VERSION ""

NS_ :

BS_:

BU_:

BO_ 711 CMPD_faultsAndExtras: 8 Vector__XXX
 SG_ CMPD_inputLVVoltage : 56|8@1+ (0.1,0) [0|0] "" Vector__XXX
 SG_ CMPD_inverterTemperature : 48|8@1+ (1,-40) [0|0] "" Vector__XXX
 SG_ CMPD_IGBTTemperature : 40|8@1+ (1,-40) [0|0] "" Vector__XXX
 SG_ CMPD_overloadDetectionOfSpeed : 32|1@1+ (1,0) [0|0] "" Vector__XXX
 SG_ CMPD_overloadRestrictionCurrent : 31|1@1+ (1,0) [0|0] "" Vector__XXX
 SG_ CMPD_overloadLossOfSync : 30|1@1+ (1,0) [0|0] "" Vector__XXX
 SG_ CMPD_overloadStartFaultDetection : 29|1@1+ (1,0) [0|0] "" Vector__XXX
 SG_ CMPD_overloadStatus : 27|2@1+ (1,0) [0|0] "" Vector__XXX
 SG_ CMPD_overCurrent : 26|1@1+ (1,0) [0|0] "" Vector__XXX
 SG_ CMPD_failedStartRepeated : 25|1@1+ (1,0) [0|0] "" Vector__XXX
 SG_ CMPD_failedStart : 24|1@1+ (1,0) [0|0] "" Vector__XXX
 SG_ CMPD_underTemperature : 23|1@1+ (1,0) [0|0] "" Vector__XXX
 SG_ CMPD_overTemperature : 22|1@1+ (1,0) [0|0] "" Vector__XXX
 SG_ CMPD_warnOverTemperature : 21|1@1+ (1,0) [0|0] "" Vector__XXX
 SG_ CMPD_shortCircuit : 20|1@1+ (1,0) [0|0] "" Vector__XXX
 SG_ CMPD_inverterOpenCircuit : 19|1@1+ (1,0) [0|0] "" Vector__XXX
 SG_ CMPD_internalPowerSupplyFault : 18|1@1+ (1,0) [0|0] "" Vector__XXX
 SG_ CMPD_selfTestFailCPU : 17|1@1+ (1,0) [0|0] "" Vector__XXX
 SG_ CMPD_currentSnsError : 16|1@1+ (1,0) [0|0] "" Vector__XXX
 SG_ CMPD_tempSnsFaultCPU : 15|1@1+ (1,0) [0|0] "" Vector__XXX
 SG_ CMPD_tempSnsFaultIPM2 : 14|1@1+ (1,0) [0|0] "" Vector__XXX
 SG_ CMPD_tempSnsFaultIPM1 : 13|1@1+ (1,0) [0|0] "" Vector__XXX
 SG_ CMPD_HVUnderVoltage : 12|1@1+ (1,0) [0|0] "" Vector__XXX
 SG_ CMPD_HVOverVoltage : 11|1@1+ (1,0) [0|0] "" Vector__XXX
 SG_ CMPD_LVOverVoltage : 10|1@1+ (1,0) [0|0] "" Vector__XXX
 SG_ CMPD_LVUnderVoltage : 9|1@1+ (1,0) [0|0] "" Vector__XXX
 SG_ CMPD_VCFRONTCANTimeout : 8|1@1+ (1,0) [0|0] "" Vector__XXX
 SG_ CMPD_limitOverCurrentHVDC : 2|1@1+ (1,0) [0|0] "" Vector__XXX
 SG_ CMPD_limitOverCurrentPhase : 1|1@1+ (1,0) [0|0] "" Vector__XXX
 SG_ CMPD_limitUnderVoltage : 0|1@1+ (1,0) [0|0] "" Vector__XXX

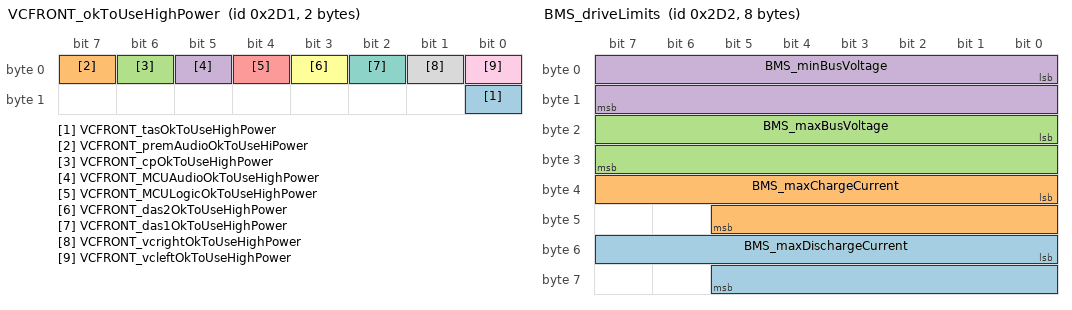
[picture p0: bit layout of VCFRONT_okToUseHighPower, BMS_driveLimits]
BO_ 721 VCFRONT_okToUseHighPower: 2 Vector__XXX
 SG_ VCFRONT_tasOkToUseHighPower : 8|1@1+ (1,0) [0|0] "" Vector__XXX
 SG_ VCFRONT_premAudioOkToUseHiPower : 7|1@1+ (1,0) [0|0] "" Vector__XXX
 SG_ VCFRONT_cpOkToUseHighPower : 6|1@1+ (1,0) [0|0] "" Vector__XXX
 SG_ VCFRONT_MCUAudioOkToUseHighPower : 5|1@1+ (1,0) [0|0] "" Vector__XXX
 SG_ VCFRONT_MCULogicOkToUseHighPower : 4|1@1+ (1,0) [0|0] "" Vector__XXX
 SG_ VCFRONT_das2OkToUseHighPower : 3|1@1+ (1,0) [0|0] "" Vector__XXX
 SG_ VCFRONT_das1OkToUseHighPower : 2|1@1+ (1,0) [0|0] "" Vector__XXX
 SG_ VCFRONT_vcrightOkToUseHighPower : 1|1@1+ (1,0) [0|0] "" Vector__XXX
 SG_ VCFRONT_vcleftOkToUseHighPower : 0|1@1+ (1,0) [0|0] "" Vector__XXX

BO_ 722 BMS_driveLimits: 8 Vector__XXX
 SG_ BMS_maxDischargeCurrent : 48|14@1+ (0.15,0) [0|0] "" Vector__XXX
 SG_ BMS_maxChargeCurrent : 32|14@1+ (0.1,0) [0|0] "" Vector__XXX
 SG_ BMS_maxBusVoltage : 16|16@1+ (0.02,0) [0|0] "" Vector__XXX
 SG_ BMS_minBusVoltage : 0|16@1+ (0.02,0) [0|0] "" Vector__XXX

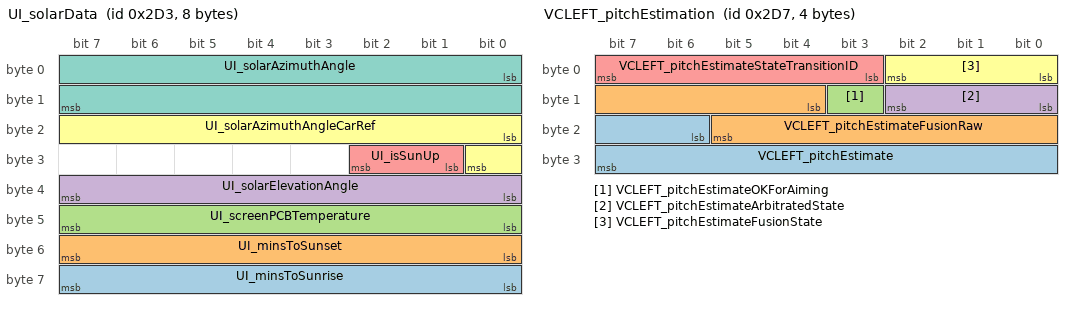
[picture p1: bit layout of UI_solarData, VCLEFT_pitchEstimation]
BO_ 723 UI_solarData: 8 Vector__XXX
 SG_ UI_minsToSunrise : 56|8@1+ (10,0) [0|0] "" Vector__XXX
 SG_ UI_minsToSunset : 48|8@1+ (10,0) [0|0] "" Vector__XXX
 SG_ UI_screenPCBTemperature : 40|8@1- (0.5,40) [0|0] "" Vector__XXX
 SG_ UI_solarElevationAngle : 32|8@1- (1,0) [0|0] "" Vector__XXX
 SG_ UI_isSunUp : 25|2@1+ (1,0) [0|0] "" Vector__XXX
 SG_ UI_solarAzimuthAngleCarRef : 16|9@1- (1,0) [0|0] "" Vector__XXX
 SG_ UI_solarAzimuthAngle : 0|16@1- (1,0) [0|0] "" Vector__XXX

BO_ 727 VCLEFT_pitchEstimation: 4 Vector__XXX
 SG_ VCLEFT_pitchEstimate : 22|10@1- (0.0002,0) [0|0] "" Vector__XXX
 SG_ VCLEFT_pitchEstimateFusionRaw : 12|10@1- (0.0002,0) [0|0] "" Vector__XXX
 SG_ VCLEFT_pitchEstimateOKForAiming : 11|1@1+ (1,0) [0|0] "" Vector__XXX
 SG_ VCLEFT_pitchEstimateArbitratedState : 8|3@1+ (1,0) [0|0] "" Vector__XXX
 SG_ VCLEFT_pitchEstimateStateTransitionID : 3|5@1+ (1,0) [0|0] "" Vector__XXX
 SG_ VCLEFT_pitchEstimateFusionState : 0|3@1+ (1,0) [0|0] "" Vector__XXX

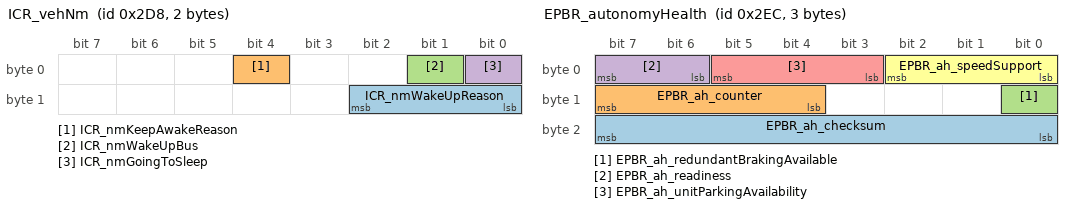
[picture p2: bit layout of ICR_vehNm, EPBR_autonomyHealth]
BO_ 728 ICR_vehNm: 2 Vector__XXX
 SG_ ICR_nmWakeUpReason : 8|3@1+ (1,0) [0|0] "" Vector__XXX
 SG_ ICR_nmKeepAwakeReason : 4|1@1+ (1,0) [0|0] "" Vector__XXX
 SG_ ICR_nmWakeUpBus : 1|1@1+ (1,0) [0|0] "" Vector__XXX
 SG_ ICR_nmGoingToSleep : 0|1@1+ (1,0) [0|0] "" Vector__XXX

BO_ 737 VCFRONT_status: 8 Vector__XXX
 SG_ VCFRONT_isActiveHeatingBattery m0 : 63|1@1+ (1,0) [0|0] "" Vector__XXX
 SG_ VCFRONT_frunkAccessPost m0 : 62|1@1+ (1,0) [0|0] "" Vector__XXX
 SG_ VCFRONT_headlampRightFanStatus m0 : 61|1@1+ (1,0) [0|0] "" Vector__XXX
 SG_ VCFRONT_extendedHvacPerfTestCommand m2 : 60|4@1+ (1,0) [0|0] "" Vector__XXX
 SG_ VCFRONT_headlampLeftFanStatus m0 : 60|1@1+ (1,0) [0|0] "" Vector__XXX
 SG_ VCFRONT_thermalPerfTestRunning m2 : 59|1@1+ (1,0) [0|0] "" Vector__XXX
 SG_ VCFRONT_frunkLatchType m0 : 58|2@1+ (1,0) [0|0] "" Vector__XXX
 SG_ VCFRONT_closeValvesRoutineStatus m2 : 57|2@1+ (1,0) [0|0] "" Vector__XXX
 SG_ VCFRONT_passengerBuckleStatus m0 : 57|1@1+ (1,0) [0|0] "" Vector__XXX
 SG_ VCFRONT_isCOP1Running m2 : 56|1@1+ (1,0) [0|0] "" Vector__XXX
 SG_ VCFRONT_limitedSplitTempDeltaEnforced m1 : 56|1@1+ (1,0) [0|0] "" Vector__XXX
 SG_ VCFRONT_windshieldCameraHeaterPower m4 : 56|6@1+ (2.5,0) [0|0] "" Vector__XXX
 SG_ VCFRONT_hvacReqOffForFasterCharge m1 : 55|1@1+ (1,0) [0|0] "" Vector__XXX
 SG_ VCFRONT_trunkExteriorWakeSwitch m0 : 55|1@1+ (1,0) [0|0] "" Vector__XXX
 SG_ VCFRONT_potentialRadiatorSteamUI m1 : 54|1@1+ (1,0) [0|0] "" Vector__XXX
 SG_ VCFRONT_refrigFillRoutineStatus m2 : 54|2@1+ (1,0) [0|0] "" Vector__XXX
 SG_ VCFRONT_potentialRadiatorSteam m1 : 53|1@1+ (1,0) [0|0] "" Vector__XXX
 SG_ VCFRONT_allowEvapInLowAmbient m1 : 52|1@1+ (1,0) [0|0] "" Vector__XXX
 SG_ VCFRONT_coolantFillRoutineStatus m2 : 52|2@1+ (1,0) [0|0] "" Vector__XXX
 SG_ VCFRONT_logVerbosity m3 : 52|3@1+ (1,0) [0|0] "" Vector__XXX
 SG_ VCFRONT_radarHeaterState m0 : 52|3@1+ (1,0) [0|0] "" Vector__XXX
 SG_ VCFRONT_activeLouverState m4 : 51|5@1+ (1,0) [0|0] "" Vector__XXX
 SG_ VCFRONT_espWakeLine m1 : 51|1@1+ (1,0) [0|0] "" Vector__XXX
 SG_ VCFRONT_hornOn m0 : 51|1@1+ (1,0) [0|0] "" Vector__XXX
 SG_ VCFRONT_anyDoorOpen m0 : 50|1@1+ (1,0) [0|0] "" Vector__XXX
 SG_ VCFRONT_anyClosureOpen m0 : 49|1@1+ (1,0) [0|0] "" Vector__XXX
 SG_ VCFRONT_hvacPerfTestCommand m2 : 49|3@1+ (1,0) [0|0] "" Vector__XXX
 SG_ VCFRONT_closureEasterEggState m1 : 48|3@1+ (1,0) [0|0] "" Vector__XXX
 SG_ VCFRONT_frunkInteriorRelSwitch m0 : 48|1@1+ (1,0) [0|0] "" Vector__XXX
 SG_ VCFRONT_occupantCount m1 : 45|3@1+ (1,0) [0|0] "" Vector__XXX
 SG_ VCFRONT_activeLouverOpenPos m4 : 44|7@1+ (1,0) [0|0] "" Vector__XXX
 SG_ VCFRONT_wiperHeaterState m1 : 42|3@1+ (1,0) [0|0] "" Vector__XXX
 SG_ VCFRONT_frunkLatchCurrent m0 : 40|8@1- (0.15748031496062992,0) [0|0] "" Vector__XXX
 SG_ VCFRONT_pressureRefrigDischarge m2 : 40|9@1+ (0.08,0) [0|0] "" Vector__XXX
 SG_ VCFRONT_vbatProt m3 : 40|12@1+ (0.005443676098,0) [0|0] "" Vector__XXX
 SG_ VCFRONT_wiperECUType m1 : 40|2@1+ (1,0) [0|0] "" Vector__XXX
 SG_ VCFRONT_maxHeatingPowerRightCC m4 : 37|7@1+ (100,0) [0|0] "" Vector__XXX
 SG_ VCFRONT_hibernationState m1 : 36|3@1+ (1,0) [0|0] "" Vector__XXX
 SG_ VCFRONT_wiperLINHealth m0 : 35|3@1+ (1,0) [0|0] "" Vector__XXX
 SG_ VCFRONT_lastUserPresenceUpdateEpochTime m5 : 32|32@1+ (1,0) [0|0] "" Vector__XXX
 SG_ VCFRONT_pressureRefrigSuction m2 : 32|7@1+ (0.125,0) [0|0] "" Vector__XXX
 SG_ VCFRONT_wiperHealth m0 : 32|3@1+ (1,0) [0|0] "" Vector__XXX
 SG_ VCFRONT_isHeatPumpOilPurgeActive m2 : 31|1@1+ (1,0) [0|0] "" Vector__XXX
 SG_ VCFRONT_isColdStartRunning m2 : 30|1@1+ (1,0) [0|0] "" Vector__XXX
 SG_ VCFRONT_maxHeatingPowerLeftCC m4 : 30|7@1+ (100,0) [0|0] "" Vector__XXX
 SG_ VCFRONT_hasLowRefrigerant m2 : 29|1@1+ (1,0) [0|0] "" Vector__XXX
 SG_ VCFRONT_AS8510Voltage m3 : 28|12@1+ (0.005443676098,0) [0|0] "" Vector__XXX
 SG_ VCFRONT_hvacModeNotAttainable m2 : 28|1@1+ (1,0) [0|0] "" Vector__XXX
 SG_ VCFRONT_compPerfRecoveryLimited m2 : 27|1@1+ (1,0) [0|0] "" Vector__XXX
 SG_ VCFRONT_chillerDemandActive m2 : 26|1@1+ (1,0) [0|0] "" Vector__XXX
 SG_ VCFRONT_isEvapOperationAllowed m2 : 25|1@1+ (1,0) [0|0] "" Vector__XXX
 SG_ VCFRONT_crashUnlockOverrideSet m0 : 24|1@1+ (1,0) [0|0] "" Vector__XXX
 SG_ VCFRONT_freezeEvapITerm m2 : 24|1@1+ (1,0) [0|0] "" Vector__XXX
 SG_ VCFRONT_sleepCurrent m1 : 24|12@1+ (0.125,-511.875) [0|0] "" Vector__XXX
 SG_ VCFRONT_crashState m0 : 22|2@1+ (1,0) [0|0] "" Vector__XXX
 SG_ VCFRONT_UP_chargeStateTransitioned m5 : 21|1@1+ (1,0) [0|0] "" Vector__XXX
 SG_ VCFRONT_UP_passengerPresent m5 : 20|1@1+ (1,0) [0|0] "" Vector__XXX
 SG_ VCFRONT_crashDetectedType m0 : 20|2@1+ (1,0) [0|0] "" Vector__XXX
 SG_ VCFRONT_UP_UIUserActivity m5 : 19|1@1+ (1,0) [0|0] "" Vector__XXX
 SG_ VCFRONT_compPowerSupportingPT m4 : 19|11@1+ (10,0) [0|0] "" Vector__XXX
 SG_ VCFRONT_UP_UIChargePortDoorRequest m5 : 18|1@1+ (1,0) [0|0] "" Vector__XXX
 SG_ VCFRONT_UP_chargePortDoorOpen m5 : 17|1@1+ (1,0) [0|0] "" Vector__XXX
 SG_ VCFRONT_UP_brakePressed m5 : 16|1@1+ (1,0) [0|0] "" Vector__XXX
 SG_ VCFRONT_minEvapHeatRejection m2 : 16|8@1+ (15,0) [0|0] "" Vector__XXX
 SG_ VCFRONT_vbatMonitorVoltage m3 : 16|12@1+ (0.005443676098,0) [0|0] "" Vector__XXX
 SG_ VCFRONT_wiperState m0 : 16|4@1+ (1,0) [0|0] "" Vector__XXX
 SG_ VCFRONT_UP_driverPresent m5 : 15|1@1+ (1,0) [0|0] "" Vector__XXX
 SG_ VCFRONT_wiperBlocked m0 : 15|1@1+ (1,0) [0|0] "" Vector__XXX
 SG_ VCFRONT_UP_anyClosureIsOpen m5 : 14|1@1+ (1,0) [0|0] "" Vector__XXX
 SG_ VCFRONT_UP_inTransportMode m5 : 13|1@1+ (1,0) [0|0] "" Vector__XXX
 SG_ VCFRONT_timeSpentSleeping m1 : 13|10@1+ (1,0) [0|0] "" Vector__XXX
 SG_ VCFRONT_HSDInitCompleteU16 m3 : 12|1@1+ (1,0) [0|0] "" Vector__XXX
 SG_ VCFRONT_UP_trunkOpen m5 : 12|1@1+ (1,0) [0|0] "" Vector__XXX
 SG_ VCFRONT_wiperPosition m0 : 12|3@1+ (1,0) [0|0] "" Vector__XXX
 SG_ VCFRONT_HSDInitCompleteU13 m3 : 11|1@1+ (1,0) [0|0] "" Vector__XXX
 SG_ VCFRONT_UP_rearPassengerDoorOpen m5 : 11|1@1+ (1,0) [0|0] "" Vector__XXX
 SG_ VCFRONT_PEResetLineState m3 : 10|1@1+ (1,0) [0|0] "" Vector__XXX
 SG_ VCFRONT_UP_rearDriverDoorOpen m5 : 10|1@1+ (1,0) [0|0] "" Vector__XXX
 SG_ VCFRONT_ChargePumpVoltageStable m3 : 9|1@1+ (1,0) [0|0] "" Vector__XXX
 SG_ VCFRONT_UP_frontPassengerDoorOpen m5 : 9|1@1+ (1,0) [0|0] "" Vector__XXX
 SG_ VCFRONT_UP_frontDriverDoorOpen m5 : 8|1@1+ (1,0) [0|0] "" Vector__XXX
 SG_ VCFRONT_compPowerSupportingHvac m4 : 8|11@1+ (10,0) [0|0] "" Vector__XXX
 SG_ VCFRONT_maxEvapHeatRejection m2 : 8|8@1+ (65,0) [0|0] "" Vector__XXX
 SG_ VCFRONT_railBState m3 : 8|1@1+ (1,0) [0|0] "" Vector__XXX
 SG_ VCFRONT_vehicleStatusDBG m1 : 8|5@1+ (1,0) [0|0] "" Vector__XXX
 SG_ VCFRONT_wiperSpeed m0 : 8|4@1+ (1,0) [0|0] "" Vector__XXX
 SG_ VCFRONT_UP_steeringWheelButtonInteraction m5 : 7|1@1+ (1,0) [0|0] "" Vector__XXX
 SG_ VCFRONT_cabinHeatingCapacityLimited m4 : 7|1@1+ (1,0) [0|0] "" Vector__XXX
 SG_ VCFRONT_railAState m3 : 7|1@1+ (1,0) [0|0] "" Vector__XXX
 SG_ VCFRONT_12VBRailStable m3 : 6|1@1+ (1,0) [0|0] "" Vector__XXX
 SG_ VCFRONT_UP_UIDisplayOnForUser m5 : 6|1@1+ (1,0) [0|0] "" Vector__XXX
 SG_ VCFRONT_cabinCoolingCapacityLimited m4 : 6|1@1+ (1,0) [0|0] "" Vector__XXX
 SG_ VCFRONT_12VARailStable m3 : 5|1@1+ (1,0) [0|0] "" Vector__XXX
 SG_ VCFRONT_UP_inDriveState m5 : 5|1@1+ (1,0) [0|0] "" Vector__XXX
 SG_ VCFRONT_iBoosterStateDBG m1 : 5|3@1+ (1,0) [0|0] "" Vector__XXX
 SG_ VCFRONT_5VBRailStable m3 : 4|1@1+ (1,0) [0|0] "" Vector__XXX
 SG_ VCFRONT_epasWakeLine m1 : 4|1@1+ (1,0) [0|0] "" Vector__XXX
 SG_ VCFRONT_5VARailStable m3 : 3|1@1+ (1,0) [0|0] "" Vector__XXX
 SG_ VCFRONT_frunkLatchStatus m0 : 3|4@1+ (1,0) [0|0] "" Vector__XXX
 SG_ VCFRONT_iBoosterWakeLine m1 : 3|1@1+ (1,0) [0|0] "" Vector__XXX
 SG_ VCFRONT_statusIndex M : 0|3@1+ (1,0) [0|0] "" Vector__XXX

BO_ 738 VCLEFT_seatStatus2: 8 Vector__XXX
 SG_ VC_AH_1RowLeftSeatHeatVentHealth m0 : 62|2@1+ (1,0) [0|0] "" Vector__XXX
 SG_ VC_AH_2RowCenterSeatHeatVentHealth m4 : 62|2@1+ (1,0) [0|0] "" Vector__XXX
 SG_ VC_AH_2RowLeftSeatHeatVentHealth m3 : 62|2@1+ (1,0) [0|0] "" Vector__XXX
 SG_ VC_AH_2RowRightSeatHeatVentHealth m5 : 62|2@1+ (1,0) [0|0] "" Vector__XXX
 SG_ VCLEFT_2RowSeatCenterSwitchVoltage m7 : 54|10@1+ (0.01,0) [0|0] "" Vector__XXX
 SG_ VCLEFT_rearCenterBuckleVoltage m2 : 52|8@1+ (0.02,0) [0|0] "" Vector__XXX
 SG_ VCLEFT_frontSeatHeatPowered m0 : 45|1@1+ (1,0) [0|0] "" Vector__XXX
 SG_ VCLEFT_rearCHeatPowered m4 : 45|1@1+ (1,0) [0|0] "" Vector__XXX
 SG_ VCLEFT_rearLBackHeatPowered m1 : 45|1@1+ (1,0) [0|0] "" Vector__XXX
 SG_ VCLEFT_rearLHeatPowered m3 : 45|1@1+ (1,0) [0|0] "" Vector__XXX
 SG_ VCLEFT_rearRCushionHeatPowered m5 : 45|1@1+ (1,0) [0|0] "" Vector__XXX
 SG_ VCLEFT_2RowSeatEasyEntrySwitchVoltage m7 : 44|10@1+ (0.01,0) [0|0] "" Vector__XXX
 SG_ VCLEFT_frontSeatHeatInhibited m0 : 44|1@1+ (1,0) [0|0] "" Vector__XXX
 SG_ VCLEFT_rearCHeatInhibited m4 : 44|1@1+ (1,0) [0|0] "" Vector__XXX
 SG_ VCLEFT_rearLBackHeatInhibited m1 : 44|1@1+ (1,0) [0|0] "" Vector__XXX
 SG_ VCLEFT_rearLHeatInhibited m3 : 44|1@1+ (1,0) [0|0] "" Vector__XXX
 SG_ VCLEFT_rearRCushionHeatInhibited m5 : 44|1@1+ (1,0) [0|0] "" Vector__XXX
 SG_ VCLEFT_rearRightOccupancyVoltage m2 : 44|8@1+ (0.02,0) [0|0] "" Vector__XXX
 SG_ VCLEFT_2RowSeatCenterActuatorDuty m6 : 40|12@1- (0.1,0) [0|0] "" Vector__XXX
 SG_ VCLEFT_frontSeatHeatTmpTarget m0 : 36|8@1- (0.5,0) [0|0] "" Vector__XXX
 SG_ VCLEFT_rearCHeatTmpTarget m4 : 36|8@1- (0.5,0) [0|0] "" Vector__XXX
 SG_ VCLEFT_rearCenterOccupancyVoltage m2 : 36|8@1+ (0.02,0) [0|0] "" Vector__XXX
 SG_ VCLEFT_rearLBackHeatTmpTarget m1 : 36|8@1- (0.5,0) [0|0] "" Vector__XXX
 SG_ VCLEFT_rearLHeatTmpTarget m3 : 36|8@1- (0.5,0) [0|0] "" Vector__XXX
 SG_ VCLEFT_rearRCushionHeatTmpTarget m5 : 36|8@1- (0.5,0) [0|0] "" Vector__XXX
 SG_ VCLEFT_2RowSeatReclineSwitchVoltage m7 : 34|10@1+ (0.01,0) [0|0] "" Vector__XXX
 SG_ VCLEFT_2RowSeatTrackPositionSwitch m9 : 31|2@1+ (1,0) [0|0] "" Vector__XXX
 SG_ VCLEFT_2RowSeatCenterActuatorCurrent m6 : 28|12@1- (0.01,0) [0|0] "" Vector__XXX
 SG_ VCLEFT_2RowSeatEasyEntryState m9 : 28|3@1+ (1,0) [0|0] "" Vector__XXX
 SG_ VCLEFT_rearLeftOccupancyVoltage m2 : 28|8@1+ (0.02,0) [0|0] "" Vector__XXX
 SG_ VCLEFT_frontSeatHeatTmp m0 : 24|12@1- (0.05,0) [0|0] "" Vector__XXX
 SG_ VCLEFT_frontSeatLiftTiltSwitchVoltage m7 : 24|10@1+ (0.01,0) [0|0] "" Vector__XXX
 SG_ VCLEFT_rearCHeatTmp m4 : 24|12@1- (0.05,0) [0|0] "" Vector__XXX
 SG_ VCLEFT_rearLBackHeatTmp m1 : 24|12@1- (0.05,0) [0|0] "" Vector__XXX
 SG_ VCLEFT_rearLHeatTmp m3 : 24|12@1- (0.05,0) [0|0] "" Vector__XXX
 SG_ VCLEFT_rearRCushionHeatTmp m5 : 24|12@1- (0.05,0) [0|0] "" Vector__XXX
 SG_ VCLEFT_rearLeftBuckleVoltage m2 : 20|8@1+ (0.02,0) [0|0] "" Vector__XXX
 SG_ VCLEFT_2RowSeatReclineActuatorDuty m6 : 16|12@1- (0.1,0) [0|0] "" Vector__XXX
 SG_ VCLEFT_2RowSeatTrackActuatorDuty m9 : 16|12@1- (0.1,0) [0|0] "" Vector__XXX
 SG_ VCLEFT_frontSeatHeatDuty m0 : 16|8@1+ (1,0) [0|0] "" Vector__XXX
 SG_ VCLEFT_rearCHeatDuty m4 : 16|8@1+ (1,0) [0|0] "" Vector__XXX
 SG_ VCLEFT_rearLBackHeatDuty m1 : 16|8@1+ (1,0) [0|0] "" Vector__XXX
 SG_ VCLEFT_rearLHeatDuty m3 : 16|8@1+ (1,0) [0|0] "" Vector__XXX
 SG_ VCLEFT_rearRCushionHeatDuty m5 : 16|8@1+ (1,0) [0|0] "" Vector__XXX
 SG_ VCLEFT_frontSeatLumbarSwitchVoltage m7 : 14|10@1+ (0.01,0) [0|0] "" Vector__XXX
 SG_ VCLEFT_trunkFoldFlatRightSwitchVoltage m8 : 14|10@1+ (0.01,0) [0|0] "" Vector__XXX
 SG_ VCLEFT_frontBuckleVoltage m2 : 12|8@1+ (0.02,0) [0|0] "" Vector__XXX
 SG_ VCLEFT_2RowSeatReclineActuatorCurrent m6 : 4|12@1- (0.01,0) [0|0] "" Vector__XXX
 SG_ VCLEFT_2RowSeatTrackActuatorCurrent m9 : 4|12@1- (0.01,0) [0|0] "" Vector__XXX
 SG_ VCLEFT_frontOccupancyVoltage m2 : 4|8@1+ (0.02,0) [0|0] "" Vector__XXX
 SG_ VCLEFT_frontSeatHeatCurrent m0 : 4|12@1+ (0.01,0) [0|0] "" Vector__XXX
 SG_ VCLEFT_frontSeatTrackBackrestSwitchVoltage m7 : 4|10@1+ (0.01,0) [0|0] "" Vector__XXX
 SG_ VCLEFT_rearCHeatCurrent m4 : 4|12@1+ (0.01,0) [0|0] "" Vector__XXX
 SG_ VCLEFT_rearLBackHeatCurrent m1 : 4|12@1+ (0.01,0) [0|0] "" Vector__XXX
 SG_ VCLEFT_rearLHeatCurrent m3 : 4|12@1+ (0.01,0) [0|0] "" Vector__XXX
 SG_ VCLEFT_rearRCushionHeatCurrent m5 : 4|12@1+ (0.01,0) [0|0] "" Vector__XXX
 SG_ VCLEFT_trunkFoldFlatLeftSwitchVoltage m8 : 4|10@1+ (0.004887585532746823,0) [0|0] "" Vector__XXX
 SG_ VCLEFT_seatStatus2Index M : 0|4@1+ (1,0) [0|0] "" Vector__XXX

BO_ 739 VCRIGHT_seatStatus2: 7 Vector__XXX
 SG_ VC_AH_1RowRightSeatHeatVentHealth m0 : 54|2@1+ (1,0) [0|0] "" Vector__XXX
 SG_ VCRIGHT_occupantClassificationHoldState m4 : 46|2@1+ (1,0) [0|0] "" Vector__XXX
 SG_ VCRIGHT_frontSeatHeatPowered m0 : 45|1@1+ (1,0) [0|0] "" Vector__XXX
 SG_ VCRIGHT_rearCSeatHeatPowered m2 : 45|1@1+ (1,0) [0|0] "" Vector__XXX
 SG_ VCRIGHT_rearLSeatHeatPowered m1 : 45|1@1+ (1,0) [0|0] "" Vector__XXX
 SG_ VCRIGHT_rearRSeatHeatPowered m3 : 45|1@1+ (1,0) [0|0] "" Vector__XXX
 SG_ VCRIGHT_2RowSeatEasyEntrySwitchVoltage m7 : 44|10@1+ (0.01,0) [0|0] "" Vector__XXX
 SG_ VCRIGHT_frontSeatHeatInhibited m0 : 44|1@1+ (1,0) [0|0] "" Vector__XXX
 SG_ VCRIGHT_rearCSeatHeatInhibited m2 : 44|1@1+ (1,0) [0|0] "" Vector__XXX
 SG_ VCRIGHT_rearLSeatHeatInhibited m1 : 44|1@1+ (1,0) [0|0] "" Vector__XXX
 SG_ VCRIGHT_rearRSeatHeatInhibited m3 : 44|1@1+ (1,0) [0|0] "" Vector__XXX
 SG_ VCRIGHT_frontSeatHeatTmpTarget m0 : 36|8@1- (0.5,0) [0|0] "" Vector__XXX
 SG_ VCRIGHT_rearCSeatHeatTmpTarget m2 : 36|8@1- (0.5,0) [0|0] "" Vector__XXX
 SG_ VCRIGHT_rearLSeatHeatTmpTarget m1 : 36|8@1- (0.5,0) [0|0] "" Vector__XXX
 SG_ VCRIGHT_rearRSeatHeatTmpTarget m3 : 36|8@1- (0.5,0) [0|0] "" Vector__XXX
 SG_ VCRIGHT_2RowSeatReclineSwitchVoltage m7 : 34|10@1+ (0.01,0) [0|0] "" Vector__XXX
 SG_ VCRIGHT_rearRightBuckleVoltage m4 : 34|10@1+ (0.01,0) [0|0] "" Vector__XXX
 SG_ VCRIGHT_ocsIEEState m10 : 32|3@1+ (1,0) [0|0] "" Vector__XXX
 SG_ VCRIGHT_2RowSeatTrackPositionSwitch m9 : 31|2@1+ (1,0) [0|0] "" Vector__XXX
 SG_ VCRIGHT_2RowSeatEasyEntryState m9 : 28|3@1+ (1,0) [0|0] "" Vector__XXX
 SG_ VCRIGHT_3RUSBPortsCurrentAvg m6 : 28|8@1+ (0.01,0) [0|0] "" Vector__XXX
 SG_ VCRIGHT_frontSeatHeatTmp m0 : 24|12@1- (0.05,0) [0|0] "" Vector__XXX
 SG_ VCRIGHT_frontSeatLiftTiltSwitchVoltage m7 : 24|10@1+ (0.01,0) [0|0] "" Vector__XXX
 SG_ VCRIGHT_rearCSeatHeatTmp m2 : 24|12@1- (0.05,0) [0|0] "" Vector__XXX
 SG_ VCRIGHT_rearCenterBuckleVoltage m4 : 24|10@1+ (0.01,0) [0|0] "" Vector__XXX
 SG_ VCRIGHT_rearLSeatHeatTmp m1 : 24|12@1- (0.05,0) [0|0] "" Vector__XXX
 SG_ VCRIGHT_rearRSeatHeatTmp m3 : 24|12@1- (0.05,0) [0|0] "" Vector__XXX
 SG_ VCRIGHT_ocsIEEPowerCurrent m10 : 20|12@1+ (0.001,0) [0|0] "" Vector__XXX
 SG_ VCRIGHT_ocsIEESnsrPassSeatCalRespSts m10 : 18|2@1+ (1,0) [0|0] "" Vector__XXX
 SG_ VCRIGHT_ocsIEEReqOfClrOfFlt m10 : 17|1@1+ (1,0) [0|0] "" Vector__XXX
 SG_ VCRIGHT_2RowSeatReclineActuatorDuty m6 : 16|12@1- (0.1,0) [0|0] "" Vector__XXX
 SG_ VCRIGHT_2RowSeatTrackActuatorDuty m9 : 16|12@1- (0.1,0) [0|0] "" Vector__XXX
 SG_ VCRIGHT_frontSeatHeatDuty m0 : 16|8@1+ (1,0) [0|0] "" Vector__XXX
 SG_ VCRIGHT_ocsIEEReqOfPassSeatCal m10 : 16|1@1+ (1,0) [0|0] "" Vector__XXX
 SG_ VCRIGHT_rearCSeatHeatDuty m2 : 16|8@1+ (1,0) [0|0] "" Vector__XXX
 SG_ VCRIGHT_rearLSeatHeatDuty m1 : 16|8@1+ (1,0) [0|0] "" Vector__XXX
 SG_ VCRIGHT_rearRSeatHeatDuty m3 : 16|8@1+ (1,0) [0|0] "" Vector__XXX
 SG_ VCRIGHT_ocsIEEFltResp8 m10 : 15|1@1+ (1,0) [0|0] "" Vector__XXX
 SG_ VCRIGHT_3RowSeatRightReclineSwitchVoltage m8 : 14|10@1+ (0.01,0) [0|0] "" Vector__XXX
 SG_ VCRIGHT_frontBuckleVoltage m4 : 14|10@1+ (0.01,0) [0|0] "" Vector__XXX
 SG_ VCRIGHT_frontSeatLumbarSwitchVoltage m7 : 14|10@1+ (0.01,0) [0|0] "" Vector__XXX
 SG_ VCRIGHT_ocsIEEFltResp7 m10 : 14|1@1+ (1,0) [0|0] "" Vector__XXX
 SG_ VCRIGHT_ocsIEEFltResp6 m10 : 13|1@1+ (1,0) [0|0] "" Vector__XXX
 SG_ VCRIGHT_ocsIEEFltResp5 m10 : 12|1@1+ (1,0) [0|0] "" Vector__XXX
 SG_ VCRIGHT_ocsIEEFltResp4 m10 : 11|1@1+ (1,0) [0|0] "" Vector__XXX
 SG_ VCRIGHT_ocsIEEFltResp3 m10 : 10|1@1+ (1,0) [0|0] "" Vector__XXX
 SG_ VCRIGHT_ocsIEEFltResp2 m10 : 9|1@1+ (1,0) [0|0] "" Vector__XXX
 SG_ VCRIGHT_ocsIEEFltResp1 m10 : 8|1@1+ (1,0) [0|0] "" Vector__XXX
 SG_ VCRIGHT_ocsIEEMIA m10 : 7|1@1+ (1,0) [0|0] "" Vector__XXX
 SG_ VCRIGHT_ocsIEEEcuFailr m10 : 6|1@1+ (1,0) [0|0] "" Vector__XXX
 SG_ VCRIGHT_2RowSeatReclineActuatorCurrent m6 : 4|12@1- (0.01,0) [0|0] "" Vector__XXX
 SG_ VCRIGHT_2RowSeatTrackActuatorCurrent m9 : 4|12@1- (0.01,0) [0|0] "" Vector__XXX
 SG_ VCRIGHT_3RowSeatLeftReclineSwitchVoltage m8 : 4|10@1+ (0.01,0) [0|0] "" Vector__XXX
 SG_ VCRIGHT_frontOccupancyVoltage m4 : 4|10@1+ (0.01,0) [0|0] "" Vector__XXX
 SG_ VCRIGHT_frontSeatHeatCurrent m0 : 4|12@1+ (0.01,0) [0|0] "" Vector__XXX
 SG_ VCRIGHT_frontSeatTrackBackrestSwitchVoltage m7 : 4|10@1+ (0.01,0) [0|0] "" Vector__XXX
 SG_ VCRIGHT_ocsIEEAirbAllwdSts m10 : 4|2@1+ (1,0) [0|0] "" Vector__XXX
 SG_ VCRIGHT_rearCSeatHeatCurrent m2 : 4|12@1+ (0.01,0) [0|0] "" Vector__XXX
 SG_ VCRIGHT_rearLSeatHeatCurrent m1 : 4|12@1+ (0.01,0) [0|0] "" Vector__XXX
 SG_ VCRIGHT_rearRSeatHeatCurrent m3 : 4|12@1+ (0.01,0) [0|0] "" Vector__XXX
 SG_ VCRIGHT_seatStatus2Index M : 0|4@1+ (1,0) [0|0] "" Vector__XXX

BO_ 744 EPBR_status: 8 Vector__XXX
 SG_ EPBR_statusChecksum : 56|8@1+ (1,0) [0|0] "" Vector__XXX
 SG_ EPBR_statusCounter : 52|4@1+ (1,0) [0|0] "" Vector__XXX
 SG_ EPBR_blockDrive : 51|1@1+ (1,0) [0|0] "" Vector__XXX
 SG_ EPBR_bothDisconnected : 50|1@1+ (1,0) [0|0] "" Vector__XXX
 SG_ EPBR_winchModeAvailable : 49|1@1+ (1,0) [0|0] "" Vector__XXX
 SG_ EPBR_hornRequest : 48|1@1+ (1,0) [0|0] "" Vector__XXX
 SG_ EPBR_okToPark : 47|1@1+ (1,0) [0|0] "" Vector__XXX
 SG_ EPBR_espPowerRequest : 46|1@1+ (1,0) [0|0] "" Vector__XXX
 SG_ EPBR_showStalkFaultedOnUi : 45|1@1+ (1,0) [0|0] "" Vector__XXX
 SG_ EPBR_autonomyBehavior : 43|2@1+ (1,0) [0|0] "" Vector__XXX
 SG_ EPBR_contactorCycleNotNeededForWinchEntry : 35|1@1+ (1,0) [0|0] "" Vector__XXX
 SG_ EPBR_uiWinchModeLvStatus : 33|2@1+ (1,0) [0|0] "" Vector__XXX
 SG_ EPBR_showUiGearShifter : 32|1@1+ (1,0) [0|0] "" Vector__XXX
 SG_ EPBR_brakeDiscWipeRequest : 30|2@1+ (1,0) [0|0] "" Vector__XXX
 SG_ EPBR_uiParkAvailable : 28|2@1+ (1,0) [0|0] "" Vector__XXX
 SG_ EPBR_cdpRequest : 27|1@1+ (1,0) [0|0] "" Vector__XXX
 SG_ EPBR_winchModePending : 26|1@1+ (1,0) [0|0] "" Vector__XXX
 SG_ EPBR_winchModePermissive : 25|1@1+ (1,0) [0|0] "" Vector__XXX
 SG_ EPBR_updateMode : 24|1@1+ (1,0) [0|0] "" Vector__XXX
 SG_ EPBR_winchModeActive : 23|1@1+ (1,0) [0|0] "" Vector__XXX
 SG_ EPBR_uiWinchModeMiscBlocking : 22|1@1+ (1,0) [0|0] "" Vector__XXX
 SG_ EPBR_requestUserConfirmation : 21|1@1+ (1,0) [0|0] "" Vector__XXX
 SG_ EPBR_brakeConfirmedPressed : 20|1@1+ (1,0) [0|0] "" Vector__XXX
 SG_ EPBR_epbConfigMismatch : 19|1@1+ (1,0) [0|0] "" Vector__XXX
 SG_ EPBR_brakeLight : 18|1@1+ (1,0) [0|0] "" Vector__XXX
 SG_ EPBR_summonEnabled : 17|1@1+ (1,0) [0|0] "" Vector__XXX
 SG_ EPBR_redundantBrakingEnabled : 16|1@1+ (1,0) [0|0] "" Vector__XXX
 SG_ EPBR_audioCurrentSpikeDetected : 15|1@1+ (1,0) [0|0] "" Vector__XXX
 SG_ EPBR_telltale : 12|3@1+ (1,0) [0|0] "" Vector__XXX
 SG_ EPBR_chimeRequest : 9|3@1+ (1,0) [0|0] "" Vector__XXX
 SG_ EPBR_systemCdpAvailable : 8|1@1+ (1,0) [0|0] "" Vector__XXX
 SG_ EPBR_driverIsLeavingAnySpeed : 7|1@1+ (1,0) [0|0] "" Vector__XXX
 SG_ EPBR_driverIsLeaving : 6|1@1+ (1,0) [0|0] "" Vector__XXX
 SG_ EPBR_freeRollModeStatus : 4|2@1+ (1,0) [0|0] "" Vector__XXX
 SG_ EPBR_systemStatus : 0|4@1+ (1,0) [0|0] "" Vector__XXX

BO_ 748 EPBR_autonomyHealth: 3 Vector__XXX
 SG_ EPBR_ah_checksum : 16|8@1+ (1,0) [0|0] "" Vector__XXX
 SG_ EPBR_ah_counter : 12|4@1+ (1,0) [0|0] "" Vector__XXX
 SG_ EPBR_ah_redundantBrakingAvailable : 8|1@1+ (1,0) [0|0] "" Vector__XXX
 SG_ EPBR_ah_readiness : 6|2@1+ (1,0) [0|0] "" Vector__XXX
 SG_ EPBR_ah_unitParkingAvailability : 3|3@1+ (1,0) [0|0] "" Vector__XXX
 SG_ EPBR_ah_speedSupport : 0|3@1+ (1,0) [0|0] "" Vector__XXX

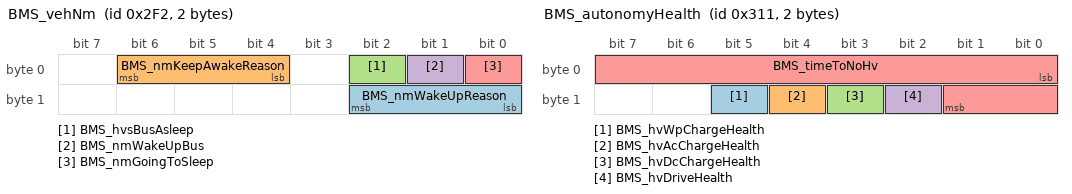
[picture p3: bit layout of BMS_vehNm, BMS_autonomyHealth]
BO_ 754 BMS_vehNm: 2 Vector__XXX
 SG_ BMS_nmWakeUpReason : 8|3@1+ (1,0) [0|0] "" Vector__XXX
 SG_ BMS_nmKeepAwakeReason : 4|3@1+ (1,0) [0|0] "" Vector__XXX
 SG_ BMS_hvsBusAsleep : 2|1@1+ (1,0) [0|0] "" Vector__XXX
 SG_ BMS_nmWakeUpBus : 1|1@1+ (1,0) [0|0] "" Vector__XXX
 SG_ BMS_nmGoingToSleep : 0|1@1+ (1,0) [0|0] "" Vector__XXX

BO_ 755 UI_hvacRequest: 8 Vector__XXX
 SG_ UI_enableHvacLimpMode : 63|1@1+ (1,0) [0|0] "" Vector__XXX
 SG_ UI_enableHvacAPFoggingMonitor : 62|1@1+ (1,0) [0|0] "" Vector__XXX
 SG_ UI_enableHvacControlsFeatures2 : 61|1@1+ (1,0) [0|0] "" Vector__XXX
 SG_ UI_hvacClimateNudgeStatus : 58|3@1+ (1,0) [0|0] "" Vector__XXX
 SG_ UI_hvacReqTempSetpointCOP : 56|2@1+ (1,0) [0|0] "" Vector__XXX
 SG_ UI_enableHvacWeatherDataBasedHumidityControls : 55|1@1+ (1,0) [0|0] "" Vector__XXX
 SG_ UI_evapDryingSelectiveEnable : 54|1@1+ (1,0) [0|0] "" Vector__XXX
 SG_ UI_enableCustomerTHSAlerts : 53|1@1+ (1,0) [0|0] "" Vector__XXX
 SG_ UI_enableHvacVOCPurgeRoutine : 47|1@1+ (1,0) [0|0] "" Vector__XXX
 SG_ UI_hvacPhoneCallAirFlowAdjustEnabled : 46|1@1+ (1,0) [0|0] "" Vector__XXX
 SG_ UI_enableHvacNotifications : 45|1@1+ (1,0) [0|0] "" Vector__XXX
 SG_ UI_enableHvacControlsFeatures1 : 44|1@1+ (1,0) [0|0] "" Vector__XXX
 SG_ UI_hvacLatchPassengerPresent : 39|1@1+ (1,0) [0|0] "" Vector__XXX
 SG_ UI_hvacReqBioWeaponDefMode : 35|1@1+ (1,0) [0|0] "" Vector__XXX
 SG_ UI_hvacReqKeepClimateOn : 33|2@1+ (1,0) [0|0] "" Vector__XXX
 SG_ UI_hvacUseModeledDuctTemp : 32|1@1+ (1,0) [0|0] "" Vector__XXX
 SG_ UI_hvacReqSecondRowState : 29|3@1+ (1,0) [0|0] "" Vector__XXX
 SG_ UI_hvacReqUserPowerState : 26|3@1+ (1,0) [0|0] "" Vector__XXX
 SG_ UI_hvacDefogState : 24|2@1+ (1,0) [0|0] "" Vector__XXX
 SG_ UI_hvacReqACDisable : 22|2@1+ (1,0) [0|0] "" Vector__XXX
 SG_ UI_hvacReqRecirc : 20|2@1+ (1,0) [0|0] "" Vector__XXX
 SG_ UI_hvacReqBlowerSegment : 16|4@1+ (1,0) [0|0] "" Vector__XXX
 SG_ UI_hvacReqAirDistributionMode : 13|3@1+ (1,0) [0|0] "" Vector__XXX
 SG_ UI_hvacReqTempSetpointRight : 8|5@1+ (0.5,15) [0|0] "" Vector__XXX
 SG_ UI_hvacReqAutoBlowerLevel : 5|3@1+ (1,0) [0|0] "" Vector__XXX
 SG_ UI_hvacReqTempSetpointLeft : 0|5@1+ (0.5,15) [0|0] "" Vector__XXX

BO_ 761 VCSEC_additionalAuthInfo: 8 Vector__XXX
 SG_ VCSEC_NFCAuthFromCenterConsoleFormFactor m5 : 35|3@1+ (1,0) [0|0] "" Vector__XXX
 SG_ VCSEC_BLEDeviceWithinSummonRange m4 : 32|32@1+ (1,0) [0|0] "" Vector__XXX
 SG_ VCSEC_NFCAuthFromBPillarFormFactor m5 : 32|3@1+ (1,0) [0|0] "" Vector__XXX
 SG_ VCSEC_activeKeySHA1 m0 : 32|32@1+ (1,0) [0|0] "" Vector__XXX
 SG_ VCSEC_keyWithinSummonRange0 m1 : 32|32@1+ (1,0) [0|0] "" Vector__XXX
 SG_ VCSEC_keyWithinSummonRange1 m2 : 32|32@1+ (1,0) [0|0] "" Vector__XXX
 SG_ VCSEC_keyWithinSummonRange2 m3 : 32|32@1+ (1,0) [0|0] "" Vector__XXX
 SG_ VCSEC_AdditionalAuthInfoIndex M : 27|3@1+ (1,0) [0|0] "" Vector__XXX
 SG_ VCSEC_activeKeyReason m0 : 24|3@1+ (1,0) [0|0] "" Vector__XXX
 SG_ VCSEC_bleConnetionAttemptWLEntry : 19|5@1+ (1,0) [0|0] "" Vector__XXX
 SG_ VCSEC_bleDisconnectionReason : 11|8@1+ (1,0) [0|0] "" Vector__XXX
 SG_ VCSEC_bleChannelDisconnected : 7|4@1+ (1,0) [0|0] "" Vector__XXX
 SG_ VCSEC_activeKeyDebug : 2|5@1+ (1,0) [0|0] "" Vector__XXX
 SG_ VCSEC_algoUsedForSummonRange0 m1 : 0|1@1+ (1,0) [0|0] "" Vector__XXX
 SG_ VCSEC_algoUsedForSummonRange1 m2 : 0|1@1+ (1,0) [0|0] "" Vector__XXX
 SG_ VCSEC_algoUsedForSummonRange2 m3 : 0|1@1+ (1,0) [0|0] "" Vector__XXX

BO_ 768 BMS_info: 8 Vector__XXX
 SG_ BMS_componentId m10 : 48|16@1+ (1,0) [0|0] "" Vector__XXX
 SG_ BMS_subUsageId m11 : 48|16@1+ (1,0) [0|0] "" Vector__XXX
 SG_ BMS_appCrc m13 : 32|32@1+ (1,0) [0|0] "" Vector__XXX
 SG_ BMS_bootCrc m20 : 32|32@1+ (1,0) [0|0] "" Vector__XXX
 SG_ BMS_hardwareId m10 : 32|16@1+ (1,0) [0|0] "" Vector__XXX
 SG_ BMS_usageId m11 : 32|16@1+ (1,0) [0|0] "" Vector__XXX
 SG_ BMS_assemblyId m11 : 24|8@1+ (1,0) [0|0] "" Vector__XXX
 SG_ BMS_buildConfigId m10 : 16|16@1+ (1,0) [0|0] "" Vector__XXX
 SG_ BMS_pcbaId m11 : 16|8@1+ (1,0) [0|0] "" Vector__XXX
 SG_ BMS_appGitHash m17 : 8|56@1+ (1,0) [0|0] "" Vector__XXX
 SG_ BMS_bootGitHash m18 : 8|56@1+ (1,0) [0|0] "" Vector__XXX
 SG_ BMS_bootUdsProtoVersion m20 : 8|8@1+ (1,0) [0|0] "" Vector__XXX
 SG_ BMS_buildType m10 : 8|3@1+ (1,0) [0|0] "" Vector__XXX
 SG_ BMS_platformType m13 : 8|8@1+ (1,0) [0|0] "" Vector__XXX
 SG_ BMS_infoIndex M : 0|8@1+ (1,0) [0|0] "" Vector__XXX

BO_ 769 VCFRONT_info: 8 Vector__XXX
 SG_ VCFRONT_infoComponentId m10 : 48|16@1+ (1,0) [0|0] "" Vector__XXX
 SG_ VCFRONT_infoSubUsageId m11 : 40|16@1+ (1,0) [0|0] "" Vector__XXX
 SG_ VCFRONT_infoBattPumpAppCRC m32 : 32|32@1+ (1,0) [0|0] "" Vector__XXX
 SG_ VCFRONT_infoFanAppCRC m34 : 32|32@1+ (1,0) [0|0] "" Vector__XXX
 SG_ VCFRONT_infoHardwareId m10 : 32|16@1+ (1,0) [0|0] "" Vector__XXX
 SG_ VCFRONT_infoPtPumpAppCRC m33 : 32|32@1+ (1,0) [0|0] "" Vector__XXX
 SG_ VCFRONT_infoSubcomponent10 m37 : 32|32@1+ (1,0) [0|0] "" Vector__XXX
 SG_ VCFRONT_infoSubcomponent11 m38 : 32|32@1+ (1,0) [0|0] "" Vector__XXX
 SG_ VCFRONT_infoSubcomponent12 m39 : 32|32@1+ (1,0) [0|0] "" Vector__XXX
 SG_ VCFRONT_infoSubcomponent13 m40 : 32|32@1+ (1,0) [0|0] "" Vector__XXX
 SG_ VCFRONT_infoSubcomponent14 m41 : 32|32@1+ (1,0) [0|0] "" Vector__XXX
 SG_ VCFRONT_infoSubcomponent3 m24 : 32|32@1+ (1,0) [0|0] "" Vector__XXX
 SG_ VCFRONT_infoSubcomponent8 m35 : 32|32@1+ (1,0) [0|0] "" Vector__XXX
 SG_ VCFRONT_infoSubcomponent9 m36 : 32|32@1+ (1,0) [0|0] "" Vector__XXX
 SG_ VC_infoHCMLAppCRC m16 : 32|32@1+ (1,0) [0|0] "" Vector__XXX
 SG_ VC_infoHCMRAppCRC m23 : 32|32@1+ (1,0) [0|0] "" Vector__XXX
 SG_ VC_infoWiperAppCRC m31 : 32|32@1+ (1,0) [0|0] "" Vector__XXX
 SG_ VCFRONT_infoBootCrc m20 : 24|32@1+ (1,0) [0|0] "" Vector__XXX
 SG_ VCFRONT_infoUsageId m11 : 24|16@1+ (1,0) [0|0] "" Vector__XXX
 SG_ VCFRONT_infoAssemblyId m11 : 16|8@1+ (1,0) [0|0] "" Vector__XXX
 SG_ VCFRONT_infoBuildConfigId m10 : 16|16@1+ (1,0) [0|0] "" Vector__XXX
 SG_ VCFRONT_infoAppCrc m13 : 8|32@1+ (1,0) [0|0] "" Vector__XXX
 SG_ VCFRONT_infoAppGitHash m17 : 8|56@1+ (1,0) [0|0] "" Vector__XXX
 SG_ VCFRONT_infoBootGitHash m18 : 8|56@1+ (1,0) [0|0] "" Vector__XXX
 SG_ VCFRONT_infoBootUdsProtoVersion m20 : 8|16@1+ (1,0) [0|0] "" Vector__XXX
 SG_ VCFRONT_infoBuildType m10 : 8|3@1+ (1,0) [0|0] "" Vector__XXX
 SG_ VCFRONT_infoPcbaId m11 : 8|8@1+ (1,0) [0|0] "" Vector__XXX
 SG_ VCFRONT_infoPlatformType m19 : 8|8@1+ (1,0) [0|0] "" Vector__XXX
 SG_ VCFRONT_infoIndex M : 0|8@1+ (1,0) [0|0] "" Vector__XXX

BO_ 770 VCLEFT_info: 8 Vector__XXX
 SG_ VCLEFT_infoComponentId m10 : 48|16@1+ (1,0) [0|0] "" Vector__XXX
 SG_ VCLEFT_infoSubUsageId m11 : 40|16@1+ (1,0) [0|0] "" Vector__XXX
 SG_ VCLEFT_infoCBCAppCRC m31 : 32|32@1+ (1,0) [0|0] "" Vector__XXX
 SG_ VCLEFT_infoHardwareId m10 : 32|16@1+ (1,0) [0|0] "" Vector__XXX
 SG_ VCLEFT_infoLUMBARLAppCRC m16 : 32|32@1+ (1,0) [0|0] "" Vector__XXX
 SG_ VCLEFT_infoRGBIPFLAppCRC m38 : 32|32@1+ (1,0) [0|0] "" Vector__XXX
 SG_ VCLEFT_infoRGBIPFRAppCRC m39 : 32|32@1+ (1,0) [0|0] "" Vector__XXX
 SG_ VCLEFT_infoSubcomponent3 m24 : 32|32@1+ (1,0) [0|0] "" Vector__XXX
 SG_ VCLEFT_infoTLCAppCRC m33 : 32|32@1+ (1,0) [0|0] "" Vector__XXX
 SG_ VCLEFT_infoVCUSBAppCRC m32 : 32|32@1+ (1,0) [0|0] "" Vector__XXX
 SG_ VCLEFT_swcAppCRC m23 : 32|32@1+ (1,0) [0|0] "" Vector__XXX
 SG_ VCLEFT_infoBootCrc m20 : 24|32@1+ (1,0) [0|0] "" Vector__XXX
 SG_ VCLEFT_infoUsageId m11 : 24|16@1+ (1,0) [0|0] "" Vector__XXX
 SG_ VCLEFT_infoAssemblyId m11 : 16|8@1+ (1,0) [0|0] "" Vector__XXX
 SG_ VCLEFT_infoBuildConfigId m10 : 16|16@1+ (1,0) [0|0] "" Vector__XXX
 SG_ VCLEFT_infoAppCrc m13 : 8|32@1+ (1,0) [0|0] "" Vector__XXX
 SG_ VCLEFT_infoAppGitHash m17 : 8|56@1+ (1,0) [0|0] "" Vector__XXX
 SG_ VCLEFT_infoBootGitHash m18 : 8|56@1+ (1,0) [0|0] "" Vector__XXX
 SG_ VCLEFT_infoBootUdsProtoVersion m20 : 8|16@1+ (1,0) [0|0] "" Vector__XXX
 SG_ VCLEFT_infoBuildType m10 : 8|3@1+ (1,0) [0|0] "" Vector__XXX
 SG_ VCLEFT_infoPcbaId m11 : 8|8@1+ (1,0) [0|0] "" Vector__XXX
 SG_ VCLEFT_infoPlatformType m19 : 8|8@1+ (1,0) [0|0] "" Vector__XXX
 SG_ VCLEFT_infoIndex M : 0|8@1+ (1,0) [0|0] "" Vector__XXX

BO_ 771 VCRIGHT_info: 8 Vector__XXX
 SG_ VCRIGHT_infoComponentId m10 : 48|16@1+ (1,0) [0|0] "" Vector__XXX
 SG_ VCRIGHT_infoSubUsageId m11 : 40|16@1+ (1,0) [0|0] "" Vector__XXX
 SG_ VCRIGHT_infoHardwareId m10 : 32|16@1+ (1,0) [0|0] "" Vector__XXX
 SG_ VCRIGHT_infoLUMBARRAppCRC m16 : 32|32@1+ (1,0) [0|0] "" Vector__XXX
 SG_ VCRIGHT_infoSubcomponent3 m24 : 32|32@1+ (1,0) [0|0] "" Vector__XXX
 SG_ VCRIGHT_infoSubcomponent4 m31 : 32|32@1+ (1,0) [0|0] "" Vector__XXX
 SG_ VCRIGHT_infoSubcomponent5 m32 : 32|32@1+ (1,0) [0|0] "" Vector__XXX
 SG_ VCRIGHT_infoSubcomponent6 m33 : 32|32@1+ (1,0) [0|0] "" Vector__XXX
 SG_ VCRIGHT_thsAppCRC m23 : 32|32@1+ (1,0) [0|0] "" Vector__XXX
 SG_ VCRIGHT_infoBootCrc m20 : 24|32@1+ (1,0) [0|0] "" Vector__XXX
 SG_ VCRIGHT_infoUsageId m11 : 24|16@1+ (1,0) [0|0] "" Vector__XXX
 SG_ VCRIGHT_infoAssemblyId m11 : 16|8@1+ (1,0) [0|0] "" Vector__XXX
 SG_ VCRIGHT_infoBuildConfigId m10 : 16|16@1+ (1,0) [0|0] "" Vector__XXX
 SG_ VCRIGHT_infoAppCrc m13 : 8|32@1+ (1,0) [0|0] "" Vector__XXX
 SG_ VCRIGHT_infoAppGitHash m17 : 8|56@1+ (1,0) [0|0] "" Vector__XXX
 SG_ VCRIGHT_infoBootGitHash m18 : 8|56@1+ (1,0) [0|0] "" Vector__XXX
 SG_ VCRIGHT_infoBootUdsProtoVersion m20 : 8|16@1+ (1,0) [0|0] "" Vector__XXX
 SG_ VCRIGHT_infoBuildType m10 : 8|3@1+ (1,0) [0|0] "" Vector__XXX
 SG_ VCRIGHT_infoPcbaId m11 : 8|8@1+ (1,0) [0|0] "" Vector__XXX
 SG_ VCRIGHT_infoPlatformType m19 : 8|8@1+ (1,0) [0|0] "" Vector__XXX
 SG_ VCRIGHT_infoIndex M : 0|8@1+ (1,0) [0|0] "" Vector__XXX

BO_ 776 OCS1P_status: 8 Vector__XXX
 SG_ OCS1P_statusChecksum : 56|8@1+ (1,0) [0|0] "" Vector__XXX
 SG_ OCS1P_statusCounter : 52|4@1+ (1,0) [0|0] "" Vector__XXX
 SG_ OCS1P_classificationHeldCap : 51|1@1+ (1,0) [0|0] "" Vector__XXX
 SG_ OCS1P_seatbackStableCap : 50|1@1+ (1,0) [0|0] "" Vector__XXX
 SG_ OCS1P_cushionStableCap : 49|1@1+ (1,0) [0|0] "" Vector__XXX
 SG_ OCS1P_sandwichStable : 48|1@1+ (1,0) [0|0] "" Vector__XXX
 SG_ OCS1P_seatbackStable : 47|1@1+ (1,0) [0|0] "" Vector__XXX
 SG_ OCS1P_occupiedStateCap : 45|2@1+ (1,0) [0|0] "" Vector__XXX
 SG_ OCS1P_sbrBoundaryType : 43|1@1+ (1,0) [0|0] "" Vector__XXX
 SG_ OCS1P_sandwichBoundaryType : 42|1@1+ (1,0) [0|0] "" Vector__XXX
 SG_ OCS1P_noSandwichType : 40|2@1+ (1,0) [0|0] "" Vector__XXX
 SG_ OCS1P_sandwichDisabled : 39|1@1+ (1,0) [0|0] "" Vector__XXX
 SG_ OCS1P_classificationVariant : 36|3@1+ (1,0) [0|0] "" Vector__XXX
 SG_ OCS1P_classificationHoldState : 33|3@1+ (1,0) [0|0] "" Vector__XXX
 SG_ OCS1P_classificationExtHold : 32|1@1+ (1,0) [0|0] "" Vector__XXX
 SG_ OCS1P_cushionStable : 31|1@1+ (1,0) [0|0] "" Vector__XXX
 SG_ OCS1P_classificationHeld : 30|1@1+ (1,0) [0|0] "" Vector__XXX
 SG_ OCS1P_occupantClassificationCap : 25|3@1+ (1,0) [0|0] "" Vector__XXX
 SG_ OCS1P_occupantClassificationRawCap : 22|3@1+ (1,0) [0|0] "" Vector__XXX
 SG_ OCS1P_occupantClassificationSelf : 19|3@1+ (1,0) [0|0] "" Vector__XXX
 SG_ OCS1P_occupantClassificationRaw : 16|3@1+ (1,0) [0|0] "" Vector__XXX
 SG_ OCS1P_triggerSnapshot : 11|5@1+ (1,0) [0|0] "" Vector__XXX
 SG_ OCS1P_occupiedState : 9|2@1+ (1,0) [0|0] "" Vector__XXX
 SG_ OCS1P_occupantClassificationQF : 8|1@1+ (1,0) [0|0] "" Vector__XXX
 SG_ OCS1P_occupantClassification : 0|8@1+ (1,0) [0|0] "" Vector__XXX

BO_ 777 DAS_object: 8 CH
 SG_ DAS_leadVeh2Id m0 : 58|6@1+ (1,0) [0|0] ""  X
 SG_ DAS_leftVeh2Id m1 : 58|6@1+ (1,0) [0|0] ""  X
 SG_ DAS_rightVeh2Id m2 : 58|6@1+ (1,0) [0|0] ""  X
 SG_ DAS_cutinVehHeading m5 : 56|8@1+ (0.0245437,-3.14159) [0|0] "rad"  X
 SG_ DAS_leadVeh2Dy m0 : 51|7@1+ (0.35,-22.05) [0|0] "m"  X
 SG_ DAS_leftVeh2Dy m1 : 51|7@1+ (0.35,-22.05) [0|0] "m"  X
 SG_ DAS_rightVeh2Dy m2 : 51|7@1+ (0.35,-22.05) [0|0] "m"  X
 SG_ DAS_rightVeh2Heading m5 : 48|8@1+ (0.0245437,-3.14159) [0|0] "rad"  X
 SG_ DAS_leadVeh2VxRel m0 : 47|4@1+ (4,-30) [0|0] "m/s"  X
 SG_ DAS_leftVeh2VxRel m1 : 47|4@1+ (4,-30) [0|0] "m/s"  X
 SG_ DAS_rightVeh2VxRel m2 : 47|4@1+ (4,-30) [0|0] "m/s"  X
 SG_ DAS_rightVehHeading m5 : 40|8@1+ (0.0245437,-3.14159) [0|0] "rad"  X
 SG_ DAS_leadVeh2Dx m0 : 39|8@1+ (0.5,0) [0|0] "m"  X
 SG_ DAS_leftVeh2Dx m1 : 39|8@1+ (0.5,0) [0|0] "m"  X
 SG_ DAS_rightVeh2Dx m2 : 39|8@1+ (0.5,0) [0|0] "m"  X
 SG_ DAS_leadVeh2RelevantForControl m0 : 38|1@1+ (1,0) [0|0] ""  X
 SG_ DAS_leftVeh2RelevantForControl m1 : 38|1@1+ (1,0) [0|0] ""  X
 SG_ DAS_rightVeh2RelevantForControl m2 : 38|1@1+ (1,0) [0|0] ""  X
 SG_ DAS_leadVeh2Type m0 : 34|3@1+ (1,0) [0|0] ""  X
 SG_ DAS_leftVeh2Type m1 : 34|3@1+ (1,0) [0|0] ""  X
 SG_ DAS_rightVeh2Type m2 : 34|3@1+ (1,0) [0|0] ""  X
 SG_ DAS_leftVeh2Heading m5 : 32|8@1+ (0.0245437,-3.14159) [0|0] "rad"  X
 SG_ DAS_roadSignOrientation m4 : 30|2@1+ (1,0) [0|0] ""  X
 SG_ DAS_leadVehId m0 : 27|7@1+ (1,0) [0|0] ""  X
 SG_ DAS_leftVehId m1 : 27|7@1+ (1,0) [0|0] ""  X
 SG_ DAS_rightVehId m2 : 27|7@1+ (1,0) [0|0] ""  X
 SG_ DAS_cutinVehId m3 : 27|7@1+ (1,0) [0|0] ""  X
 SG_ DAS_roadSignArrow m4 : 27|3@1+ (1,0) [0|0] ""  X
 SG_ DAS_roadSignSource m4 : 25|2@1+ (1,0) [0|0] ""  X
 SG_ DAS_roadSignControlActive m4 : 24|1@1+ (1,0) [0|0] ""  X
 SG_ DAS_leftVehHeading m5 : 24|8@1+ (0.0245437,-3.14159) [0|0] "rad"  X
 SG_ DAS_leadVehDy m0 : 20|7@1+ (0.35,-22.05) [0|0] "m"  X
 SG_ DAS_leftVehDy m1 : 20|7@1+ (0.35,-22.05) [0|0] "m"  X
 SG_ DAS_rightVehDy m2 : 20|7@1+ (0.35,-22.05) [0|0] "m"  X
 SG_ DAS_cutinVehDy m3 : 20|7@1+ (0.35,-22.05) [0|0] "m"  X
 SG_ DAS_leadVehVxRel m0 : 16|4@1+ (4,-30) [0|0] "m/s"  X
 SG_ DAS_leftVehVxRel m1 : 16|4@1+ (4,-30) [0|0] "m/s"  X
 SG_ DAS_rightVehVxRel m2 : 16|4@1+ (4,-30) [0|0] "m/s"  X
 SG_ DAS_cutinVehVxRel m3 : 16|4@1+ (4,-30) [0|0] "m/s"  X
 SG_ DAS_leadVeh2Heading m5 : 16|8@1+ (0.0245437,-3.14159) [0|0] "rad"  X
 SG_ DAS_roadSignStopLineDist m4 : 14|10@1+ (0.2,-20) [0|0] "m"  X
 SG_ DAS_leadVehDx m0 : 8|8@1+ (0.5,0) [0|0] "m"  X
 SG_ DAS_leftVehDx m1 : 8|8@1+ (0.5,0) [0|0] "m"  X
 SG_ DAS_rightVehDx m2 : 8|8@1+ (0.5,0) [0|0] "m"  X
 SG_ DAS_cutinVehDx m3 : 8|8@1+ (0.5,0) [0|0] "m"  X
 SG_ DAS_leadVehHeading m5 : 8|8@1+ (0.0245437,-3.14159) [0|0] "rad"  X
 SG_ DAS_leadVehRelevantForControl m0 : 7|1@1+ (1,0) [0|0] ""  X
 SG_ DAS_leftVehRelevantForControl m1 : 7|1@1+ (1,0) [0|0] ""  X
 SG_ DAS_rightVehRelevantForControl m2 : 7|1@1+ (1,0) [0|0] ""  X
 SG_ DAS_cutinVehRelevantForControl m3 : 7|1@1+ (1,0) [0|0] ""  X
 SG_ DAS_roadSignId m4 : 6|8@1+ (1,0) [0|0] ""  X
 SG_ DAS_leadVehType m0 : 3|3@1+ (1,0) [0|0] ""  X
 SG_ DAS_leftVehType m1 : 3|3@1+ (1,0) [0|0] ""  X
 SG_ DAS_rightVehType m2 : 3|3@1+ (1,0) [0|0] ""  X
 SG_ DAS_cutinVehType m3 : 3|3@1+ (1,0) [0|0] ""  X
 SG_ DAS_roadSignColor m4 : 3|3@1+ (1,0) [0|0] ""  X
 SG_ DAS_objectId M : 0|3@1+ (1,0) [0|0] ""  X

BO_ 784 HVP_info: 8 Vector__XXX
 SG_ HVP_componentId m10 : 48|16@1+ (1,0) [0|0] "" Vector__XXX
 SG_ HVP_subUsageId m11 : 48|16@1+ (1,0) [0|0] "" Vector__XXX
 SG_ HVP_appCrc m13 : 32|32@1+ (1,0) [0|0] "" Vector__XXX
 SG_ HVP_bootCrc m20 : 32|32@1+ (1,0) [0|0] "" Vector__XXX
 SG_ HVP_hardwareId m10 : 32|16@1+ (1,0) [0|0] "" Vector__XXX
 SG_ HVP_usageId m11 : 32|16@1+ (1,0) [0|0] "" Vector__XXX
 SG_ HVP_assemblyId m11 : 24|8@1+ (1,0) [0|0] "" Vector__XXX
 SG_ HVP_buildConfigId m10 : 16|16@1+ (1,0) [0|0] "" Vector__XXX
 SG_ HVP_pcbaId m11 : 16|8@1+ (1,0) [0|0] "" Vector__XXX
 SG_ HVP_appGitHash m17 : 8|56@1+ (1,0) [0|0] "" Vector__XXX
 SG_ HVP_bootGitHash m18 : 8|56@1+ (1,0) [0|0] "" Vector__XXX
 SG_ HVP_bootUdsProtoVersion m20 : 8|8@1+ (1,0) [0|0] "" Vector__XXX
 SG_ HVP_buildType m10 : 8|3@1+ (1,0) [0|0] "" Vector__XXX
 SG_ HVP_platformType m13 : 8|8@1+ (1,0) [0|0] "" Vector__XXX
 SG_ HVP_infoIndex M : 0|8@1+ (1,0) [0|0] "" Vector__XXX

BO_ 785 BMS_autonomyHealth: 2 Vector__XXX
 SG_ BMS_hvWpChargeHealth : 13|1@1+ (1,0) [0|0] "" Vector__XXX
 SG_ BMS_hvAcChargeHealth : 12|1@1+ (1,0) [0|0] "" Vector__XXX
 SG_ BMS_hvDcChargeHealth : 11|1@1+ (1,0) [0|0] "" Vector__XXX
 SG_ BMS_hvDriveHealth : 10|1@1+ (1,0) [0|0] "" Vector__XXX
 SG_ BMS_timeToNoHv : 0|10@1+ (1,0) [0|0] "" Vector__XXX

BO_ 786 BMS_thermalStatus: 8 Vector__XXX
 SG_ BMS_flowRequest m0 : 56|8@1+ (0.25,0) [0|0] "" Vector__XXX
 SG_ BMS_powerDissipation m1 : 50|10@1+ (0.02,0) [0|0] "" Vector__XXX
 SG_ BMS_maxPackTemperature m0 : 43|11@1+ (0.1,-40) [0|0] "" Vector__XXX
 SG_ BMS_noFlowRequest m0 : 42|1@1+ (1,0) [0|0] "" Vector__XXX
 SG_ BMS_activeHeatCellTargetT m1 : 41|9@1+ (0.25,-25) [0|0] "" Vector__XXX
 SG_ BMS_activeCoolCellReferenceT m1 : 32|9@1+ (0.25,-25) [0|0] "" Vector__XXX
 SG_ BMS_minPackTemperature m0 : 32|10@1+ (0.2,-40) [0|0] "" Vector__XXX
 SG_ BMS_pcsNoFlowRequest m0 : 31|1@1+ (1,0) [0|0] "" Vector__XXX
 SG_ BMS_activeHeatingWorthwhile m0 : 30|1@1+ (1,0) [0|0] "" Vector__XXX
 SG_ BMS_i2tDeratingEnabled m1 : 29|1@1+ (1,0) [0|0] "" Vector__XXX
 SG_ BMS_requestDischarge m0 : 29|1@1+ (1,0) [0|0] "" Vector__XXX
 SG_ BMS_hotCellTempLimit m1 : 20|9@1+ (0.25,-25) [0|0] "" Vector__XXX
 SG_ BMS_inletActiveHeatTargetT m0 : 20|9@1+ (0.25,-25) [0|0] "" Vector__XXX
 SG_ BMS_hotStagnationLimit m1 : 11|9@1+ (0.25,-25) [0|0] "" Vector__XXX
 SG_ BMS_inletPassiveTargetT m0 : 11|9@1+ (0.25,-25) [0|0] "" Vector__XXX
 SG_ BMS_coldStagnationLimit m1 : 2|9@1+ (0.25,-25) [0|0] "" Vector__XXX
 SG_ BMS_inletActiveCoolTargetT m0 : 2|9@1+ (0.25,-25) [0|0] "" Vector__XXX
 SG_ BMS_thermalStatusMultiplexer M : 0|2@1+ (1,0) [0|0] "" Vector__XXX

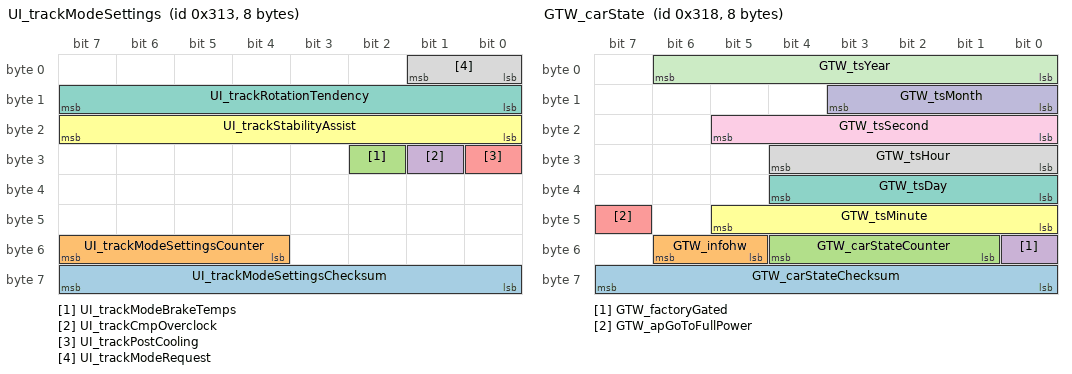
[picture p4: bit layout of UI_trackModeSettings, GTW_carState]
BO_ 787 UI_trackModeSettings: 8 Vector__XXX
 SG_ UI_trackModeSettingsChecksum : 56|8@1+ (1,0) [0|0] "" Vector__XXX
 SG_ UI_trackModeSettingsCounter : 52|4@1+ (1,0) [0|0] "" Vector__XXX
 SG_ UI_trackModeBrakeTemps : 26|1@1+ (1,0) [0|0] "" Vector__XXX
 SG_ UI_trackCmpOverclock : 25|1@1+ (1,0) [0|0] "" Vector__XXX
 SG_ UI_trackPostCooling : 24|1@1+ (1,0) [0|0] "" Vector__XXX
 SG_ UI_trackStabilityAssist : 16|8@1+ (0.5,0) [0|0] "" Vector__XXX
 SG_ UI_trackRotationTendency : 8|8@1+ (0.5,0) [0|0] "" Vector__XXX
 SG_ UI_trackModeRequest : 0|2@1+ (1,0) [0|0] "" Vector__XXX

BO_ 789 DIR_temperature: 8 Vector__XXX
 SG_ DIR_TPak2Temp m1 : 56|8@1+ (1,-40) [0|0] "" Vector__XXX
 SG_ DIR_statorHousingTemp m4 : 56|8@1+ (1,-40) [0|0] "" Vector__XXX
 SG_ DIR_statorTpct m0 : 56|8@1+ (0.4,0) [0|0] "" Vector__XXX
 SG_ DIR_inverterHS1Est m3 : 52|8@1+ (1,-40) [0|0] "" Vector__XXX
 SG_ DIR_TPak1Temp m1 : 48|8@1+ (1,-40) [0|0] "" Vector__XXX
 SG_ DIR_inverterInletEst m4 : 48|8@1+ (1,-40) [0|0] "" Vector__XXX
 SG_ DIR_inverterTpct m0 : 48|8@1+ (0.4,0) [0|0] "" Vector__XXX
 SG_ DIR_inverterSensorEst m3 : 44|8@1+ (1,-40) [0|0] "" Vector__XXX
 SG_ DIR_heatsinkT m0 : 40|8@1+ (1,-40) [0|0] "" Vector__XXX
 SG_ DIR_inverterHS2Est m4 : 40|8@1+ (1,-40) [0|0] "" Vector__XXX
 SG_ DIR_junctionTemp m1 : 40|8@1+ (1,-40) [0|0] "" Vector__XXX
 SG_ DIR_burnInDamageRatio m3 : 35|9@1+ (0.01,0) [0|0] "" Vector__XXX
 SG_ DIR_additionalFetBurnIn m2 : 32|16@1+ (0.00763,0) [0|0] "" Vector__XXX
 SG_ DIR_dcCapT m0 : 32|8@1+ (1,-40) [0|0] "" Vector__XXX
 SG_ DIR_pcbTemp2 m1 : 32|8@1+ (1,-40) [0|0] "" Vector__XXX
 SG_ DIR_heatsink3Temp m1 : 24|8@1+ (1,-40) [0|0] "" Vector__XXX
 SG_ DIR_statorT m0 : 24|8@1+ (1,-40) [0|0] "" Vector__XXX
 SG_ DIR_endOfServiceWeibullMiles m3 : 19|16@1+ (8,0) [0|0] "" Vector__XXX
 SG_ DIR_heatsink2Temp m1 : 16|8@1+ (1,-40) [0|0] "" Vector__XXX
 SG_ DIR_inverterT m0 : 16|8@1+ (1,-40) [0|0] "" Vector__XXX
 SG_ DIR_normalFetBurnIn m2 : 16|16@1+ (0.00763,0) [0|0] "" Vector__XXX
 SG_ DIR_fluidInTemp m2 : 8|8@1+ (1,-40) [0|0] "" Vector__XXX
 SG_ DIR_heatsink1Temp m1 : 8|8@1+ (1,-40) [0|0] "" Vector__XXX
 SG_ DIR_initialBurnInVehicleOdometer m4 : 8|32@1+ (0.001,0) [0|0] "" Vector__XXX
 SG_ DIR_pcbT m0 : 8|8@1+ (1,-40) [0|0] "" Vector__XXX
 SG_ DIR_currentWeibullMiles m3 : 3|16@1+ (8,0) [0|0] "" Vector__XXX
 SG_ DIR_inverterTQF m0 : 3|2@1+ (1,0) [0|0] "" Vector__XXX
 SG_ DIR_tempIndex M : 0|3@1+ (1,0) [0|0] "" Vector__XXX

BO_ 792 GTW_carState: 8 Vector__XXX
 SG_ GTW_carStateChecksum : 56|8@1+ (1,0) [0|0] "" Vector__XXX
 SG_ GTW_infohw : 53|2@1+ (1,0) [0|0] "" Vector__XXX
 SG_ GTW_carStateCounter : 49|4@1+ (1,0) [0|0] "" Vector__XXX
 SG_ GTW_factoryGated : 48|1@1+ (1,0) [0|0] "" Vector__XXX
 SG_ GTW_apGoToFullPower : 47|1@1+ (1,0) [0|0] "" Vector__XXX
 SG_ GTW_tsMinute : 40|6@1+ (1,0) [0|0] "" Vector__XXX
 SG_ GTW_tsDay : 32|5@1+ (1,0) [0|0] "" Vector__XXX
 SG_ GTW_tsHour : 24|5@1+ (1,0) [0|0] "" Vector__XXX
 SG_ GTW_tsSecond : 16|6@1+ (1,0) [0|0] "" Vector__XXX
 SG_ GTW_tsMonth : 8|4@1+ (1,0) [0|0] "" Vector__XXX
 SG_ GTW_tsYear : 0|7@1+ (1,2000) [0|0] "" Vector__XXX

BO_ 793 VCSEC_info: 8 Vector__XXX
 SG_ VCSEC_infoComponentId m10 : 48|16@1+ (1,0) [0|0] "" Vector__XXX
 SG_ VCSEC_infoSubUsageId m11 : 48|16@1+ (1,0) [0|0] "" Vector__XXX
 SG_ VCSEC_infoAppCrc m13 : 32|32@1+ (1,0) [0|0] "" Vector__XXX
 SG_ VCSEC_infoHardwareId m10 : 32|16@1+ (1,0) [0|0] "" Vector__XXX
 SG_ VCSEC_infoSubcomponent1 m16 : 32|32@1+ (1,0) [0|0] "" Vector__XXX
 SG_ VCSEC_infoSubcomponent10 m37 : 32|32@1+ (1,0) [0|0] "" Vector__XXX
 SG_ VCSEC_infoSubcomponent11 m38 : 32|32@1+ (1,0) [0|0] "" Vector__XXX
 SG_ VCSEC_infoSubcomponent12 m39 : 32|32@1+ (1,0) [0|0] "" Vector__XXX
 SG_ VCSEC_infoSubcomponent13 m40 : 32|32@1+ (1,0) [0|0] "" Vector__XXX
 SG_ VCSEC_infoSubcomponent14 m41 : 32|32@1+ (1,0) [0|0] "" Vector__XXX
 SG_ VCSEC_infoSubcomponent2 m23 : 32|32@1+ (1,0) [0|0] "" Vector__XXX
 SG_ VCSEC_infoSubcomponent3 m24 : 32|32@1+ (1,0) [0|0] "" Vector__XXX
 SG_ VCSEC_infoSubcomponent4 m31 : 32|32@1+ (1,0) [0|0] "" Vector__XXX
 SG_ VCSEC_infoSubcomponent5 m32 : 32|32@1+ (1,0) [0|0] "" Vector__XXX
 SG_ VCSEC_infoSubcomponent6 m33 : 32|32@1+ (1,0) [0|0] "" Vector__XXX
 SG_ VCSEC_infoSubcomponent7 m34 : 32|32@1+ (1,0) [0|0] "" Vector__XXX
 SG_ VCSEC_infoSubcomponent8 m35 : 32|32@1+ (1,0) [0|0] "" Vector__XXX
 SG_ VCSEC_infoSubcomponent9 m36 : 32|32@1+ (1,0) [0|0] "" Vector__XXX
 SG_ VCSEC_infoUsageId m11 : 32|16@1+ (1,0) [0|0] "" Vector__XXX
 SG_ VCSEC_infoBootCrc m20 : 24|32@1+ (1,0) [0|0] "" Vector__XXX
 SG_ VCSEC_infoAssemblyId m11 : 16|8@1+ (1,0) [0|0] "" Vector__XXX
 SG_ VCSEC_infoBuildConfigId m10 : 16|16@1+ (1,0) [0|0] "" Vector__XXX
 SG_ VCSEC_infoAppGitHash m17 : 8|56@1+ (1,0) [0|0] "" Vector__XXX
 SG_ VCSEC_infoBootGitHash m18 : 8|56@1+ (1,0) [0|0] "" Vector__XXX
 SG_ VCSEC_infoBootUdsProtoVersion m20 : 8|16@1+ (1,0) [0|0] "" Vector__XXX
 SG_ VCSEC_infoBuildType m10 : 8|3@1+ (1,0) [0|0] "" Vector__XXX
 SG_ VCSEC_infoPcbaId m11 : 8|8@1+ (1,0) [0|0] "" Vector__XXX
 SG_ VCSEC_infoPlatformType m19 : 8|8@1+ (1,0) [0|0] "" Vector__XXX
 SG_ VCSEC_infoIndex M : 0|8@1+ (1,0) [0|0] "" Vector__XXX

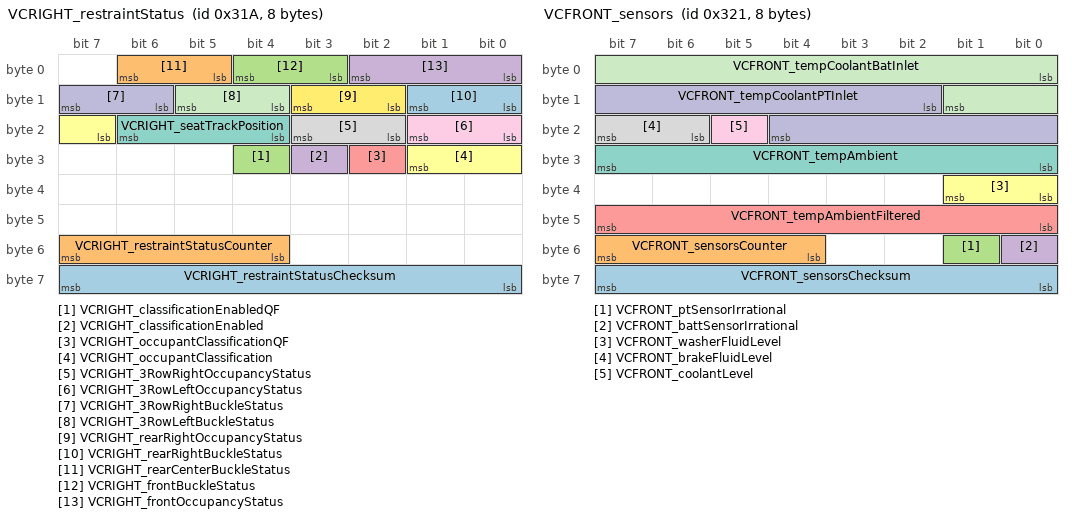
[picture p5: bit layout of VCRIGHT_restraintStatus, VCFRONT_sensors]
BO_ 794 VCRIGHT_restraintStatus: 8 Vector__XXX
 SG_ VCRIGHT_restraintStatusChecksum : 56|8@1+ (1,0) [0|0] "" Vector__XXX
 SG_ VCRIGHT_restraintStatusCounter : 52|4@1+ (1,0) [0|0] "" Vector__XXX
 SG_ VCRIGHT_classificationEnabledQF : 28|1@1+ (1,0) [0|0] "" Vector__XXX
 SG_ VCRIGHT_classificationEnabled : 27|1@1+ (1,0) [0|0] "" Vector__XXX
 SG_ VCRIGHT_occupantClassificationQF : 26|1@1+ (1,0) [0|0] "" Vector__XXX
 SG_ VCRIGHT_occupantClassification : 23|3@1+ (1,0) [0|0] "" Vector__XXX
 SG_ VCRIGHT_seatTrackPosition : 20|3@1+ (1,0) [0|0] "" Vector__XXX
 SG_ VCRIGHT_3RowRightOccupancyStatus : 18|2@1+ (1,0) [0|0] "" Vector__XXX
 SG_ VCRIGHT_3RowLeftOccupancyStatus : 16|2@1+ (1,0) [0|0] "" Vector__XXX
 SG_ VCRIGHT_3RowRightBuckleStatus : 14|2@1+ (1,0) [0|0] "" Vector__XXX
 SG_ VCRIGHT_3RowLeftBuckleStatus : 12|2@1+ (1,0) [0|0] "" Vector__XXX
 SG_ VCRIGHT_rearRightOccupancyStatus : 10|2@1+ (1,0) [0|0] "" Vector__XXX
 SG_ VCRIGHT_rearRightBuckleStatus : 8|2@1+ (1,0) [0|0] "" Vector__XXX
 SG_ VCRIGHT_rearCenterBuckleStatus : 5|2@1+ (1,0) [0|0] "" Vector__XXX
 SG_ VCRIGHT_frontBuckleStatus : 3|2@1+ (1,0) [0|0] "" Vector__XXX
 SG_ VCRIGHT_frontOccupancyStatus : 0|3@1+ (1,0) [0|0] "" Vector__XXX

BO_ 801 VCFRONT_sensors: 8 Vector__XXX
 SG_ VCFRONT_sensorsChecksum : 56|8@1+ (1,0) [0|0] "" Vector__XXX
 SG_ VCFRONT_sensorsCounter : 52|4@1+ (1,0) [0|0] "" Vector__XXX
 SG_ VCFRONT_ptSensorIrrational : 49|1@1+ (1,0) [0|0] "" Vector__XXX
 SG_ VCFRONT_battSensorIrrational : 48|1@1+ (1,0) [0|0] "" Vector__XXX
 SG_ VCFRONT_tempAmbientFiltered : 40|8@1+ (0.5,-40) [0|0] "" Vector__XXX
 SG_ VCFRONT_washerFluidLevel : 32|2@1+ (1,0) [0|0] "" Vector__XXX
 SG_ VCFRONT_tempAmbient : 24|8@1+ (0.5,-40) [0|0] "" Vector__XXX
 SG_ VCFRONT_brakeFluidLevel : 22|2@1+ (1,0) [0|0] "" Vector__XXX
 SG_ VCFRONT_coolantLevel : 21|1@1+ (1,0) [0|0] "" Vector__XXX
 SG_ VCFRONT_tempCoolantPTInlet : 10|11@1+ (0.125,-40) [0|0] "" Vector__XXX
 SG_ VCFRONT_tempCoolantBatInlet : 0|10@1+ (0.125,-40) [0|0] "" Vector__XXX

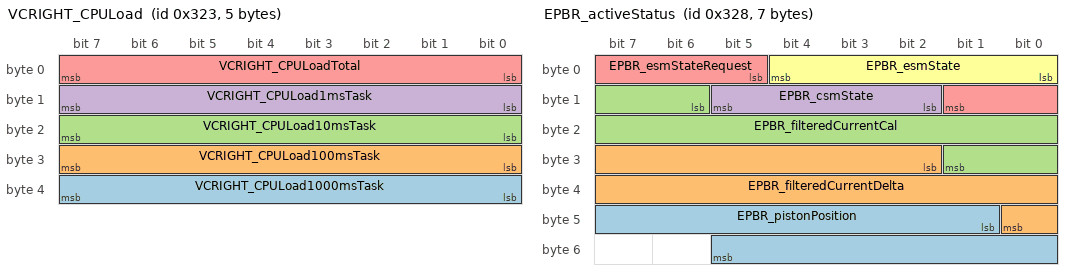
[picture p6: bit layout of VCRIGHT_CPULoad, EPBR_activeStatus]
BO_ 803 VCRIGHT_CPULoad: 5 Vector__XXX
 SG_ VCRIGHT_CPULoad1000msTask : 32|8@1+ (1,0) [0|0] "" Vector__XXX
 SG_ VCRIGHT_CPULoad100msTask : 24|8@1+ (1,0) [0|0] "" Vector__XXX
 SG_ VCRIGHT_CPULoad10msTask : 16|8@1+ (1,0) [0|0] "" Vector__XXX
 SG_ VCRIGHT_CPULoad1msTask : 8|8@1+ (1,0) [0|0] "" Vector__XXX
 SG_ VCRIGHT_CPULoadTotal : 0|8@1+ (1,0) [0|0] "" Vector__XXX

BO_ 804 UI_gpsTime: 8 Vector__XXX
 SG_ UI_gpsTime : 0|64@1+ (1,0) [0|0] "" Vector__XXX

BO_ 808 EPBR_activeStatus: 7 Vector__XXX
 SG_ EPBR_pistonPosition : 41|13@1- (9.768009768009769,0) [0|0] "" Vector__XXX
 SG_ EPBR_filteredCurrentDelta : 26|15@1- (0.01,0) [0|0] "" Vector__XXX
 SG_ EPBR_filteredCurrentCal : 14|12@1+ (0.01,0) [0|0] "" Vector__XXX
 SG_ EPBR_csmState : 10|4@1+ (1,0) [0|0] "" Vector__XXX
 SG_ EPBR_esmStateRequest : 5|5@1+ (1,0) [0|0] "" Vector__XXX
 SG_ EPBR_esmState : 0|5@1+ (1,0) [0|0] "" Vector__XXX

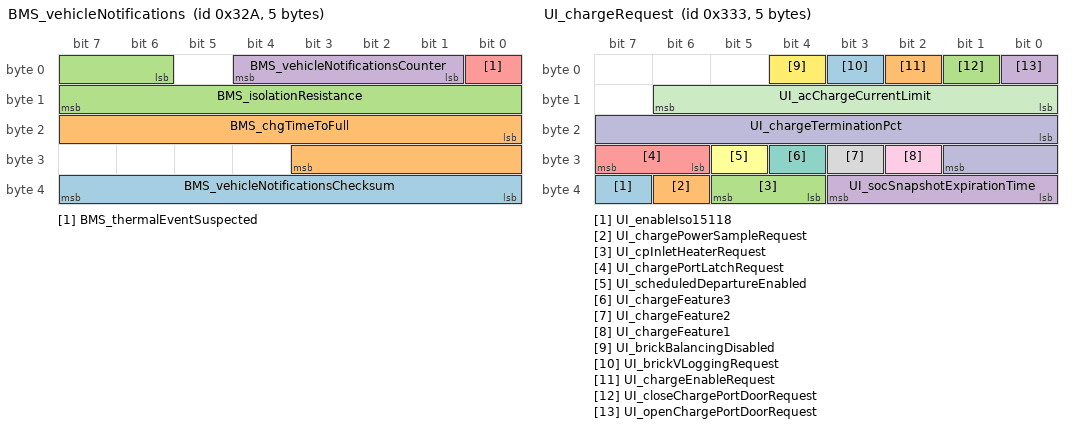
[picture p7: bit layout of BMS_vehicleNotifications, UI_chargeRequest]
BO_ 810 BMS_vehicleNotifications: 5 Vector__XXX
 SG_ BMS_vehicleNotificationsChecksum : 32|8@1+ (1,0) [0|0] "" Vector__XXX
 SG_ BMS_chgTimeToFull : 16|12@1+ (0.01666667,0) [0|0] "" Vector__XXX
 SG_ BMS_isolationResistance : 6|10@1+ (10,0) [0|0] "" Vector__XXX
 SG_ BMS_vehicleNotificationsCounter : 1|4@1+ (1,0) [0|0] "" Vector__XXX
 SG_ BMS_thermalEventSuspected : 0|1@1+ (1,0) [0|0] "" Vector__XXX

BO_ 816 SCCM_info: 8 Vector__XXX
 SG_ SCCM_infoComponentId m10 : 48|16@1+ (1,0) [0|0] "" Vector__XXX
 SG_ SCCM_infoSubUsageId m11 : 48|16@1+ (1,0) [0|0] "" Vector__XXX
 SG_ SCCM_infoBootCrc m20 : 32|32@1+ (1,0) [0|0] "" Vector__XXX
 SG_ SCCM_infoBootSvnUrlHash m14 : 32|32@1+ (1,0) [0|0] "" Vector__XXX
 SG_ SCCM_infoHardwareId m10 : 32|16@1+ (1,0) [0|0] "" Vector__XXX
 SG_ SCCM_infoUsageId m11 : 32|16@1+ (1,0) [0|0] "" Vector__XXX
 SG_ SCCM_infoAppCrc m13 : 39|32@0+ (1,0) [0|0] "" Vector__XXX
 SG_ SCCM_infoAssemblyId m11 : 24|8@1+ (1,0) [0|0] "" Vector__XXX
 SG_ SCCM_infoBuildConfigId m10 : 16|16@1+ (1,0) [0|0] "" Vector__XXX
 SG_ SCCM_infoPcbaId m11 : 16|8@1+ (1,0) [0|0] "" Vector__XXX
 SG_ SCCM_infoSubcomponent1Version m16 : 16|32@1+ (1,0) [0|0] "" Vector__XXX
 SG_ SCCM_infoAppSvnHash m17 : 8|56@1+ (1,0) [0|0] "" Vector__XXX
 SG_ SCCM_infoBootSvnHash m18 : 8|56@1+ (1,0) [0|0] "" Vector__XXX
 SG_ SCCM_infoBootSvnRev m14 : 8|24@1+ (1,0) [0|0] "" Vector__XXX
 SG_ SCCM_infoBuildType m10 : 8|8@1+ (1,0) [0|0] "" Vector__XXX
 SG_ SCCM_infoPlatformType m13 : 8|8@1+ (1,0) [0|0] "" Vector__XXX
 SG_ SCCM_infoUdsProtoVersion m20 : 8|8@1+ (1,0) [0|0] "" Vector__XXX
 SG_ SCCM_infoIndex M : 0|8@1+ (1,0) [0|0] "" Vector__XXX

BO_ 818 BMS_bmbMinMax: 6 Vector__XXX
 SG_ BMS_brickNumVoltageMin m1 : 40|7@1+ (1,1) [0|0] "" Vector__XXX
 SG_ BMS_brickNumVoltageMax m1 : 32|7@1+ (1,1) [0|0] "" Vector__XXX
 SG_ BMS_thermistorTAvg m0 : 32|8@1+ (0.5,-40) [0|0] "" Vector__XXX
 SG_ BMS_thermistorTMin m0 : 24|8@1+ (0.5,-40) [0|0] "" Vector__XXX
 SG_ BMS_brickVoltageMin m1 : 16|12@1+ (0.002,0) [0|0] "" Vector__XXX
 SG_ BMS_thermistorTMax m0 : 16|8@1+ (0.5,-40) [0|0] "" Vector__XXX
 SG_ BMS_thermistorNumTMax m0 : 8|4@1+ (1,0) [0|0] "" Vector__XXX
 SG_ BMS_brickVoltageMax m1 : 2|12@1+ (0.002,0) [0|0] "" Vector__XXX
 SG_ BMS_thermistorNumTMin m0 : 2|4@1+ (1,0) [0|0] "" Vector__XXX
 SG_ BMS_bmbMinMaxMultiplexer M : 0|2@1+ (1,0) [0|0] "" Vector__XXX

BO_ 819 UI_chargeRequest: 5 Vector__XXX
 SG_ UI_enableIso15118 : 39|1@1+ (1,0) [0|0] "" Vector__XXX
 SG_ UI_chargePowerSampleRequest : 38|1@1+ (1,0) [0|0] "" Vector__XXX
 SG_ UI_cpInletHeaterRequest : 36|2@1+ (1,0) [0|0] "" Vector__XXX
 SG_ UI_socSnapshotExpirationTime : 32|4@1+ (2,2) [0|0] "" Vector__XXX
 SG_ UI_chargePortLatchRequest : 30|2@1+ (1,0) [0|0] "" Vector__XXX
 SG_ UI_scheduledDepartureEnabled : 29|1@1+ (1,0) [0|0] "" Vector__XXX
 SG_ UI_chargeFeature3 : 28|1@1+ (1,0) [0|0] "" Vector__XXX
 SG_ UI_chargeFeature2 : 27|1@1+ (1,0) [0|0] "" Vector__XXX
 SG_ UI_chargeFeature1 : 26|1@1+ (1,0) [0|0] "" Vector__XXX
 SG_ UI_chargeTerminationPct : 16|10@1+ (0.1,0) [0|0] "" Vector__XXX
 SG_ UI_acChargeCurrentLimit : 8|7@1+ (1,0) [0|0] "" Vector__XXX
 SG_ UI_brickBalancingDisabled : 4|1@1+ (1,0) [0|0] "" Vector__XXX
 SG_ UI_brickVLoggingRequest : 3|1@1+ (1,0) [0|0] "" Vector__XXX
 SG_ UI_chargeEnableRequest : 2|1@1+ (1,0) [0|0] "" Vector__XXX
 SG_ UI_closeChargePortDoorRequest : 1|1@1+ (1,0) [0|0] "" Vector__XXX
 SG_ UI_openChargePortDoorRequest : 0|1@1+ (1,0) [0|0] "" Vector__XXX

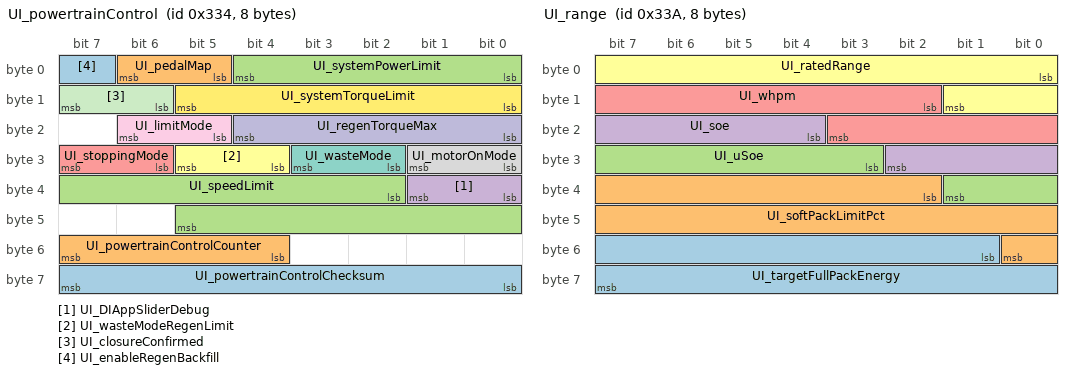
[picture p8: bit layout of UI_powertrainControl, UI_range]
BO_ 820 UI_powertrainControl: 8 Vector__XXX
 SG_ UI_powertrainControlChecksum : 56|8@1+ (1,0) [0|0] "" Vector__XXX
 SG_ UI_powertrainControlCounter : 52|4@1+ (1,0) [0|0] "" Vector__XXX
 SG_ UI_speedLimit : 34|12@1+ (0.1,0) [0|0] "" Vector__XXX
 SG_ UI_DIAppSliderDebug : 32|2@1+ (1,0) [0|0] "" Vector__XXX
 SG_ UI_stoppingMode : 30|2@1+ (1,0) [0|0] "" Vector__XXX
 SG_ UI_wasteModeRegenLimit : 28|2@1+ (1,0) [0|0] "" Vector__XXX
 SG_ UI_wasteMode : 26|2@1+ (1,0) [0|0] "" Vector__XXX
 SG_ UI_motorOnMode : 24|2@1+ (1,0) [0|0] "" Vector__XXX
 SG_ UI_limitMode : 21|2@1+ (1,0) [0|0] "" Vector__XXX
 SG_ UI_regenTorqueMax : 16|5@1+ (5,0) [0|0] "" Vector__XXX
 SG_ UI_closureConfirmed : 14|2@1+ (1,0) [0|0] "" Vector__XXX
 SG_ UI_systemTorqueLimit : 8|6@1+ (150,1000) [0|0] "" Vector__XXX
 SG_ UI_enableRegenBackfill : 7|1@1+ (1,0) [0|0] "" Vector__XXX
 SG_ UI_pedalMap : 5|2@1+ (1,0) [0|0] "" Vector__XXX
 SG_ UI_systemPowerLimit : 0|5@1+ (20,20) [0|0] "" Vector__XXX

BO_ 821 DIR_info: 8 Vector__XXX
 SG_ DIR_FPGA_version m16 : 48|8@1+ (1,0) [0|0] "" Vector__XXX
 SG_ DIR_componentId m10 : 48|16@1+ (1,0) [0|0] "" Vector__XXX
 SG_ DIR_subUsageId m11 : 48|16@1+ (1,0) [0|0] "" Vector__XXX
 SG_ DIR_applicationCrc m13 : 32|32@1+ (1,0) [0|0] "" Vector__XXX
 SG_ DIR_bootloaderCrc m20 : 32|32@1+ (1,0) [0|0] "" Vector__XXX
 SG_ DIR_hardwareId m10 : 32|8@1+ (1,0) [0|0] "" Vector__XXX
 SG_ DIR_usageId m11 : 32|16@1+ (1,0) [0|0] "" Vector__XXX
 SG_ DIR_assemblyId m11 : 24|8@1+ (1,0) [0|0] "" Vector__XXX
 SG_ DIR_mechSafeStateType m12 : 24|2@1+ (1,0) [0|0] "" Vector__XXX
 SG_ DIR_oilPumpUsageId m33 : 24|16@1+ (1,0) [0|0] "" Vector__XXX
 SG_ DIR_refRotorOffset m35 : 24|12@1- (0.1,0) [0|0] "" Vector__XXX
 SG_ DIR_torqueWearTotal m36 : 24|8@1+ (0.02,0) [0|0] "" Vector__XXX
 SG_ DIR_buildConfigurationId m10 : 16|16@1+ (1,0) [0|0] "" Vector__XXX
 SG_ DIR_oilPumpAppCrc m16 : 16|32@1+ (1,0) [0|0] "" Vector__XXX
 SG_ DIR_oilPumpAssemblyId m33 : 16|8@1+ (1,0) [0|0] "" Vector__XXX
 SG_ DIR_pcbaId m11 : 16|8@1+ (1,0) [0|0] "" Vector__XXX
 SG_ DIR_siliconType m12 : 16|1@1+ (1,0) [0|0] "" Vector__XXX
 SG_ DIR_appGitHash m17 : 8|56@1+ (1,0) [0|0] "" Vector__XXX
 SG_ DIR_bootGitHash m18 : 8|56@1+ (1,0) [0|0] "" Vector__XXX
 SG_ DIR_buildType m10 : 8|3@1+ (1,0) [0|0] "" Vector__XXX
 SG_ DIR_infoBootLdUdsProtocolVersion m20 : 8|8@1+ (1,0) [0|0] "" Vector__XXX
 SG_ DIR_motorType m12 : 8|6@1+ (1,0) [0|0] "" Vector__XXX
 SG_ DIR_oilPumpBuildType m16 : 8|3@1+ (1,0) [0|0] "" Vector__XXX
 SG_ DIR_oilPumpPcbaId m33 : 8|8@1+ (1,0) [0|0] "" Vector__XXX
 SG_ DIR_platformTyp m19 : 8|8@1+ (1,0) [0|0] "" Vector__XXX
 SG_ DIR_refRotorFlux m35 : 8|16@1+ (0.0001,0) [0|0] "" Vector__XXX
 SG_ DIR_speedWearTotal m36 : 8|8@1+ (0.4,0) [0|0] "" Vector__XXX
 SG_ DIR_subcomponentGitHash m31 : 8|56@1+ (1,0) [0|0] "" Vector__XXX
 SG_ DIR_infoIndex M : 0|8@1+ (1,0) [0|0] "" Vector__XXX

BO_ 825 VCSEC_authentication: 8 Vector__XXX
 SG_ VCSEC_keyPairDesired : 63|1@1+ (1,0) [0|0] "" Vector__XXX
 SG_ VCSEC_remoteStartActive : 61|2@1+ (1,0) [0|0] "" Vector__XXX
 SG_ VCSEC_authRequested : 60|1@1+ (1,0) [0|0] "" Vector__XXX
 SG_ VCSEC_keyChannelIndexed : 56|4@1+ (1,0) [0|0] "" Vector__XXX
 SG_ VCSEC_simpleLockStatus : 54|2@1+ (1,0) [0|0] "" Vector__XXX
 SG_ VCSEC_lockIndicationRequest : 51|3@1+ (1,0) [0|0] "" Vector__XXX
 SG_ VCSEC_immobilizerState : 48|3@1+ (1,0) [0|0] "" Vector__XXX
 SG_ VCSEC_serviceDiagnosticRequest : 47|1@1+ (1,0) [0|0] "" Vector__XXX
 SG_ VCSEC_alarmStatus : 43|4@1+ (1,0) [0|0] "" Vector__XXX
 SG_ VCSEC_isBLEDeviceWithinSummonRange : 42|1@1+ (1,0) [0|0] "" Vector__XXX
 SG_ VCSEC_isKeyWithinSummonRange : 41|1@1+ (1,0) [0|0] "" Vector__XXX
 SG_ VCSEC_usingModifiedMACAddress : 40|1@1+ (1,0) [0|0] "" Vector__XXX
 SG_ VCSEC_frunkLockStatus : 39|1@1+ (1,0) [0|0] "" Vector__XXX
 SG_ VCSEC_MCUCommandType : 36|3@1+ (1,0) [0|0] "" Vector__XXX
 SG_ VCSEC_3rdPartyFrunkPLGRequest : 34|2@1+ (1,0) [0|0] "" Vector__XXX
 SG_ VCSEC_3rdPartyPLGRequest : 32|2@1+ (1,0) [0|0] "" Vector__XXX
 SG_ VCSEC_summonRequest : 29|3@1+ (1,0) [0|0] "" Vector__XXX
 SG_ VCSEC_lockRequestType : 24|5@1+ (1,0) [0|0] "" Vector__XXX
 SG_ VCSEC_trunkLockStatus : 23|1@1+ (1,0) [0|0] "" Vector__XXX
 SG_ VCSEC_rightRearLockStatus : 22|1@1+ (1,0) [0|0] "" Vector__XXX
 SG_ VCSEC_rightFrontLockStatus : 21|1@1+ (1,0) [0|0] "" Vector__XXX
 SG_ VCSEC_leftRearLockStatus : 20|1@1+ (1,0) [0|0] "" Vector__XXX
 SG_ VCSEC_leftFrontLockStatus : 19|1@1+ (1,0) [0|0] "" Vector__XXX
 SG_ VCSEC_chargePortLockStatus : 18|1@1+ (1,0) [0|0] "" Vector__XXX
 SG_ VCSEC_authenticationStatus : 16|2@1+ (1,0) [0|0] "" Vector__XXX
 SG_ VCSEC_vehicleLockStatus : 12|4@1+ (1,0) [0|0] "" Vector__XXX
 SG_ VCSEC_operationMode : 8|2@1+ (1,0) [0|0] "" Vector__XXX
 SG_ VCSEC_IDRequested : 7|1@1+ (1,0) [0|0] "" Vector__XXX
 SG_ VCSEC_authRejectionReason : 4|3@1+ (1,0) [0|0] "" Vector__XXX
 SG_ VCSEC_BLEConnectionCounter : 0|4@1+ (1,0) [0|0] "" Vector__XXX

BO_ 826 UI_range: 8 Vector__XXX
 SG_ UI_targetFullPackEnergy : 49|15@1+ (0.0061037018951994385,0) [0|0] "" Vector__XXX
 SG_ UI_softPackLimitPct : 34|15@1+ (0.0030518509475997192,0) [0|0] "" Vector__XXX
 SG_ UI_uSoe : 27|7@1+ (1,0) [0|0] "" Vector__XXX
 SG_ UI_soe : 20|7@1+ (1,0) [0|0] "" Vector__XXX
 SG_ UI_whpm : 10|10@1+ (1,0) [0|0] "" Vector__XXX
 SG_ UI_ratedRange : 0|10@1+ (1,0) [0|0] "" Vector__XXX

BO_ 829 CP_plcInfo: 8 Vector__XXX
 SG_ CP_plcPibCrc : 32|32@1+ (1,0) [0|0] "" Vector__XXX
 SG_ CP_plcFwCrc : 0|32@1+ (1,0) [0|0] "" Vector__XXX

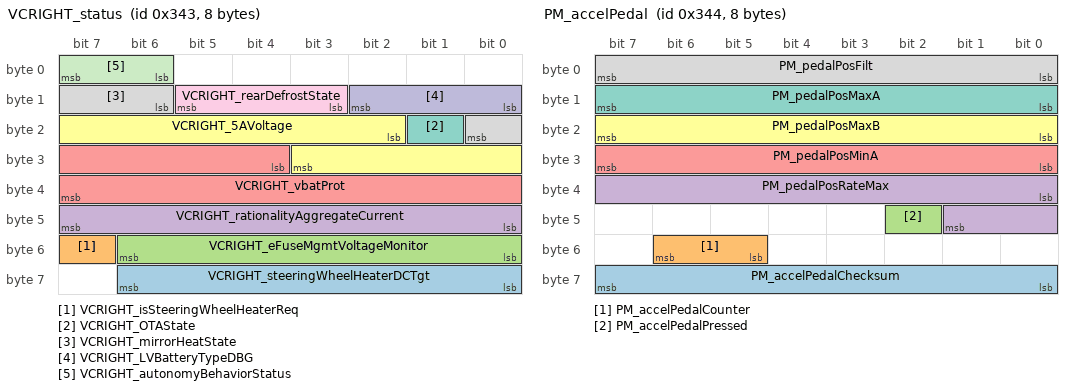
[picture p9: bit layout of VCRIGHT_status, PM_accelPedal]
BO_ 835 VCRIGHT_status: 8 Vector__XXX
 SG_ VCRIGHT_steeringWheelHeaterDCTgt : 56|7@1+ (0.01,0) [0|0] "" Vector__XXX
 SG_ VCRIGHT_isSteeringWheelHeaterReq : 55|1@1+ (1,0) [0|0] "" Vector__XXX
 SG_ VCRIGHT_eFuseMgmtVoltageMonitor : 48|7@1+ (0.125,0) [0|0] "" Vector__XXX
 SG_ VCRIGHT_rationalityAggregateCurrent : 40|8@1+ (0.5,0) [0|0] "" Vector__XXX
 SG_ VCRIGHT_vbatProt : 28|12@1+ (0.005443676098,0) [0|0] "" Vector__XXX
 SG_ VCRIGHT_5AVoltage : 18|10@1+ (0.005443676098,0) [0|0] "" Vector__XXX
 SG_ VCRIGHT_OTAState : 17|1@1+ (1,0) [0|0] "" Vector__XXX
 SG_ VCRIGHT_mirrorHeatState : 14|3@1+ (1,0) [0|0] "" Vector__XXX
 SG_ VCRIGHT_rearDefrostState : 11|3@1+ (1,0) [0|0] "" Vector__XXX
 SG_ VCRIGHT_LVBatteryTypeDBG : 8|3@1+ (1,0) [0|0] "" Vector__XXX
 SG_ VCRIGHT_autonomyBehaviorStatus : 6|2@1+ (1,0) [0|0] "" Vector__XXX

BO_ 836 PM_accelPedal: 8 Vector__XXX
 SG_ PM_accelPedalChecksum : 56|8@1+ (1,0) [0|0] "" Vector__XXX
 SG_ PM_accelPedalCounter : 53|2@1+ (1,0) [0|0] "" Vector__XXX
 SG_ PM_accelPedalPressed : 42|1@1+ (1,0) [0|0] "" Vector__XXX
 SG_ PM_pedalPosRateMax : 32|10@1+ (3,0) [0|0] "" Vector__XXX
 SG_ PM_pedalPosMinA : 24|8@1+ (0.4,0) [0|0] "" Vector__XXX
 SG_ PM_pedalPosMaxB : 16|8@1+ (0.4,0) [0|0] "" Vector__XXX
 SG_ PM_pedalPosMaxA : 8|8@1+ (0.4,0) [0|0] "" Vector__XXX
 SG_ PM_pedalPosFilt : 0|8@1+ (0.4,0) [0|0] "" Vector__XXX

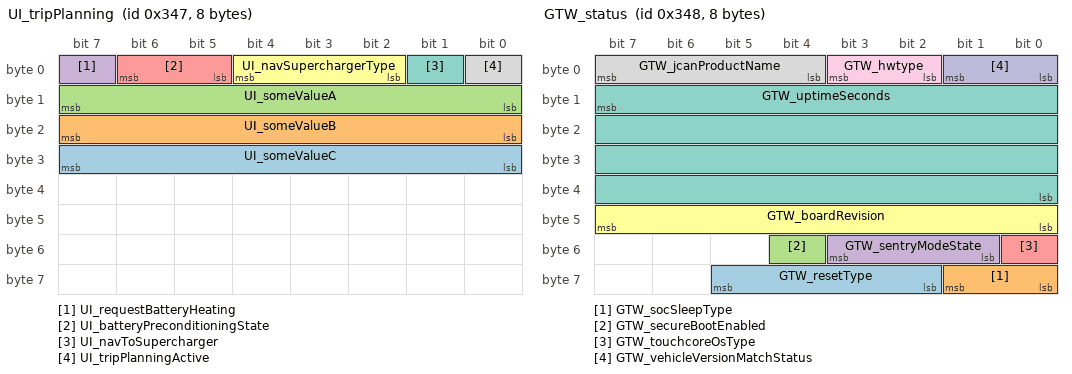
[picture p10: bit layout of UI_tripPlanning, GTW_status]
BO_ 839 UI_tripPlanning: 8 VEH
 SG_ UI_someValueC : 24|8@1+ (1,0) [0|255] ""  X
 SG_ UI_someValueB : 16|8@1+ (1,0) [0|255] ""  X
 SG_ UI_someValueA : 8|8@1+ (1,0) [0|255] ""  X
 SG_ UI_requestBatteryHeating : 7|1@1+ (1,0) [0|1] ""  X
 SG_ UI_batteryPreconditioningState : 5|2@1+ (1,0) [0|3] ""  X
 SG_ UI_navSuperchargerType : 2|3@1+ (1,0) [0|7] ""  X
 SG_ UI_navToSupercharger : 1|1@1+ (1,0) [0|1] ""  X
 SG_ UI_tripPlanningActive : 0|1@1+ (1,0) [0|1] ""  X

BO_ 840 GTW_status: 8 Vector__XXX
 SG_ GTW_resetType : 58|4@1+ (1,0) [0|0] "" Vector__XXX
 SG_ GTW_socSleepType : 56|2@1+ (1,0) [0|0] "" Vector__XXX
 SG_ GTW_secureBootEnabled : 52|1@1+ (1,0) [0|0] "" Vector__XXX
 SG_ GTW_sentryModeState : 49|3@1+ (1,0) [0|0] "" Vector__XXX
 SG_ GTW_touchcoreOsType : 48|1@1+ (1,0) [0|0] "" Vector__XXX
 SG_ GTW_boardRevision : 40|8@1+ (1,0) [0|0] "" Vector__XXX
 SG_ GTW_uptimeSeconds : 15|32@0+ (1,0) [0|0] "" Vector__XXX
 SG_ GTW_jcanProductName : 4|4@1+ (1,0) [0|0] "" Vector__XXX
 SG_ GTW_hwtype : 2|2@1+ (1,0) [0|0] "" Vector__XXX
 SG_ GTW_vehicleVersionMatchStatus : 0|2@1+ (1,0) [0|0] "" Vector__XXX

BO_ 842 VCSEC_NFCDebug: 8 Vector__XXX
 SG_ VCSEC_BPillarNFCStateReasonL m0 : 60|3@1+ (1,0) [0|0] "" Vector__XXX
 SG_ VCSEC_BPillarNFCStateReasonR m1 : 60|3@1+ (1,0) [0|0] "" Vector__XXX
 SG_ VCSEC_CenterNFCStateReason m2 : 60|4@1+ (1,0) [0|0] "" Vector__XXX
 SG_ VCSEC_BPillarNFCAntennaCalResultL m0 : 52|8@1+ (1,0) [0|0] "" Vector__XXX
 SG_ VCSEC_BPillarNFCAntennaCalResultR m1 : 52|8@1+ (1,0) [0|0] "" Vector__XXX
 SG_ VCSEC_CenterNFCAntennaCalResult m2 : 52|8@1+ (1,0) [0|0] "" Vector__XXX
 SG_ VCSEC_BPillarNFCDevLayerStateL m0 : 44|8@1+ (1,0) [0|0] "" Vector__XXX
 SG_ VCSEC_BPillarNFCDevLayerStateR m1 : 44|8@1+ (1,0) [0|0] "" Vector__XXX
 SG_ VCSEC_CenterNFCDevLayerState m2 : 44|8@1+ (1,0) [0|0] "" Vector__XXX
 SG_ VCSEC_BPillarNFCAmplitudeL m0 : 36|8@1+ (1,0) [0|0] "" Vector__XXX
 SG_ VCSEC_BPillarNFCAmplitudeR m1 : 36|8@1+ (1,0) [0|0] "" Vector__XXX
 SG_ VCSEC_CenterNFCAmplitude m2 : 36|8@1+ (1,0) [0|0] "" Vector__XXX
 SG_ VCSEC_BPillarNFCReaderStateL m0 : 28|2@1+ (1,0) [0|0] "" Vector__XXX
 SG_ VCSEC_BPillarNFCReaderStateR m1 : 28|2@1+ (1,0) [0|0] "" Vector__XXX
 SG_ VCSEC_CenterNFCReaderState m2 : 28|2@1+ (1,0) [0|0] "" Vector__XXX
 SG_ VCSEC_CenterNFCPhase m3 : 19|8@1+ (1,0) [0|0] "" Vector__XXX
 SG_ VCSEC_BPillarNFCWakeUpCounterL m0 : 12|16@1+ (1,0) [0|0] "" Vector__XXX
 SG_ VCSEC_BPillarNFCWakeUpCounterR m1 : 12|16@1+ (1,0) [0|0] "" Vector__XXX
 SG_ VCSEC_CenterNFCCardATQa m2 : 12|16@1+ (1,0) [0|0] "" Vector__XXX
 SG_ VCSEC_BPillarNFCPhaseR m3 : 11|8@1+ (1,0) [0|0] "" Vector__XXX
 SG_ VCSEC_BPillarNFCTrimSettingL m0 : 8|4@1+ (1,0) [0|0] "" Vector__XXX
 SG_ VCSEC_BPillarNFCTrimSettingR m1 : 8|4@1+ (1,0) [0|0] "" Vector__XXX
 SG_ VCSEC_CenterNFCTrimSetting m2 : 8|4@1+ (1,0) [0|0] "" Vector__XXX
 SG_ VCSEC_BPillarNFCCardUIDSizeL m0 : 4|4@1+ (1,0) [0|0] "" Vector__XXX
 SG_ VCSEC_BPillarNFCCardUIDSizeR m1 : 4|4@1+ (1,0) [0|0] "" Vector__XXX
 SG_ VCSEC_CenterNFCCardUIDSize m2 : 4|4@1+ (1,0) [0|0] "" Vector__XXX
 SG_ VCSEC_BPillarNFCCardCollisionL m0 : 3|1@1+ (1,0) [0|0] "" Vector__XXX
 SG_ VCSEC_BPillarNFCCardCollisionR m1 : 3|1@1+ (1,0) [0|0] "" Vector__XXX
 SG_ VCSEC_BPillarNFCPhaseL m3 : 3|8@1+ (1,0) [0|0] "" Vector__XXX
 SG_ VCSEC_CenterNFCCardCollision m2 : 3|1@1+ (1,0) [0|0] "" Vector__XXX
 SG_ VCSEC_NFCReaderIndexDebug M : 0|2@1+ (1,0) [0|0] "" Vector__XXX

BO_ 850 BMS_energyStatus: 8 VEH
 SG_ BMS_idealEnergyRemaining m0 : 48|16@1+ (0.02,0) [0|0] "kWh"  X
 SG_ BMS_energyToChargeComplete m1 : 48|16@1+ (0.02,0) [0|0] "kWh"  X
 SG_ BMS_nominalEnergyRemaining m0 : 32|16@1+ (0.02,0) [0|0] "kWh"  X
 SG_ BMS_expectedEnergyRemaining m1 : 32|16@1+ (0.02,0) [0|0] "kWh"  X
 SG_ BMS_nominalFullPackEnergy m0 : 16|16@1+ (0.02,0) [0|0] "kWh"  X
 SG_ BMS_energyBuffer m1 : 16|16@1+ (0.01,0) [0|0] "kWh"  X
 SG_ BMS_fullyCharged m1 : 15|1@1+ (1,0) [0|1] ""  X
 SG_ BMS_energyStatusIndex M : 0|2@1+ (1,0) [0|0] ""  X

BO_ 851 UI_status: 8 Vector__XXX
 SG_ UI_cpuTemperature : 56|8@1- (1,40) [0|0] "" Vector__XXX
 SG_ UI_pcbTemperature : 48|8@1- (1,40) [0|0] "" Vector__XXX
 SG_ UI_trailerModeTelltale : 45|2@1+ (1,0) [0|0] "" Vector__XXX
 SG_ UI_cellSignalBars : 42|3@1+ (1,0) [0|0] "" Vector__XXX
 SG_ UI_cameraActive : 41|1@1+ (1,0) [0|0] "" Vector__XXX
 SG_ UI_developmentCar : 40|1@1+ (1,0) [0|0] "" Vector__XXX
 SG_ UI_falseTouchCounter : 32|8@1+ (1,0) [0|0] "" Vector__XXX
 SG_ UI_cellReceiverPower : 24|8@1+ (1,-128) [0|0] "" Vector__XXX
 SG_ UI_cellNetworkTechnology : 19|4@1+ (1,0) [0|0] "" Vector__XXX
 SG_ UI_radioActive : 18|1@1+ (1,0) [0|0] "" Vector__XXX
 SG_ UI_screenshotActive : 17|1@1+ (1,0) [0|0] "" Vector__XXX
 SG_ UI_gpsActive : 16|1@1+ (1,0) [0|0] "" Vector__XXX
 SG_ UI_factoryReset : 14|2@1+ (1,0) [0|0] "" Vector__XXX
 SG_ UI_autopilotTrial : 12|2@1+ (1,0) [0|0] "" Vector__XXX
 SG_ UI_vpnActive : 11|1@1+ (1,0) [0|0] "" Vector__XXX
 SG_ UI_cellConnected : 10|1@1+ (1,0) [0|0] "" Vector__XXX
 SG_ UI_readyForDrive : 9|1@1+ (1,0) [0|0] "" Vector__XXX
 SG_ UI_systemActive : 8|1@1+ (1,0) [0|0] "" Vector__XXX
 SG_ UI_wifiConnected : 7|1@1+ (1,0) [0|0] "" Vector__XXX
 SG_ UI_wifiActive : 6|1@1+ (1,0) [0|0] "" Vector__XXX
 SG_ UI_displayOn : 5|1@1+ (1,0) [0|0] "" Vector__XXX
 SG_ UI_displayReady : 4|1@1+ (1,0) [0|0] "" Vector__XXX
 SG_ UI_cellActive : 3|1@1+ (1,0) [0|0] "" Vector__XXX
 SG_ UI_bluetoothActive : 2|1@1+ (1,0) [0|0] "" Vector__XXX
 SG_ UI_audioActive : 1|1@1+ (1,0) [0|0] "" Vector__XXX
 SG_ UI_touchActive : 0|1@1+ (1,0) [0|0] "" Vector__XXX

BO_ 853 UI_vehicleControlThermal: 7 Vector__XXX
 SG_ UI_enableAutopilotAirPurge : 49|1@1+ (1,0) [0|0] "" Vector__XXX
 SG_ UI_enableHVACAPFanHeaterControl : 48|1@1+ (1,0) [0|0] "" Vector__XXX
 SG_ UI_enableThermalPowerBudget : 46|1@1+ (1,0) [0|0] "" Vector__XXX
 SG_ UI_isAtTeslaFacility : 45|1@1+ (1,0) [0|0] "" Vector__XXX
 SG_ UI_disablePhoneChargingPads : 43|1@1+ (1,0) [0|0] "" Vector__XXX
 SG_ UI_enableHVACCompressorWasteHeat : 42|1@1+ (1,0) [0|0] "" Vector__XXX
 SG_ UI_enableDefaultApTempTarget : 41|1@1+ (1,0) [0|0] "" Vector__XXX
 SG_ UI_enableConservativeBatteryHeating : 40|1@1+ (1,0) [0|0] "" Vector__XXX
 SG_ UI_allowConvenienceFeatures : 39|1@1+ (1,0) [0|0] "" Vector__XXX
 SG_ UI_convenienceFeatureLimit : 32|7@1+ (1,0) [0|0] "" Vector__XXX
 SG_ UI_geofencedLiftgateHeight : 24|8@1+ (1,0) [0|0] "" Vector__XXX
 SG_ UI_enableCoolantDasTarget : 23|1@1+ (1,0) [0|0] "" Vector__XXX
 SG_ UI_enableThermalDriverlessSelfTest : 22|1@1+ (1,0) [0|0] "" Vector__XXX
 SG_ UI_enableEXVFastCalibration : 21|1@1+ (1,0) [0|0] "" Vector__XXX
 SG_ UI_disableHvacCameraOnlyDefog : 20|1@1+ (1,0) [0|0] "" Vector__XXX
 SG_ UI_enableUserFacingLowFlowDeliveryAlert : 19|1@1+ (1,0) [0|0] "" Vector__XXX
 SG_ UI_enableLouverAutoDetection : 18|1@1+ (1,0) [0|0] "" Vector__XXX
 SG_ UI_enableCOP1CabinHeatingBatteryHeating : 17|1@1+ (1,0) [0|0] "" Vector__XXX
 SG_ UI_enableCOP1BatteryHeating : 16|1@1+ (1,0) [0|0] "" Vector__XXX
 SG_ UI_enableIncreasedEvapRampRate : 15|1@1+ (1,0) [0|0] "" Vector__XXX
 SG_ UI_enableCOP1HighSHOperation : 14|1@1+ (1,0) [0|0] "" Vector__XXX
 SG_ UI_enableCompLiquidPumpOut : 13|1@1+ (1,0) [0|0] "" Vector__XXX
 SG_ UI_disableHVPTThermalLoads : 12|1@1+ (1,0) [0|0] "" Vector__XXX
 SG_ UI_inletActiveCoolTarget : 5|7@1+ (1,0) [0|0] "" Vector__XXX
 SG_ UI_coolantFlowRequest : 0|5@1+ (1,0) [0|0] "" Vector__XXX

BO_ 863 BMS_gridFormControl: 1 Vector__XXX
 SG_ BMS_gridFormOutletRequest : 2|2@1+ (1,0) [0|0] "" Vector__XXX
 SG_ BMS_weldCheckCpRequest : 1|1@1+ (1,0) [0|0] "" Vector__XXX
 SG_ BMS_gridFormCpRequest : 0|1@1+ (1,0) [0|0] "" Vector__XXX

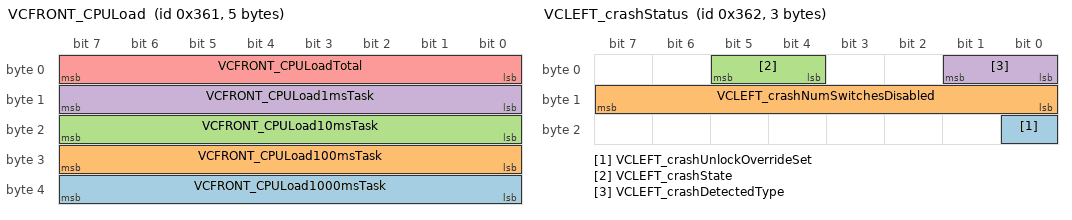
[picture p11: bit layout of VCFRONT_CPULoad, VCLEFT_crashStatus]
BO_ 865 VCFRONT_CPULoad: 5 Vector__XXX
 SG_ VCFRONT_CPULoad1000msTask : 32|8@1+ (1,0) [0|0] "" Vector__XXX
 SG_ VCFRONT_CPULoad100msTask : 24|8@1+ (1,0) [0|0] "" Vector__XXX
 SG_ VCFRONT_CPULoad10msTask : 16|8@1+ (1,0) [0|0] "" Vector__XXX
 SG_ VCFRONT_CPULoad1msTask : 8|8@1+ (1,0) [0|0] "" Vector__XXX
 SG_ VCFRONT_CPULoadTotal : 0|8@1+ (1,0) [0|0] "" Vector__XXX

BO_ 866 VCLEFT_crashStatus: 3 Vector__XXX
 SG_ VCLEFT_crashUnlockOverrideSet : 16|1@1+ (1,0) [0|0] "" Vector__XXX
 SG_ VCLEFT_crashNumSwitchesDisabled : 8|8@1+ (1,0) [0|0] "" Vector__XXX
 SG_ VCLEFT_crashState : 4|2@1+ (1,0) [0|0] "" Vector__XXX
 SG_ VCLEFT_crashDetectedType : 0|2@1+ (1,0) [0|0] "" Vector__XXX

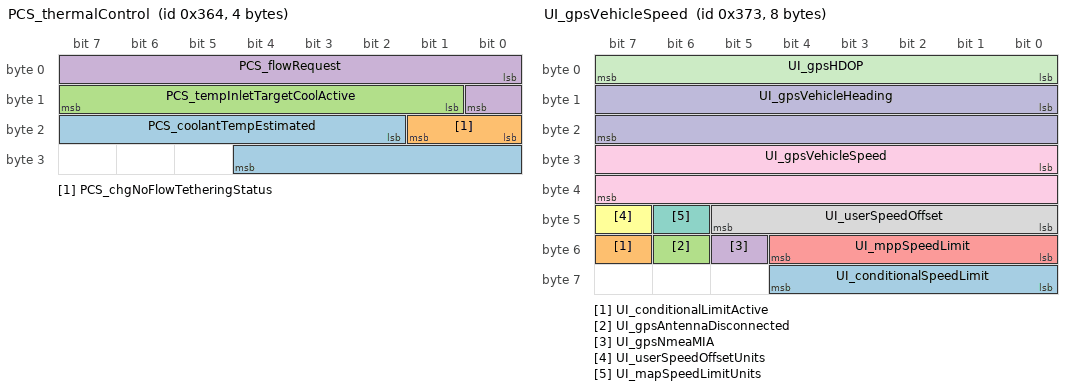
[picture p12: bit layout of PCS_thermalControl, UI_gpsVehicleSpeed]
BO_ 868 PCS_thermalControl: 4 Vector__XXX
 SG_ PCS_coolantTempEstimated : 18|11@1- (0.1,40) [0|0] "" Vector__XXX
 SG_ PCS_chgNoFlowTetheringStatus : 16|2@1+ (1,0) [0|0] "" Vector__XXX
 SG_ PCS_tempInletTargetCoolActive : 9|7@1+ (1,0) [0|0] "" Vector__XXX
 SG_ PCS_flowRequest : 0|9@1+ (0.1,0) [0|0] "" Vector__XXX

BO_ 869 SCS_alertMatrix1: 8 Vector__XXX
 SG_ SCS_a064_vehicleCommandTimeout : 63|1@1+ (1,0) [0|0] "" Vector__XXX
 SG_ SCS_a063_canRationality : 62|1@1+ (1,0) [0|0] "" Vector__XXX
 SG_ SCS_a062_unused : 61|1@1+ (1,0) [0|0] "" Vector__XXX
 SG_ SCS_a061_postOutOfService : 60|1@1+ (1,0) [0|0] "" Vector__XXX
 SG_ SCS_a060_swHVIL : 59|1@1+ (1,0) [0|0] "" Vector__XXX
 SG_ SCS_a059_memoryError : 58|1@1+ (1,0) [0|0] "" Vector__XXX
 SG_ SCS_a058_adcRef : 57|1@1+ (1,0) [0|0] "" Vector__XXX
 SG_ SCS_a057_watchdogReset : 56|1@1+ (1,0) [0|0] "" Vector__XXX
 SG_ SCS_a056_stateTransitionDenied : 55|1@1+ (1,0) [0|0] "" Vector__XXX
 SG_ SCS_a055_coolantLevelLow : 54|1@1+ (1,0) [0|0] "" Vector__XXX
 SG_ SCS_a054_pumpRegulation : 53|1@1+ (1,0) [0|0] "" Vector__XXX
 SG_ SCS_a053_unexpectedThermalBehavi : 52|1@1+ (1,0) [0|0] "" Vector__XXX
 SG_ SCS_a052_ambientTempRationality : 51|1@1+ (1,0) [0|0] "" Vector__XXX
 SG_ SCS_a051_cordTempRationality : 50|1@1+ (1,0) [0|0] "" Vector__XXX
 SG_ SCS_a050_coolantTempRationality : 49|1@1+ (1,0) [0|0] "" Vector__XXX
 SG_ SCS_a049_pcbaTempRationality : 48|1@1+ (1,0) [0|0] "" Vector__XXX
 SG_ SCS_a048_ambientOT : 47|1@1+ (1,0) [0|0] "" Vector__XXX
 SG_ SCS_a047_cordOT : 46|1@1+ (1,0) [0|0] "" Vector__XXX
 SG_ SCS_a046_coolantOT : 45|1@1+ (1,0) [0|0] "" Vector__XXX
 SG_ SCS_a045_pcbaOT : 44|1@1+ (1,0) [0|0] "" Vector__XXX
 SG_ SCS_a044_proximityRationality : 43|1@1+ (1,0) [0|0] "" Vector__XXX
 SG_ SCS_a043_pilotRationality : 42|1@1+ (1,0) [0|0] "" Vector__XXX
 SG_ SCS_a042_pilotOutOfRange : 41|1@1+ (1,0) [0|0] "" Vector__XXX
 SG_ SCS_a041_minus12VOutOfRange : 40|1@1+ (1,0) [0|0] "" Vector__XXX
 SG_ SCS_a040_plus12VOutOfRange : 39|1@1+ (1,0) [0|0] "" Vector__XXX
 SG_ SCS_a039_ibatRegulation : 38|1@1+ (1,0) [0|0] "" Vector__XXX
 SG_ SCS_a038_contactorFailedOpen : 37|1@1+ (1,0) [0|0] "" Vector__XXX
 SG_ SCS_a037_outputContactorWelded : 36|1@1+ (1,0) [0|0] "" Vector__XXX
 SG_ SCS_a036_internalContactorWelded : 35|1@1+ (1,0) [0|0] "" Vector__XXX
 SG_ SCS_a035_unexpectedVbusBehavior : 34|1@1+ (1,0) [0|0] "" Vector__XXX
 SG_ SCS_a034_IBatRationality : 33|1@1+ (1,0) [0|0] "" Vector__XXX
 SG_ SCS_a033_VBusRationality : 32|1@1+ (1,0) [0|0] "" Vector__XXX
 SG_ SCS_a032_VBatRationality : 31|1@1+ (1,0) [0|0] "" Vector__XXX
 SG_ SCS_a031_IbatOC : 30|1@1+ (1,0) [0|0] "" Vector__XXX
 SG_ SCS_a030_VbusOV : 29|1@1+ (1,0) [0|0] "" Vector__XXX
 SG_ SCS_a029_VbatOV : 28|1@1+ (1,0) [0|0] "" Vector__XXX
 SG_ SCS_a028_isolationRationality : 27|1@1+ (1,0) [0|0] "" Vector__XXX
 SG_ SCS_a027_externalIsolationLow : 26|1@1+ (1,0) [0|0] "" Vector__XXX
 SG_ SCS_a026_internalIsolationLow : 25|1@1+ (1,0) [0|0] "" Vector__XXX
 SG_ SCS_a025_internalIsolationFault : 24|1@1+ (1,0) [0|0] "" Vector__XXX
 SG_ SCS_a024_emergencyShutdown : 23|1@1+ (1,0) [0|0] "" Vector__XXX
 SG_ SCS_a021_unusedHW21 : 20|1@1+ (1,0) [0|0] "" Vector__XXX
 SG_ SCS_a020_unusedHW20 : 19|1@1+ (1,0) [0|0] "" Vector__XXX
 SG_ SCS_a019_unusedHW19 : 18|1@1+ (1,0) [0|0] "" Vector__XXX
 SG_ SCS_a018_unusedHW18 : 17|1@1+ (1,0) [0|0] "" Vector__XXX
 SG_ SCS_a017_unusedHW17 : 16|1@1+ (1,0) [0|0] "" Vector__XXX
 SG_ SCS_a016_unusedHW16 : 15|1@1+ (1,0) [0|0] "" Vector__XXX
 SG_ SCS_a015_cpldRationality : 14|1@1+ (1,0) [0|0] "" Vector__XXX
 SG_ SCS_a014_coolantTempHiFoldBk : 13|1@1+ (1,0) [0|0] "" Vector__XXX
 SG_ SCS_a013_cordTempHiFoldBk : 12|1@1+ (1,0) [0|0] "" Vector__XXX
 SG_ SCS_a012_hwIllegalCntrCmdV2 : 11|1@1+ (1,0) [0|0] "" Vector__XXX
 SG_ SCS_a011_hwIllegalCntrCmdV1 : 10|1@1+ (1,0) [0|0] "" Vector__XXX
 SG_ SCS_a010_hwOpen_V2 : 9|1@1+ (1,0) [0|0] "" Vector__XXX
 SG_ SCS_a009_hwOpen_V1 : 8|1@1+ (1,0) [0|0] "" Vector__XXX
 SG_ SCS_a008_hwIllegalCntrShoot : 7|1@1+ (1,0) [0|0] "" Vector__XXX
 SG_ SCS_a007_hwWeld_V2 : 6|1@1+ (1,0) [0|0] "" Vector__XXX
 SG_ SCS_a006_hwWeld_V1 : 5|1@1+ (1,0) [0|0] "" Vector__XXX
 SG_ SCS_a005_hwHVIL : 4|1@1+ (1,0) [0|0] "" Vector__XXX
 SG_ SCS_a004_hwVbusOV : 3|1@1+ (1,0) [0|0] "" Vector__XXX
 SG_ SCS_a003_hwCordOT : 2|1@1+ (1,0) [0|0] "" Vector__XXX
 SG_ SCS_a002_hwIbatOC : 1|1@1+ (1,0) [0|0] "" Vector__XXX
 SG_ SCS_a001_hwDSPfault : 0|1@1+ (1,0) [0|0] "" Vector__XXX

BO_ 870 CMPD_info: 8 Vector__XXX
 SG_ CMPD_infoComponentId m10 : 48|16@1+ (1,0) [0|0] "" Vector__XXX
 SG_ CMPD_infoSubUsageId m11 : 48|16@1+ (1,0) [0|0] "" Vector__XXX
 SG_ CMPD_infoBootCrc m20 : 32|32@1+ (1,0) [0|0] "" Vector__XXX
 SG_ CMPD_infoHardwareId m10 : 32|16@1+ (1,0) [0|0] "" Vector__XXX
 SG_ CMPD_infoUsageId m11 : 32|16@1+ (1,0) [0|0] "" Vector__XXX
 SG_ CMPD_infoAppCrc m13 : 39|32@0+ (1,0) [0|0] "" Vector__XXX
 SG_ CMPD_infoAssemblyId m11 : 24|8@1+ (1,0) [0|0] "" Vector__XXX
 SG_ CMPD_infoBuildConfigId m10 : 16|16@1+ (1,0) [0|0] "" Vector__XXX
 SG_ CMPD_infoPcbaId m11 : 16|8@1+ (1,0) [0|0] "" Vector__XXX
 SG_ CMPD_infoBootUdsProtoVersion m20 : 8|8@1+ (1,0) [0|0] "" Vector__XXX
 SG_ CMPD_infoBuildType m10 : 8|8@1+ (1,0) [0|0] "" Vector__XXX
 SG_ CMPD_infoPlatformType m13 : 8|8@1+ (1,0) [0|0] "" Vector__XXX
 SG_ CMPD_infoIndex M : 0|8@1+ (1,0) [0|0] "" Vector__XXX

BO_ 871 DI_alertMatrix1: 8 Vector__XXX
 SG_ DI_a064_pmsrmUnitMiaWithHvDown : 63|1@1+ (1,0) [0|0] "" Vector__XXX
 SG_ DI_a063_systemGracefulPowerOff : 62|1@1+ (1,0) [0|0] "" Vector__XXX
 SG_ DI_a062_systemLimpMode : 61|1@1+ (1,0) [0|0] "" Vector__XXX
 SG_ DI_a061_canHardwareBusE : 60|1@1+ (1,0) [0|0] "" Vector__XXX
 SG_ DI_a060_canOverrunBusE : 59|1@1+ (1,0) [0|0] "" Vector__XXX
 SG_ DI_a059_canDataBusE : 58|1@1+ (1,0) [0|0] "" Vector__XXX
 SG_ DI_a058_canHardwareBusD : 57|1@1+ (1,0) [0|0] "" Vector__XXX
 SG_ DI_a057_canOverrunBusD : 56|1@1+ (1,0) [0|0] "" Vector__XXX
 SG_ DI_a056_canDataBusD : 55|1@1+ (1,0) [0|0] "" Vector__XXX
 SG_ DI_a055_canHardwareBusC : 54|1@1+ (1,0) [0|0] "" Vector__XXX
 SG_ DI_a054_canOverrunBusC : 53|1@1+ (1,0) [0|0] "" Vector__XXX
 SG_ DI_a053_canDataBusC : 52|1@1+ (1,0) [0|0] "" Vector__XXX
 SG_ DI_a052_dirMIA : 51|1@1+ (1,0) [0|0] "" Vector__XXX
 SG_ DI_a051_batteryOvercurrent : 50|1@1+ (1,0) [0|0] "" Vector__XXX
 SG_ DI_a048_ecuLogAvailable : 47|1@1+ (1,0) [0|0] "" Vector__XXX
 SG_ DI_a043_pmrMIA : 42|1@1+ (1,0) [0|0] "" Vector__XXX
 SG_ DI_a042_pmfMIA : 41|1@1+ (1,0) [0|0] "" Vector__XXX
 SG_ DI_a041_driverBrakeApplyStuck : 40|1@1+ (1,0) [0|0] "" Vector__XXX
 SG_ DI_a040_difMIA : 39|1@1+ (1,0) [0|0] "" Vector__XXX
 SG_ DI_a036_sysStandbyUnitLimitedWait : 35|1@1+ (1,0) [0|0] "" Vector__XXX
 SG_ DI_a031_closureAccelerationLimit : 30|1@1+ (1,0) [0|0] "" Vector__XXX
 SG_ DI_a027_steeringAngleOffsetService : 26|1@1+ (1,0) [0|0] "" Vector__XXX
 SG_ DI_a026_parkPressedWithHighAPedal : 25|1@1+ (1,0) [0|0] "" Vector__XXX
 SG_ DI_a025_regenBackfillUnavailable : 24|1@1+ (1,0) [0|0] "" Vector__XXX
 SG_ DI_a024_holdNForNeutral : 23|1@1+ (1,0) [0|0] "" Vector__XXX
 SG_ DI_a023_carNotParked : 22|1@1+ (1,0) [0|0] "" Vector__XXX
 SG_ DI_a022_hw5vSupplyUV : 21|1@1+ (1,0) [0|0] "" Vector__XXX
 SG_ DI_a021_packOvervoltage : 20|1@1+ (1,0) [0|0] "" Vector__XXX
 SG_ DI_a019_hwAccelPedalPower : 18|1@1+ (1,0) [0|0] "" Vector__XXX
 SG_ DI_a018_hwLVSupplyUV : 17|1@1+ (1,0) [0|0] "" Vector__XXX
 SG_ DI_a017_hwPedalMonitor : 16|1@1+ (1,0) [0|0] "" Vector__XXX
 SG_ DI_a016_parkRequestByPM : 15|1@1+ (1,0) [0|0] "" Vector__XXX
 SG_ DI_a015_immobilizer : 14|1@1+ (1,0) [0|0] "" Vector__XXX
 SG_ DI_a013_eccError : 12|1@1+ (1,0) [0|0] "" Vector__XXX
 SG_ DI_a012_accel5VSupply : 11|1@1+ (1,0) [0|0] "" Vector__XXX
 SG_ DI_a010_unintendedReset : 9|1@1+ (1,0) [0|0] "" Vector__XXX
 SG_ DI_a005_stalkPanicked : 4|1@1+ (1,0) [0|0] "" Vector__XXX
 SG_ DI_a002_parkButtonDuringStalkReq : 1|1@1+ (1,0) [0|0] "" Vector__XXX
 SG_ DI_a001_frunkSpeedLimitActive : 0|1@1+ (1,0) [0|0] "" Vector__XXX

BO_ 880 SCS_alertMatrix2: 8 Vector__XXX
 SG_ SCS_a128_unused128 : 63|1@1+ (1,0) [0|0] "" Vector__XXX
 SG_ SCS_a127_unused127 : 62|1@1+ (1,0) [0|0] "" Vector__XXX
 SG_ SCS_a126_unused126 : 61|1@1+ (1,0) [0|0] "" Vector__XXX
 SG_ SCS_a125_unused125 : 60|1@1+ (1,0) [0|0] "" Vector__XXX
 SG_ SCS_a124_unused124 : 59|1@1+ (1,0) [0|0] "" Vector__XXX
 SG_ SCS_a123_unused123 : 58|1@1+ (1,0) [0|0] "" Vector__XXX
 SG_ SCS_a122_unused122 : 57|1@1+ (1,0) [0|0] "" Vector__XXX
 SG_ SCS_a121_unused121 : 56|1@1+ (1,0) [0|0] "" Vector__XXX
 SG_ SCS_a120_unused120 : 55|1@1+ (1,0) [0|0] "" Vector__XXX
 SG_ SCS_a119_unused119 : 54|1@1+ (1,0) [0|0] "" Vector__XXX
 SG_ SCS_a118_unused118 : 53|1@1+ (1,0) [0|0] "" Vector__XXX
 SG_ SCS_a117_unused117 : 52|1@1+ (1,0) [0|0] "" Vector__XXX
 SG_ SCS_a116_unused116 : 51|1@1+ (1,0) [0|0] "" Vector__XXX
 SG_ SCS_a115_unused115 : 50|1@1+ (1,0) [0|0] "" Vector__XXX
 SG_ SCS_a114_unused114 : 49|1@1+ (1,0) [0|0] "" Vector__XXX
 SG_ SCS_a113_unused113 : 48|1@1+ (1,0) [0|0] "" Vector__XXX
 SG_ SCS_a112_unused112 : 47|1@1+ (1,0) [0|0] "" Vector__XXX
 SG_ SCS_a111_unused111 : 46|1@1+ (1,0) [0|0] "" Vector__XXX
 SG_ SCS_a110_unused110 : 45|1@1+ (1,0) [0|0] "" Vector__XXX
 SG_ SCS_a109_unused109 : 44|1@1+ (1,0) [0|0] "" Vector__XXX
 SG_ SCS_a108_unused108 : 43|1@1+ (1,0) [0|0] "" Vector__XXX
 SG_ SCS_a107_unused107 : 42|1@1+ (1,0) [0|0] "" Vector__XXX
 SG_ SCS_a106_unused106 : 41|1@1+ (1,0) [0|0] "" Vector__XXX
 SG_ SCS_a105_unused105 : 40|1@1+ (1,0) [0|0] "" Vector__XXX
 SG_ SCS_a104_unused104 : 39|1@1+ (1,0) [0|0] "" Vector__XXX
 SG_ SCS_a103_unused103 : 38|1@1+ (1,0) [0|0] "" Vector__XXX
 SG_ SCS_a102_unused102 : 37|1@1+ (1,0) [0|0] "" Vector__XXX
 SG_ SCS_a101_unused101 : 36|1@1+ (1,0) [0|0] "" Vector__XXX
 SG_ SCS_a100_unused100 : 35|1@1+ (1,0) [0|0] "" Vector__XXX
 SG_ SCS_a099_unused99 : 34|1@1+ (1,0) [0|0] "" Vector__XXX
 SG_ SCS_a098_unused98 : 33|1@1+ (1,0) [0|0] "" Vector__XXX
 SG_ SCS_a097_unused97 : 32|1@1+ (1,0) [0|0] "" Vector__XXX
 SG_ SCS_a096_unused96 : 31|1@1+ (1,0) [0|0] "" Vector__XXX
 SG_ SCS_a095_unused95 : 30|1@1+ (1,0) [0|0] "" Vector__XXX
 SG_ SCS_a094_unused94 : 29|1@1+ (1,0) [0|0] "" Vector__XXX
 SG_ SCS_a093_unused93 : 28|1@1+ (1,0) [0|0] "" Vector__XXX
 SG_ SCS_a092_cabEnableDeasserted : 27|1@1+ (1,0) [0|0] "" Vector__XXX
 SG_ SCS_a091_voltageRiseDetection : 26|1@1+ (1,0) [0|0] "" Vector__XXX
 SG_ SCS_a090_negCordOT : 25|1@1+ (1,0) [0|0] "" Vector__XXX
 SG_ SCS_a089_posCordOT : 24|1@1+ (1,0) [0|0] "" Vector__XXX
 SG_ SCS_a088_negCordTempRationality : 23|1@1+ (1,0) [0|0] "" Vector__XXX
 SG_ SCS_a087_posCordTempRationality : 22|1@1+ (1,0) [0|0] "" Vector__XXX
 SG_ SCS_a086_lccResetDetected : 21|1@1+ (1,0) [0|0] "" Vector__XXX
 SG_ SCS_a085_unused85 : 20|1@1+ (1,0) [0|0] "" Vector__XXX
 SG_ SCS_a084_unused84 : 19|1@1+ (1,0) [0|0] "" Vector__XXX
 SG_ SCS_a083_chargeCurrentLimited : 18|1@1+ (1,0) [0|0] "" Vector__XXX
 SG_ SCS_a082_VbatUV : 17|1@1+ (1,0) [0|0] "" Vector__XXX
 SG_ SCS_a081_rmsInputVoltageHigh : 16|1@1+ (1,0) [0|0] "" Vector__XXX
 SG_ SCS_a080_lccFaulted : 15|1@1+ (1,0) [0|0] "" Vector__XXX
 SG_ SCS_a079_unexpectedVbat : 14|1@1+ (1,0) [0|0] "" Vector__XXX
 SG_ SCS_a078_voltageMatchTimeout : 13|1@1+ (1,0) [0|0] "" Vector__XXX
 SG_ SCS_a077_unexpectedVbatBehavior : 12|1@1+ (1,0) [0|0] "" Vector__XXX
 SG_ SCS_a076_bmsMIA : 11|1@1+ (1,0) [0|0] "" Vector__XXX
 SG_ SCS_a075_unused75 : 10|1@1+ (1,0) [0|0] "" Vector__XXX
 SG_ SCS_a074_isoVDiffHi : 9|1@1+ (1,0) [0|0] "" Vector__XXX
 SG_ SCS_a073_lccMIA : 8|1@1+ (1,0) [0|0] "" Vector__XXX
 SG_ SCS_a072_gtwMIA : 7|1@1+ (1,0) [0|0] "" Vector__XXX
 SG_ SCS_a071_chargerMIA : 6|1@1+ (1,0) [0|0] "" Vector__XXX
 SG_ SCS_a070_vStageRationalityV2 : 5|1@1+ (1,0) [0|0] "" Vector__XXX
 SG_ SCS_a069_vStageRationalityV1 : 4|1@1+ (1,0) [0|0] "" Vector__XXX
 SG_ SCS_a068_vBatRationalityStage4 : 3|1@1+ (1,0) [0|0] "" Vector__XXX
 SG_ SCS_a067_vBatRationalityStage3 : 2|1@1+ (1,0) [0|0] "" Vector__XXX
 SG_ SCS_a066_vBatRationalityStage2 : 1|1@1+ (1,0) [0|0] "" Vector__XXX
 SG_ SCS_a065_vBatRationalityStage1 : 0|1@1+ (1,0) [0|0] "" Vector__XXX

BO_ 883 UI_gpsVehicleSpeed: 8 Vector__XXX
 SG_ UI_conditionalSpeedLimit : 56|5@1+ (5,0) [0|0] "" Vector__XXX
 SG_ UI_conditionalLimitActive : 55|1@1+ (1,0) [0|0] "" Vector__XXX
 SG_ UI_gpsAntennaDisconnected : 54|1@1+ (1,0) [0|0] "" Vector__XXX
 SG_ UI_gpsNmeaMIA : 53|1@1+ (1,0) [0|0] "" Vector__XXX
 SG_ UI_mppSpeedLimit : 48|5@1+ (5,0) [0|0] "" Vector__XXX
 SG_ UI_userSpeedOffsetUnits : 47|1@1+ (1,0) [0|0] "" Vector__XXX
 SG_ UI_mapSpeedLimitUnits : 46|1@1+ (1,0) [0|0] "" Vector__XXX
 SG_ UI_userSpeedOffset : 40|6@1+ (1,-30) [0|0] "" Vector__XXX
 SG_ UI_gpsVehicleSpeed : 24|16@1+ (0.00390625,0) [0|0] "" Vector__XXX
 SG_ UI_gpsVehicleHeading : 8|16@1+ (0.0078125,0) [0|0] "" Vector__XXX
 SG_ UI_gpsHDOP : 0|8@1+ (0.1,0) [0|0] "" Vector__XXX

BO_ 890 VCSEC_ConnectionMonitor: 8 Vector__XXX
 SG_ VCSEC_CMTimeSyncFailL0 m2 : 56|8@1+ (1,0) [0|0] "" Vector__XXX
 SG_ VCSEC_CMTimeSyncFailR0 m1 : 56|8@1+ (1,0) [0|0] "" Vector__XXX
 SG_ VCSEC_CMTimeSyncFailRi0 m0 : 56|8@1+ (1,0) [0|0] "" Vector__XXX
 SG_ VCSEC_CMEventOutsideWinL0 m2 : 48|8@1+ (1,0) [0|0] "" Vector__XXX
 SG_ VCSEC_CMEventOutsideWinR0 m1 : 48|8@1+ (1,0) [0|0] "" Vector__XXX
 SG_ VCSEC_CMEventOutsideWinRi0 m0 : 48|8@1+ (1,0) [0|0] "" Vector__XXX
 SG_ VCSEC_CMEventIncorrectChannelL0 m2 : 40|8@1+ (1,0) [0|0] "" Vector__XXX
 SG_ VCSEC_CMEventIncorrectChannelR0 m1 : 40|8@1+ (1,0) [0|0] "" Vector__XXX
 SG_ VCSEC_CMEventIncorrectChannelRi0 m0 : 40|8@1+ (1,0) [0|0] "" Vector__XXX
 SG_ VCSEC_CMEventNonMatchingPktCountL0 m2 : 32|8@1+ (1,0) [0|0] "" Vector__XXX
 SG_ VCSEC_CMEventNonMatchingPktCountR0 m1 : 32|8@1+ (1,0) [0|0] "" Vector__XXX
 SG_ VCSEC_CMEventNonMatchingPktCountRi0 m0 : 32|8@1+ (1,0) [0|0] "" Vector__XXX
 SG_ VCSEC_CMEventSNNESNDeassertL0 m2 : 24|8@1+ (1,0) [0|0] "" Vector__XXX
 SG_ VCSEC_CMEventSNNESNDeassertR0 m1 : 24|8@1+ (1,0) [0|0] "" Vector__XXX
 SG_ VCSEC_CMEventSNNESNDeassertRi0 m0 : 24|8@1+ (1,0) [0|0] "" Vector__XXX
 SG_ VCSEC_BLE2ConnInterval m3 : 22|10@1+ (1,0) [0|0] "" Vector__XXX
 SG_ VCSEC_CMEventNonEmptyPacketsL0 m2 : 16|8@1+ (1,0) [0|0] "" Vector__XXX
 SG_ VCSEC_CMEventNonEmptyPacketsR0 m1 : 16|8@1+ (1,0) [0|0] "" Vector__XXX
 SG_ VCSEC_CMEventNonEmptyPacketsRi0 m0 : 16|8@1+ (1,0) [0|0] "" Vector__XXX
 SG_ VCSEC_BLE1ConnInterval m3 : 12|10@1+ (1,0) [0|0] "" Vector__XXX
 SG_ VCSEC_BLERSSITrackingPercentL2 m2 : 12|4@1+ (8,0) [0|0] "" Vector__XXX
 SG_ VCSEC_BLERSSITrackingPercentR2 m0 : 12|4@1+ (8,0) [0|0] "" Vector__XXX
 SG_ VCSEC_BLERSSITrackingPercentRe2 m1 : 12|4@1+ (8,0) [0|0] "" Vector__XXX
 SG_ VCSEC_BLERSSITrackingPercentL1 m2 : 8|4@1+ (8,0) [0|0] "" Vector__XXX
 SG_ VCSEC_BLERSSITrackingPercentR1 m0 : 8|4@1+ (8,0) [0|0] "" Vector__XXX
 SG_ VCSEC_BLERSSITrackingPercentRe1 m1 : 8|4@1+ (8,0) [0|0] "" Vector__XXX
 SG_ VCSEC_BLERSSITrackingPercentL0 m2 : 4|4@1+ (8,0) [0|0] "" Vector__XXX
 SG_ VCSEC_BLERSSITrackingPercentR0 m0 : 4|4@1+ (8,0) [0|0] "" Vector__XXX
 SG_ VCSEC_BLERSSITrackingPercentRe0 m1 : 4|4@1+ (8,0) [0|0] "" Vector__XXX
 SG_ VCSEC_BLE0ConnInterval m3 : 2|10@1+ (1,0) [0|0] "" Vector__XXX
 SG_ VCSEC_BLEConnectionMonitorIndex M : 0|2@1+ (1,0) [0|0] "" Vector__XXX

BO_ 893 CP_thermalStatus: 8 Vector__XXX
 SG_ CP_pinTemp3Velocity m0 : 53|10@1- (0.15748,0) [0|0] "" Vector__XXX
 SG_ CP_pinTemp2Velocity m0 : 43|10@1- (0.15748,0) [0|0] "" Vector__XXX
 SG_ CP_pinTemp4Velocity m1 : 40|10@1- (0.15748,0) [0|0] "" Vector__XXX
 SG_ CP_pinTemp1Velocity m0 : 33|10@1- (0.15748,0) [0|0] "" Vector__XXX
 SG_ CP_pinTemperature4 m1 : 32|8@1+ (0.8039215686,-55) [0|0] "" Vector__XXX
 SG_ CP_acPinTemperature2 m0 : 25|8@1+ (0.8039215686,-55) [0|0] "" Vector__XXX
 SG_ CP_pinTemperature3 m1 : 24|8@1+ (0.8039215686,-55) [0|0] "" Vector__XXX
 SG_ CP_acPinTemperature m0 : 17|8@1+ (0.8039215686,-55) [0|0] "" Vector__XXX
 SG_ CP_pinTemperature2 m1 : 16|8@1+ (0.8039215686,-55) [0|0] "" Vector__XXX
 SG_ CP_dcPinTemperature2 m0 : 9|8@1+ (0.8039215686,-55) [0|0] "" Vector__XXX
 SG_ CP_pinTemperature1 m1 : 8|8@1+ (0.8039215686,-55) [0|0] "" Vector__XXX
 SG_ CP_dcPinTemperature m0 : 1|8@1+ (0.8039215686,-55) [0|0] "" Vector__XXX
 SG_ CP_thermalStatusSelect M : 0|1@1+ (1,0) [0|0] "" Vector__XXX

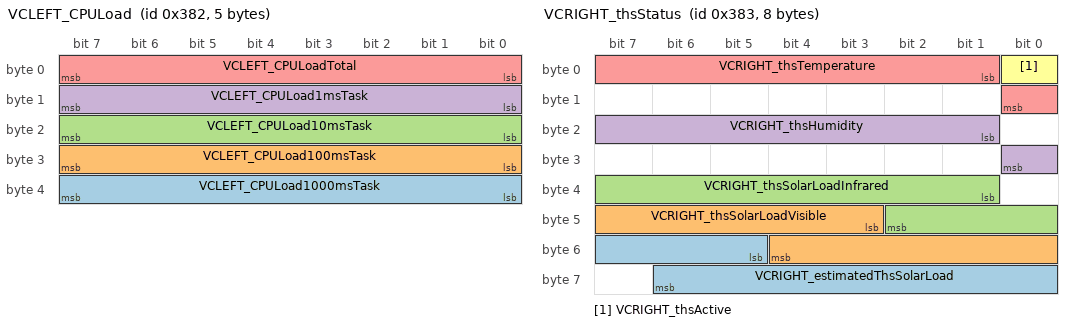
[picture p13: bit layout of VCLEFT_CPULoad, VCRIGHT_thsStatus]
BO_ 898 VCLEFT_CPULoad: 5 Vector__XXX
 SG_ VCLEFT_CPULoad1000msTask : 32|8@1+ (1,0) [0|0] "" Vector__XXX
 SG_ VCLEFT_CPULoad100msTask : 24|8@1+ (1,0) [0|0] "" Vector__XXX
 SG_ VCLEFT_CPULoad10msTask : 16|8@1+ (1,0) [0|0] "" Vector__XXX
 SG_ VCLEFT_CPULoad1msTask : 8|8@1+ (1,0) [0|0] "" Vector__XXX
 SG_ VCLEFT_CPULoadTotal : 0|8@1+ (1,0) [0|0] "" Vector__XXX

BO_ 899 VCRIGHT_thsStatus: 8 VEH
 SG_ VCRIGHT_estimatedThsSolarLoad : 53|10@1+ (1,0) [0|0] "W/m2"  X
 SG_ VCRIGHT_thsSolarLoadVisible : 43|10@1+ (1,0) [0|0] "W/m2"  X
 SG_ VCRIGHT_thsSolarLoadInfrared : 33|10@1+ (1,0) [0|0] "W/m2"  X
 SG_ VCRIGHT_thsHumidity : 17|8@1+ (1,0) [0|0] "%"  X
 SG_ VCRIGHT_thsTemperature : 1|8@1- (1,-40) [0|0] "degC"  X
 SG_ VCRIGHT_thsActive : 0|1@1+ (1,0) [0|0] ""  X

BO_ 900 PM_alertMatrix1: 8 Vector__XXX
 SG_ PM_a064_torqueIntervention : 63|1@1+ (1,0) [0|0] "" Vector__XXX
 SG_ PM_a063_torqueCommandInhibit : 62|1@1+ (1,0) [0|0] "" Vector__XXX
 SG_ PM_a062_eccError : 61|1@1+ (1,0) [0|0] "" Vector__XXX
 SG_ PM_a061_DIPMVersionMismatch : 60|1@1+ (1,0) [0|0] "" Vector__XXX
 SG_ PM_a060_onePedalDrivingInhibit : 59|1@1+ (1,0) [0|0] "" Vector__XXX
 SG_ PM_a059_ptcMIA : 58|1@1+ (1,0) [0|0] "" Vector__XXX
 SG_ PM_a058_cmpMIA : 57|1@1+ (1,0) [0|0] "" Vector__XXX
 SG_ PM_a057_canDataBusB : 56|1@1+ (1,0) [0|0] "" Vector__XXX
 SG_ PM_a056_canHardwareBusB : 55|1@1+ (1,0) [0|0] "" Vector__XXX
 SG_ PM_a055_accelPedalSyncWarn : 54|1@1+ (1,0) [0|0] "" Vector__XXX
 SG_ PM_a054_uiMIA : 53|1@1+ (1,0) [0|0] "" Vector__XXX
 SG_ PM_a053_vcfrontMIA : 52|1@1+ (1,0) [0|0] "" Vector__XXX
 SG_ PM_a052_stbCtrlDrvrDecelCflct : 51|1@1+ (1,0) [0|0] "" Vector__XXX
 SG_ PM_a051_unintDecelStbCtrl : 50|1@1+ (1,0) [0|0] "" Vector__XXX
 SG_ PM_a050_excessiveStbCtrlTrq : 49|1@1+ (1,0) [0|0] "" Vector__XXX
 SG_ PM_a049_stbCtrlInWrongDir : 48|1@1+ (1,0) [0|0] "" Vector__XXX
 SG_ PM_a048_stabilityControlInhibit : 47|1@1+ (1,0) [0|0] "" Vector__XXX
 SG_ PM_a047_inconsAutoparkState : 46|1@1+ (1,0) [0|0] "" Vector__XXX
 SG_ PM_a046_inconsVehicleHoldState : 45|1@1+ (1,0) [0|0] "" Vector__XXX
 SG_ PM_a045_regenBackfillIntervention : 44|1@1+ (1,0) [0|0] "" Vector__XXX
 SG_ PM_a044_ebrIntervention : 43|1@1+ (1,0) [0|0] "" Vector__XXX
 SG_ PM_a043_inconsistentConfig : 42|1@1+ (1,0) [0|0] "" Vector__XXX
 SG_ PM_a042_gtwMIA : 41|1@1+ (1,0) [0|0] "" Vector__XXX
 SG_ PM_a041_dasMIA : 40|1@1+ (1,0) [0|0] "" Vector__XXX
 SG_ PM_a040_alignmentDriftDetected : 39|1@1+ (1,0) [0|0] "" Vector__XXX
 SG_ PM_a039_disMIA : 38|1@1+ (1,0) [0|0] "" Vector__XXX
 SG_ PM_a038_inconsistentTorqueSign : 37|1@1+ (1,0) [0|0] "" Vector__XXX
 SG_ PM_a036_preWatchdog : 35|1@1+ (1,0) [0|0] "" Vector__XXX
 SG_ PM_a035_udsTransactionInitiated : 34|1@1+ (1,0) [0|0] "" Vector__XXX
 SG_ PM_a034_trqCrossCheck : 33|1@1+ (1,0) [0|0] "" Vector__XXX
 SG_ PM_a033_appMIA : 32|1@1+ (1,0) [0|0] "" Vector__XXX
 SG_ PM_a032_registerConfigError : 31|1@1+ (1,0) [0|0] "" Vector__XXX
 SG_ PM_a031_highStackUsage : 30|1@1+ (1,0) [0|0] "" Vector__XXX
 SG_ PM_a030_inconsistentAebState : 29|1@1+ (1,0) [0|0] "" Vector__XXX
 SG_ PM_a029_cruiseRollback : 28|1@1+ (1,0) [0|0] "" Vector__XXX
 SG_ PM_a028_torqueCmdError : 27|1@1+ (1,0) [0|0] "" Vector__XXX
 SG_ PM_a026_diHeartBeatMIA : 25|1@1+ (1,0) [0|0] "" Vector__XXX
 SG_ PM_a025_unintendedReset : 24|1@1+ (1,0) [0|0] "" Vector__XXX
 SG_ PM_a024_brakeIrrational : 23|1@1+ (1,0) [0|0] "" Vector__XXX
 SG_ PM_a023_cruiseInhibit : 22|1@1+ (1,0) [0|0] "" Vector__XXX
 SG_ PM_a022_dirMIA : 21|1@1+ (1,0) [0|0] "" Vector__XXX
 SG_ PM_a021_difMIA : 20|1@1+ (1,0) [0|0] "" Vector__XXX
 SG_ PM_a019_vehicleSpeedQFDiagnostic : 18|1@1+ (1,0) [0|0] "" Vector__XXX
 SG_ PM_a017_brakeMIA : 16|1@1+ (1,0) [0|0] "" Vector__XXX
 SG_ PM_a015_shifterMIA : 14|1@1+ (1,0) [0|0] "" Vector__XXX
 SG_ PM_a014_accelPedalError : 13|1@1+ (1,0) [0|0] "" Vector__XXX
 SG_ PM_a013_canHardwareBusA : 12|1@1+ (1,0) [0|0] "" Vector__XXX
 SG_ PM_a012_canDataBusA : 11|1@1+ (1,0) [0|0] "" Vector__XXX
 SG_ PM_a010_diMIA : 9|1@1+ (1,0) [0|0] "" Vector__XXX
 SG_ PM_a009_espMIA : 8|1@1+ (1,0) [0|0] "" Vector__XXX
 SG_ PM_a008_memoryError : 7|1@1+ (1,0) [0|0] "" Vector__XXX
 SG_ PM_a007_ibstMIA : 6|1@1+ (1,0) [0|0] "" Vector__XXX
 SG_ PM_a006_inconsistentDIGear : 5|1@1+ (1,0) [0|0] "" Vector__XXX
 SG_ PM_a005_torqueInNeutralOrPark : 4|1@1+ (1,0) [0|0] "" Vector__XXX
 SG_ PM_a004_excessiveDecelTorque : 3|1@1+ (1,0) [0|0] "" Vector__XXX
 SG_ PM_a003_excessiveReversalTorque : 2|1@1+ (1,0) [0|0] "" Vector__XXX
 SG_ PM_a002_excessiveAccelTorque : 1|1@1+ (1,0) [0|0] "" Vector__XXX
 SG_ PM_a001_absoluteTorque : 0|1@1+ (1,0) [0|0] "" Vector__XXX

BO_ 902 PMR_alertMatrix1: 8 Vector__XXX
 SG_ PMR_a064_torqueIntervention : 63|1@1+ (1,0) [0|0] "" Vector__XXX
 SG_ PMR_a062_eccError : 61|1@1+ (1,0) [0|0] "" Vector__XXX
 SG_ PMR_a061_DIPMVersionMismatch : 60|1@1+ (1,0) [0|0] "" Vector__XXX
 SG_ PMR_a057_canDataBusB : 56|1@1+ (1,0) [0|0] "" Vector__XXX
 SG_ PMR_a056_canHardwareBusB : 55|1@1+ (1,0) [0|0] "" Vector__XXX
 SG_ PMR_a055_resolver : 54|1@1+ (1,0) [0|0] "" Vector__XXX
 SG_ PMR_a054_uiMIA : 53|1@1+ (1,0) [0|0] "" Vector__XXX
 SG_ PMR_a053_vcfrontMIA : 52|1@1+ (1,0) [0|0] "" Vector__XXX
 SG_ PMR_a045_motorMovementDetected : 44|1@1+ (1,0) [0|0] "" Vector__XXX
 SG_ PMR_a042_gtwMIA : 41|1@1+ (1,0) [0|0] "" Vector__XXX
 SG_ PMR_a040_pmMIA : 39|1@1+ (1,0) [0|0] "" Vector__XXX
 SG_ PMR_a039_disMIA : 38|1@1+ (1,0) [0|0] "" Vector__XXX
 SG_ PMR_a037_hvpMIA : 36|1@1+ (1,0) [0|0] "" Vector__XXX
 SG_ PMR_a036_preWatchdog : 35|1@1+ (1,0) [0|0] "" Vector__XXX
 SG_ PMR_a035_udsTransactionInitiated : 34|1@1+ (1,0) [0|0] "" Vector__XXX
 SG_ PMR_a034_trqCrossCheck : 33|1@1+ (1,0) [0|0] "" Vector__XXX
 SG_ PMR_a033_selfTest : 32|1@1+ (1,0) [0|0] "" Vector__XXX
 SG_ PMR_a032_registerConfigError : 31|1@1+ (1,0) [0|0] "" Vector__XXX
 SG_ PMR_a031_highStackUsage : 30|1@1+ (1,0) [0|0] "" Vector__XXX
 SG_ PMR_a028_torqueCmdError : 27|1@1+ (1,0) [0|0] "" Vector__XXX
 SG_ PMR_a027_torqueEstimationOutOfBounds : 26|1@1+ (1,0) [0|0] "" Vector__XXX
 SG_ PMR_a026_diHeartBeatMIA : 25|1@1+ (1,0) [0|0] "" Vector__XXX
 SG_ PMR_a025_unintendedReset : 24|1@1+ (1,0) [0|0] "" Vector__XXX
 SG_ PMR_a019_statorTempIrrational : 18|1@1+ (1,0) [0|0] "" Vector__XXX
 SG_ PMR_a018_encoderIrrational : 17|1@1+ (1,0) [0|0] "" Vector__XXX
 SG_ PMR_a017_brakeMIA : 16|1@1+ (1,0) [0|0] "" Vector__XXX
 SG_ PMR_a013_canHardwareBusA : 12|1@1+ (1,0) [0|0] "" Vector__XXX
 SG_ PMR_a012_canDataBusA : 11|1@1+ (1,0) [0|0] "" Vector__XXX
 SG_ PMR_a011_phaseCurrentIrrational : 10|1@1+ (1,0) [0|0] "" Vector__XXX
 SG_ PMR_a010_diMIA : 9|1@1+ (1,0) [0|0] "" Vector__XXX
 SG_ PMR_a008_memoryError : 7|1@1+ (1,0) [0|0] "" Vector__XXX
 SG_ PMR_a005_torqueInNeutralOrPark : 4|1@1+ (1,0) [0|0] "" Vector__XXX
 SG_ PMR_a004_excessiveDecelTorque : 3|1@1+ (1,0) [0|0] "" Vector__XXX
 SG_ PMR_a003_excessiveReversalTorque : 2|1@1+ (1,0) [0|0] "" Vector__XXX
 SG_ PMR_a002_excessiveAccelTorque : 1|1@1+ (1,0) [0|0] "" Vector__XXX
 SG_ PMR_a001_absoluteTorque : 0|1@1+ (1,0) [0|0] "" Vector__XXX

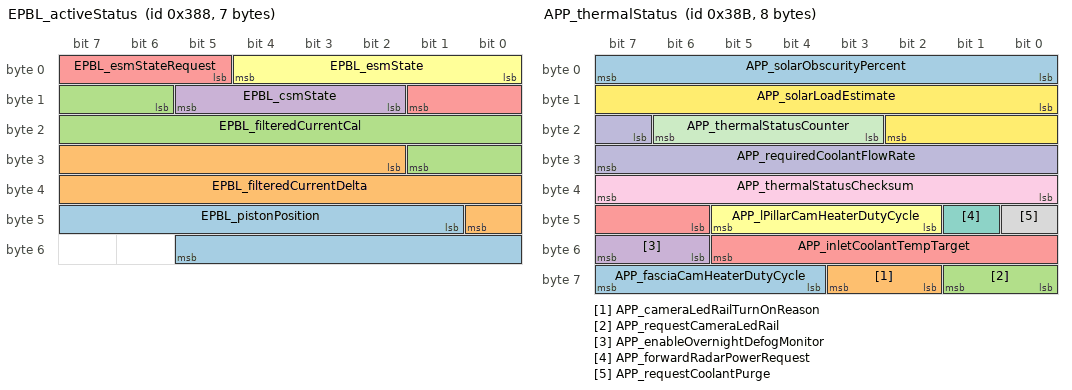
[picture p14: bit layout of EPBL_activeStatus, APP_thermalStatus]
BO_ 904 EPBL_activeStatus: 7 Vector__XXX
 SG_ EPBL_pistonPosition : 41|13@1- (9.768009768009769,0) [0|0] "" Vector__XXX
 SG_ EPBL_filteredCurrentDelta : 26|15@1- (0.01,0) [0|0] "" Vector__XXX
 SG_ EPBL_filteredCurrentCal : 14|12@1+ (0.01,0) [0|0] "" Vector__XXX
 SG_ EPBL_csmState : 10|4@1+ (1,0) [0|0] "" Vector__XXX
 SG_ EPBL_esmStateRequest : 5|5@1+ (1,0) [0|0] "" Vector__XXX
 SG_ EPBL_esmState : 0|5@1+ (1,0) [0|0] "" Vector__XXX

BO_ 906 VCSEC_NFCCurrentCardUID: 8 Vector__XXX
 SG_ VCSEC_BPillarNFCCardUIDL m0 : 8|56@1+ (1,0) [0|0] "" Vector__XXX
 SG_ VCSEC_BPillarNFCCardUIDR m1 : 8|56@1+ (1,0) [0|0] "" Vector__XXX
 SG_ VCSEC_CenterNFCCardUID m3 : 8|56@1+ (1,0) [0|0] "" Vector__XXX
 SG_ VCSEC_NFCReaderIndexUID M : 0|2@1+ (1,0) [0|0] "" Vector__XXX

BO_ 907 APP_thermalStatus: 8 Vector__XXX
 SG_ APP_fasciaCamHeaterDutyCycle : 60|4@1+ (0.06666666666666667,0) [0|0] "" Vector__XXX
 SG_ APP_cameraLedRailTurnOnReason : 58|2@1+ (1,0) [0|0] "" Vector__XXX
 SG_ APP_requestCameraLedRail : 56|2@1+ (1,0) [0|0] "" Vector__XXX
 SG_ APP_enableOvernightDefogMonitor : 54|2@1+ (1,0) [0|0] "" Vector__XXX
 SG_ APP_inletCoolantTempTarget : 46|8@1+ (0.5,0) [0|0] "" Vector__XXX
 SG_ APP_lPillarCamHeaterDutyCycle : 42|4@1+ (0.06666666666666667,0) [0|0] "" Vector__XXX
 SG_ APP_forwardRadarPowerRequest : 41|1@1+ (1,0) [0|0] "" Vector__XXX
 SG_ APP_requestCoolantPurge : 40|1@1+ (1,0) [0|0] "" Vector__XXX
 SG_ APP_thermalStatusChecksum : 32|8@1+ (1,0) [0|0] "" Vector__XXX
 SG_ APP_requiredCoolantFlowRate : 23|9@1+ (0.1,0) [0|0] "" Vector__XXX
 SG_ APP_thermalStatusCounter : 19|4@1+ (1,0) [0|0] "" Vector__XXX
 SG_ APP_solarLoadEstimate : 8|11@1+ (1,0) [0|0] "" Vector__XXX
 SG_ APP_solarObscurityPercent : 0|8@1+ (0.5,-25) [0|0] "" Vector__XXX

BO_ 909 APP_VC_infoMessage: 8 Vector__XXX
 SG_ APP_frontCamOcclusionType : 58|3@1+ (1,0) [0|0] "" Vector__XXX
 SG_ APP_narrowOverallVisibility : 55|3@1+ (1,0) [0|0] "" Vector__XXX
 SG_ APP_narrowInPathVisibility : 52|3@1+ (1,0) [0|0] "" Vector__XXX
 SG_ APP_mainOverallVisibility : 49|3@1+ (1,0) [0|0] "" Vector__XXX
 SG_ APP_mainInPathVisibility : 46|3@1+ (1,0) [0|0] "" Vector__XXX
 SG_ APP_fisheyeOverallVisibility : 43|3@1+ (1,0) [0|0] "" Vector__XXX
 SG_ APP_fisheyeInPathVisibility : 40|3@1+ (1,0) [0|0] "" Vector__XXX
 SG_ APP_sceneTagWetRoad : 38|2@1+ (1,0) [0|0] "" Vector__XXX
 SG_ APP_sceneTagTunnel : 36|2@1+ (1,0) [0|0] "" Vector__XXX
 SG_ APP_sceneTagSunGlare : 34|2@1+ (1,0) [0|0] "" Vector__XXX
 SG_ APP_sceneTagSnowyRoad : 32|2@1+ (1,0) [0|0] "" Vector__XXX
 SG_ APP_sceneTagSnowing : 30|2@1+ (1,0) [0|0] "" Vector__XXX
 SG_ APP_sceneTagSevereWeather : 28|2@1+ (1,0) [0|0] "" Vector__XXX
 SG_ APP_sceneTagRaining : 26|2@1+ (1,0) [0|0] "" Vector__XXX
 SG_ APP_sceneTagLensFlare : 24|2@1+ (1,0) [0|0] "" Vector__XXX
 SG_ APP_sceneTagIndoors : 22|2@1+ (1,0) [0|0] "" Vector__XXX
 SG_ APP_sceneTagFullyBlocked : 20|2@1+ (1,0) [0|0] "" Vector__XXX
 SG_ APP_sceneTagFog : 18|2@1+ (1,0) [0|0] "" Vector__XXX
 SG_ APP_sceneTagClearlyRaining : 16|2@1+ (1,0) [0|0] "" Vector__XXX
 SG_ APP_selfieCameraLUX : 8|8@1+ (1,0) [0|0] "" Vector__XXX
 SG_ APP_selfieCameraBlocked : 6|2@1+ (1,0) [0|0] "" Vector__XXX
 SG_ APP_windshieldHeaterOnReason : 2|4@1+ (1,0) [0|0] "" Vector__XXX
 SG_ APP_inTunnel : 0|2@1+ (1,0) [0|0] "" Vector__XXX

BO_ 912 UI_gridFormControl: 2 Vector__XXX
 SG_ UI_powershareRequest : 10|2@1+ (1,0) [0|0] "" Vector__XXX
 SG_ UI_v2lFeatureRequest : 9|1@1+ (1,0) [0|0] "" Vector__XXX
 SG_ UI_dischargeTerminationPct : 0|8@1+ (1,0) [0|0] "" Vector__XXX

BO_ 914 BMS_packConfig: 8 Vector__XXX
 SG_ BMS_beginningOfLifePackEnergy m1 : 40|10@1+ (0.1,0) [0|0] "" Vector__XXX
 SG_ BMS_standbySupplyContinuousPowerLimit m1 : 36|2@1+ (1,0) [0|0] "" Vector__XXX
 SG_ BMS_platformMaxBusVoltage m1 : 24|10@1+ (1,300) [0|0] "" Vector__XXX
 SG_ BMS_packMass m1 : 16|8@1+ (1,300) [0|0] "" Vector__XXX
 SG_ BMS_thermalPackType m1 : 11|4@1+ (1,0) [0|0] "" Vector__XXX
 SG_ BMS_moduleType m1 : 8|3@1+ (1,0) [0|0] "" Vector__XXX
 SG_ BMS_reservedConfig_0 m0 : 8|6@1+ (1,0) [0|0] "" Vector__XXX
 SG_ BMS_packConfigMultiplexer M : 0|8@1+ (1,0) [0|0] "" Vector__XXX

BO_ 915 VCRIGHT_epbmDebug: 8 Vector__XXX
 SG_ VCRIGHT_epbmAutonomyBehavior m0 : 62|2@1+ (1,0) [0|0] "" Vector__XXX
 SG_ VCRIGHT_epbmSystemStatus m0 : 58|4@1+ (1,0) [0|0] "" Vector__XXX
 SG_ VCRIGHT_epbFaultStatus m0 : 56|2@1+ (1,0) [0|0] "" Vector__XXX
 SG_ VCRIGHT_epbmFaultStatus m0 : 54|2@1+ (1,0) [0|0] "" Vector__XXX
 SG_ VCRIGHT_epbUnitStatus m0 : 49|5@1+ (1,0) [0|0] "" Vector__XXX
 SG_ VCRIGHT_epbmSummonState m0 : 46|3@1+ (1,0) [0|0] "" Vector__XXX
 SG_ VCRIGHT_epbSummonState m0 : 43|3@1+ (1,0) [0|0] "" Vector__XXX
 SG_ VCRIGHT_summonFaultReason m0 : 38|5@1+ (1,0) [0|0] "" Vector__XXX
 SG_ VCRIGHT_epbmReleaseVoltage m0 : 27|11@1+ (0.01,0) [0|0] "" Vector__XXX
 SG_ VCRIGHT_activeDecelAllowedLatch m1 : 23|1@1+ (1,0) [0|0] "" Vector__XXX
 SG_ VCRIGHT_summonUnavailableAllowed m1 : 22|1@1+ (1,0) [0|0] "" Vector__XXX
 SG_ VCRIGHT_summonFaultAllowed m1 : 21|1@1+ (1,0) [0|0] "" Vector__XXX
 SG_ VCRIGHT_summonCompleteAllowed m1 : 20|1@1+ (1,0) [0|0] "" Vector__XXX
 SG_ VCRIGHT_summonActiveAllowed m1 : 19|1@1+ (1,0) [0|0] "" Vector__XXX
 SG_ VCRIGHT_summonArmedAllowed m1 : 18|1@1+ (1,0) [0|0] "" Vector__XXX
 SG_ VCRIGHT_summonIdleAllowed m1 : 17|1@1+ (1,0) [0|0] "" Vector__XXX
 SG_ VCRIGHT_epbmApplyVoltage m0 : 16|11@1+ (0.01,0) [0|0] "" Vector__XXX
 SG_ VCRIGHT_epbmUnknownAllowed m1 : 16|1@1+ (1,0) [0|0] "" Vector__XXX
 SG_ VCRIGHT_summonInitAllowed m1 : 15|1@1+ (1,0) [0|0] "" Vector__XXX
 SG_ VCRIGHT_epbmSummonReleaseAllowed m1 : 14|1@1+ (1,0) [0|0] "" Vector__XXX
 SG_ VCRIGHT_epbmSummonParkAllowed m1 : 13|1@1+ (1,0) [0|0] "" Vector__XXX
 SG_ VCRIGHT_epbmSummonAllowed m1 : 12|1@1+ (1,0) [0|0] "" Vector__XXX
 SG_ VCRIGHT_epbmFaultAllowed m1 : 11|1@1+ (1,0) [0|0] "" Vector__XXX
 SG_ VCRIGHT_epbmReleasingAllowed m1 : 10|1@1+ (1,0) [0|0] "" Vector__XXX
 SG_ VCRIGHT_epbmDynApplyingAllowed m1 : 9|1@1+ (1,0) [0|0] "" Vector__XXX
 SG_ VCRIGHT_epbmParkingAllowed m1 : 8|1@1+ (1,0) [0|0] "" Vector__XXX
 SG_ VCRIGHT_epbmWinchReleaseAllowed m1 : 7|1@1+ (1,0) [0|0] "" Vector__XXX
 SG_ VCRIGHT_epbmWinchAllowed m1 : 6|1@1+ (1,0) [0|0] "" Vector__XXX
 SG_ VCRIGHT_epbMotorCurrent m0 : 5|11@1+ (0.01,0) [0|0] "" Vector__XXX
 SG_ VCRIGHT_epbmServiceAllowed m1 : 5|1@1+ (1,0) [0|0] "" Vector__XXX
 SG_ VCRIGHT_epbmMotorEnabled m0 : 4|1@1+ (1,0) [0|0] "" Vector__XXX
 SG_ VCRIGHT_epbmStartAllowed m1 : 4|1@1+ (1,0) [0|0] "" Vector__XXX
 SG_ VCRIGHT_epbmParkAllowed m1 : 3|1@1+ (1,0) [0|0] "" Vector__XXX
 SG_ VCRIGHT_epbmDynamicAllowed m1 : 2|1@1+ (1,0) [0|0] "" Vector__XXX
 SG_ VCRIGHT_epbmCaliperState m0 : 1|3@1+ (1,0) [0|0] "" Vector__XXX
 SG_ VCRIGHT_epbmOpenAllowed m1 : 1|1@1+ (1,0) [0|0] "" Vector__XXX
 SG_ VCRIGHT_epbmDebugIndex M : 0|1@1+ (1,0) [0|0] "" Vector__XXX

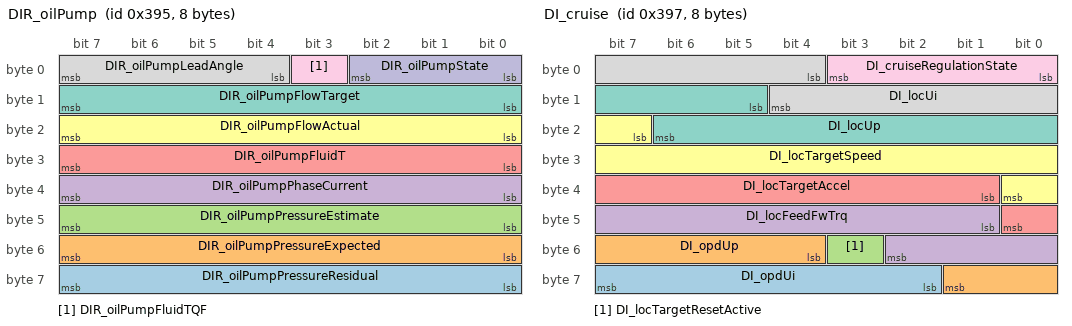
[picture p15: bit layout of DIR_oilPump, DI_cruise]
BO_ 917 DIR_oilPump: 8 Vector__XXX
 SG_ DIR_oilPumpPressureResidual : 56|8@1+ (4,-500) [0|0] "" Vector__XXX
 SG_ DIR_oilPumpPressureExpected : 48|8@1+ (2,0) [0|0] "" Vector__XXX
 SG_ DIR_oilPumpPressureEstimate : 40|8@1+ (2,0) [0|0] "" Vector__XXX
 SG_ DIR_oilPumpPhaseCurrent : 32|8@1+ (0.1,0) [0|0] "" Vector__XXX
 SG_ DIR_oilPumpFluidT : 24|8@1+ (1,-40) [0|0] "" Vector__XXX
 SG_ DIR_oilPumpFlowActual : 16|8@1+ (0.1,0) [0|0] "" Vector__XXX
 SG_ DIR_oilPumpFlowTarget : 8|8@1+ (0.1,0) [0|0] "" Vector__XXX
 SG_ DIR_oilPumpLeadAngle : 4|4@1+ (1.875,0) [0|0] "" Vector__XXX
 SG_ DIR_oilPumpFluidTQF : 3|1@1+ (1,0) [0|0] "" Vector__XXX
 SG_ DIR_oilPumpState : 0|3@1+ (1,0) [0|0] "" Vector__XXX

BO_ 919 DI_cruise: 8 Vector__XXX
 SG_ DI_opdUi : 58|6@1- (40,0) [0|0] "" Vector__XXX
 SG_ DI_opdUp : 52|6@1- (40,0) [0|0] "" Vector__XXX
 SG_ DI_locTargetResetActive : 51|1@1+ (1,0) [0|0] "" Vector__XXX
 SG_ DI_locFeedFwTrq : 41|10@1- (19.569471624266146,0) [0|0] "" Vector__XXX
 SG_ DI_locTargetAccel : 33|8@1- (0.1094488188976378,-1.5322834645669292) [0|0] "" Vector__XXX
 SG_ DI_locTargetSpeed : 23|10@1- (0.25,20) [0|0] "" Vector__XXX
 SG_ DI_locUp : 13|10@1- (19.569471624266146,0) [0|0] "" Vector__XXX
 SG_ DI_locUi : 4|9@1- (19.607843137254903,0) [0|0] "" Vector__XXX
 SG_ DI_cruiseRegulationState : 0|4@1+ (1,0) [0|0] "" Vector__XXX

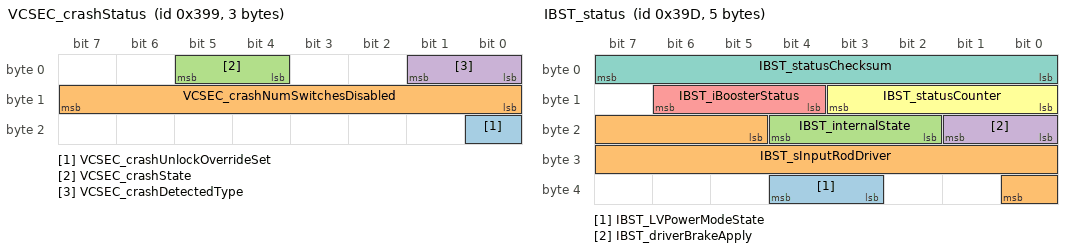
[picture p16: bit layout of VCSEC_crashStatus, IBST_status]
BO_ 921 VCSEC_crashStatus: 3 Vector__XXX
 SG_ VCSEC_crashUnlockOverrideSet : 16|1@1+ (1,0) [0|0] "" Vector__XXX
 SG_ VCSEC_crashNumSwitchesDisabled : 8|8@1+ (1,0) [0|0] "" Vector__XXX
 SG_ VCSEC_crashState : 4|2@1+ (1,0) [0|0] "" Vector__XXX
 SG_ VCSEC_crashDetectedType : 0|2@1+ (1,0) [0|0] "" Vector__XXX

BO_ 922 VCSEC_RSSI: 8 Vector__XXX
 SG_ VCSEC_RSSI2ConnectionType m1 : 61|2@1+ (1,0) [0|0] "" Vector__XXX
 SG_ VCSEC_BLEDevicePresence0 m0 : 59|5@1+ (1,0) [0|0] "" Vector__XXX
 SG_ VCSEC_RSSI1ConnectionType m1 : 59|2@1+ (1,0) [0|0] "" Vector__XXX
 SG_ VCSEC_UnknownBLEDevicePresent m0 : 58|1@1+ (1,0) [0|0] "" Vector__XXX
 SG_ VCSEC_RSSI0ConnectionType m1 : 57|2@1+ (1,0) [0|0] "" Vector__XXX
 SG_ VCSEC_BLEDevicePresence3 m1 : 52|5@1+ (1,0) [0|0] "" Vector__XXX
 SG_ VCSEC_rearBLEAntennaRSSI1 m0 : 50|8@1- (1,0) [0|0] "" Vector__XXX
 SG_ VCSEC_BLEDevicePresence2 m1 : 47|5@1+ (1,0) [0|0] "" Vector__XXX
 SG_ VCSEC_BLEDevicePresence1 m1 : 42|5@1+ (1,0) [0|0] "" Vector__XXX
 SG_ VCSEC_rightBLEAntennaRSSI1 m0 : 42|8@1- (1,0) [0|0] "" Vector__XXX
 SG_ VCSEC_centerBLEAntennaRSSI2 m1 : 34|8@1- (1,0) [0|0] "" Vector__XXX
 SG_ VCSEC_leftBLEAntennaRSSI1 m0 : 34|8@1- (1,0) [0|0] "" Vector__XXX
 SG_ VCSEC_centerBLEAntennaRSSI0 m0 : 26|8@1- (1,0) [0|0] "" Vector__XXX
 SG_ VCSEC_rearBLEAntennaRSSI2 m1 : 26|8@1- (1,0) [0|0] "" Vector__XXX
 SG_ VCSEC_rearBLEAntennaRSSI0 m0 : 18|8@1- (1,0) [0|0] "" Vector__XXX
 SG_ VCSEC_rightBLEAntennaRSSI2 m1 : 18|8@1- (1,0) [0|0] "" Vector__XXX
 SG_ VCSEC_leftBLEAntennaRSSI2 m1 : 10|8@1- (1,0) [0|0] "" Vector__XXX
 SG_ VCSEC_rightBLEAntennaRSSI0 m0 : 10|8@1- (1,0) [0|0] "" Vector__XXX
 SG_ VCSEC_centerBLEAntennaRSSI1 m1 : 2|8@1- (1,0) [0|0] "" Vector__XXX
 SG_ VCSEC_leftBLEAntennaRSSI0 m0 : 2|8@1- (1,0) [0|0] "" Vector__XXX
 SG_ VCSEC_RSSIIndex M : 0|2@1+ (1,0) [0|0] "" Vector__XXX

BO_ 923 DAS_status: 8 Vector__XXX
 SG_ DAS_statusChecksum : 56|8@1+ (1,0) [0|0] "" Vector__XXX
 SG_ DAS_statusCounter : 52|4@1+ (1,0) [0|0] "" Vector__XXX
 SG_ DAS_summonAvailable : 51|1@1+ (1,0) [0|0] "" Vector__XXX
 SG_ DAS_autoLaneChangeState : 46|5@1+ (1,0) [0|0] "" Vector__XXX
 SG_ DAS_autopilotHandsOnState : 42|4@1+ (1,0) [0|0] "" Vector__XXX
 SG_ DAS_fleetSpeedState : 40|2@1+ (1,0) [0|0] "" Vector__XXX
 SG_ DAS_laneDepartureWarning : 37|3@1+ (1,0) [0|0] "" Vector__XXX
 SG_ DAS_sideCollisionInhibit : 36|1@1+ (1,0) [0|0] "" Vector__XXX
 SG_ DAS_sideCollisionWarning : 34|2@1+ (1,0) [0|0] "" Vector__XXX
 SG_ DAS_sideCollisionAvoid : 32|2@1+ (1,0) [0|0] "" Vector__XXX
 SG_ DAS_lssState : 29|3@1+ (1,0) [0|0] "" Vector__XXX
 SG_ DAS_summonRvsLeashReached : 28|1@1+ (1,0) [0|0] "" Vector__XXX
 SG_ DAS_summonFwdLeashReached : 27|1@1+ (1,0) [0|0] "" Vector__XXX
 SG_ DAS_autoparkActive : 26|1@1+ (1,0) [0|0] "" Vector__XXX
 SG_ DAS_autoParked : 25|1@1+ (1,0) [0|0] "" Vector__XXX
 SG_ DAS_autoparkReady : 24|1@1+ (1,0) [0|0] "" Vector__XXX
 SG_ DAS_forwardCollisionWarning : 22|2@1+ (1,0) [0|0] "" Vector__XXX
 SG_ DAS_heaterState : 21|1@1+ (1,0) [0|0] "" Vector__XXX
 SG_ DAS_visionOnlySpeedLimit : 16|5@1+ (5,0) [0|0] "" Vector__XXX
 SG_ DAS_summonClearedGate : 15|1@1+ (1,0) [0|0] "" Vector__XXX
 SG_ DAS_summonObstacle : 14|1@1+ (1,0) [0|0] "" Vector__XXX
 SG_ DAS_suppressSpeedWarning : 13|1@1+ (1,0) [0|0] "" Vector__XXX
 SG_ DAS_fusedSpeedLimit : 8|5@1+ (5,0) [0|0] "" Vector__XXX
 SG_ DAS_blindSpotRearRight : 6|2@1+ (1,0) [0|0] "" Vector__XXX
 SG_ DAS_blindSpotRearLeft : 4|2@1+ (1,0) [0|0] "" Vector__XXX
 SG_ DAS_autopilotState : 0|4@1+ (1,0) [0|0] "" Vector__XXX

BO_ 925 IBST_status: 5 Vector__XXX
 SG_ IBST_LVPowerModeState : 35|2@1+ (1,0) [0|0] "" Vector__XXX
 SG_ IBST_sInputRodDriver : 21|12@1+ (0.015625,-5) [0|0] "" Vector__XXX
 SG_ IBST_internalState : 18|3@1+ (1,0) [0|0] "" Vector__XXX
 SG_ IBST_driverBrakeApply : 16|2@1+ (1,0) [0|0] "" Vector__XXX
 SG_ IBST_iBoosterStatus : 12|3@1+ (1,0) [0|0] "" Vector__XXX
 SG_ IBST_statusCounter : 8|4@1+ (1,0) [0|0] "" Vector__XXX
 SG_ IBST_statusChecksum : 0|8@1+ (1,0) [0|0] "" Vector__XXX

BO_ 929 VCFRONT_vehicleStatus: 8 Vector__XXX
 SG_ VCFRONT_vehicleStatusChecksum : 56|8@1+ (1,0) [0|0] "" Vector__XXX
 SG_ VCFRONT_vehicleStatusCounter : 52|4@1+ (1,0) [0|0] "" Vector__XXX
 SG_ VCFRONT_pcsEFuseVoltage m0 : 42|10@1+ (0.1,0) [0|0] "" Vector__XXX
 SG_ VCFRONT_hpBattHeatingPowerTrgt m1 : 41|7@1+ (100,0) [0|0] "" Vector__XXX
 SG_ VCFRONT_2RowRightUnbuckled m0 : 40|2@1+ (1,0) [0|0] "" Vector__XXX
 SG_ VCFRONT_anySWEFuseActive m1 : 40|1@1+ (1,0) [0|0] "" Vector__XXX
 SG_ VCFRONT_driverEnteredCabinEstimateDBG m1 : 39|1@1+ (1,0) [0|0] "" Vector__XXX
 SG_ VCFRONT_2RowCenterUnbuckled m0 : 38|2@1+ (1,0) [0|0] "" Vector__XXX
 SG_ VCFRONT_refSystemNominal m1 : 38|1@1+ (1,0) [0|0] "" Vector__XXX
 SG_ VCFRONT_2RowLeftUnbuckled m0 : 36|2@1+ (1,0) [0|0] "" Vector__XXX
 SG_ VCFRONT_passengerUnbuckled m0 : 34|2@1+ (1,0) [0|0] "" Vector__XXX
 SG_ VCFRONT_driverUnbuckled m0 : 32|2@1+ (1,0) [0|0] "" Vector__XXX
 SG_ VCFRONT_driverDoorStatus m0 : 31|1@1+ (1,0) [0|0] "" Vector__XXX
 SG_ VCFRONT_driverBuckleStatus m0 : 30|1@1+ (1,0) [0|0] "" Vector__XXX
 SG_ VCFRONT_ota12VSupportRequest m0 : 29|1@1+ (1,0) [0|0] "" Vector__XXX
 SG_ VCFRONT_factoryLimitsOverrideOk m0 : 27|1@1+ (1,0) [0|0] "" Vector__XXX
 SG_ VCFRONT_PCSCurrent m1 : 25|13@1- (0.1,0) [0|0] "" Vector__XXX
 SG_ VC_userPresenceState m0 : 24|2@1+ (1,0) [0|0] "" Vector__XXX
 SG_ VCFRONT_dcr12VMilliOhms m0 : 16|8@1+ (1,0) [0|0] "" Vector__XXX
 SG_ VCFRONT_hvacReqBattCoolOutTemp m1 : 16|9@1+ (0.1,40) [0|0] "" Vector__XXX
 SG_ VCFRONT_12vStatusForDrive m0 : 14|2@1+ (1,0) [0|0] "" Vector__XXX
 SG_ VCFRONT_diPowerOnState m0 : 10|3@1+ (1,0) [0|0] "" Vector__XXX
 SG_ VCFRONT_accPlusAvailable m0 : 9|1@1+ (1,0) [0|0] "" Vector__XXX
 SG_ VCFRONT_passengerPresent m0 : 8|1@1+ (1,0) [0|0] "" Vector__XXX
 SG_ VCFRONT_driverPresent m0 : 7|1@1+ (1,0) [0|0] "" Vector__XXX
 SG_ VCFRONT_maxBattHeatRejection m1 : 6|10@1+ (30,0) [0|0] "" Vector__XXX
 SG_ VCFRONT_standbySupplySupported m0 : 6|1@1+ (1,0) [0|0] "" Vector__XXX
 SG_ VCFRONT_thermalSystemType m0 : 5|1@1+ (1,0) [0|0] "" Vector__XXX
 SG_ VCFRONT_3RowRightUnbuckled m1 : 4|2@1+ (1,0) [0|0] "" Vector__XXX
 SG_ VCFRONT_3RowLeftUnbuckled m1 : 2|2@1+ (1,0) [0|0] "" Vector__XXX
 SG_ VCFRONT_APGlassHeaterState m0 : 2|3@1+ (1,0) [0|0] "" Vector__XXX
 SG_ VCFRONT_bmsHvChargeEnable m1 : 1|1@1+ (1,0) [0|0] "" Vector__XXX
 SG_ VCFRONT_preconditionRequest m0 : 1|1@1+ (1,0) [0|0] "" Vector__XXX
 SG_ VCFRONT_vehicleStatusMuxIndex M : 0|1@1+ (1,0) [0|0] "" Vector__XXX

BO_ 930 VCLEFT_status: 8 Vector__XXX
 SG_ VCLEFT_obdEthernetActive m0 : 63|1@1+ (1,0) [0|0] "" Vector__XXX
 SG_ VCLEFT_swcHeatInhibited m1 : 57|1@1+ (1,0) [0|0] "" Vector__XXX
 SG_ VCLEFT_swcPCBATemperature m0 : 55|8@1- (1,68) [0|0] "" Vector__XXX
 SG_ VCLEFT_swcHeatStatus m1 : 54|3@1+ (1,0) [0|0] "" Vector__XXX
 SG_ VCLEFT_swcInputVoltage m0 : 47|8@1+ (0.1,0) [0|0] "" Vector__XXX
 SG_ VCLEFT_autonomyBehaviorStatus m2 : 46|2@1+ (1,0) [0|0] "" Vector__XXX
 SG_ VCLEFT_swcHeatTmp m1 : 44|10@1+ (0.1,-35) [0|0] "" Vector__XXX
 SG_ VCLEFT_SWCpresent m2 : 37|1@1+ (1,0) [0|0] "" Vector__XXX
 SG_ VCLEFT_footwellLightCurrent m0 : 35|12@1- (0.1,0) [0|0] "" Vector__XXX
 SG_ VCLEFT_trailerAuxCurrent m1 : 32|12@1+ (0.025,0) [0|0] "" Vector__XXX
 SG_ VCLEFT_DIeFuseCurrent m2 : 31|6@1+ (0.1,0) [0|0] "" Vector__XXX
 SG_ VCLEFT_eFuseMgmtVoltageMonitor m1 : 25|7@1+ (0.125,0) [0|0] "" Vector__XXX
 SG_ VCLEFT_DIeFuseFault m1 : 24|1@1+ (1,0) [0|0] "" Vector__XXX
 SG_ VCLEFT_swcHeatDutyCycle m2 : 24|7@1+ (1,0) [0|0] "" Vector__XXX
 SG_ VCLEFT_vbatProt m0 : 23|12@1+ (0.005443676098,0) [0|0] "" Vector__XXX
 SG_ VCLEFT_LVBatteryTypeDBG m1 : 20|3@1+ (1,0) [0|0] "" Vector__XXX
 SG_ VCLEFT_swcHeatPwr m2 : 15|9@1+ (0.5,0) [0|0] "" Vector__XXX
 SG_ VCLEFT_5AVoltage m0 : 13|10@1+ (0.005443676098,0) [0|0] "" Vector__XXX
 SG_ VCLEFT_OTAState m0 : 12|1@1+ (1,0) [0|0] "" Vector__XXX
 SG_ VCLEFT_rationalityAggregateCurrent m1 : 12|8@1+ (0.5,0) [0|0] "" Vector__XXX
 SG_ VCLEFT_consoleDoorAssist m0 : 11|1@1+ (1,0) [0|0] "" Vector__XXX
 SG_ VCLEFT_securityControllerVoltage m0 : 6|5@1+ (0.625,0) [0|0] "" Vector__XXX
 SG_ VCLEFT_securityControllerEnable m0 : 5|1@1+ (1,0) [0|0] "" Vector__XXX
 SG_ VCLEFT_pcbaTemperature m2 : 4|11@1+ (0.125,-40) [0|0] "" Vector__XXX
 SG_ VCLEFT_statusIndex M : 0|2@1+ (1,0) [0|0] "" Vector__XXX

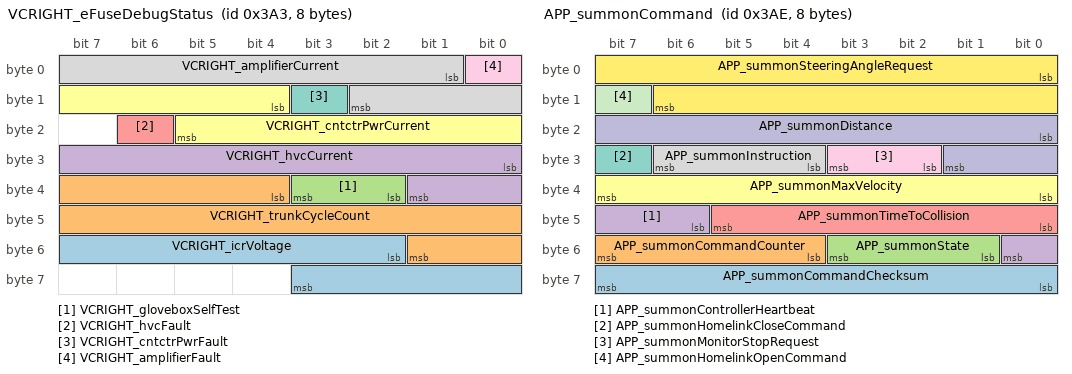
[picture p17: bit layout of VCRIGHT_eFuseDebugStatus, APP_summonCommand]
BO_ 931 VCRIGHT_eFuseDebugStatus: 8 Vector__XXX
 SG_ VCRIGHT_icrVoltage : 50|10@1+ (0.02,0) [0|0] "" Vector__XXX
 SG_ VCRIGHT_trunkCycleCount : 36|14@1+ (10,0) [0|0] "" Vector__XXX
 SG_ VCRIGHT_gloveboxSelfTest : 34|2@1+ (1,0) [0|0] "" Vector__XXX
 SG_ VCRIGHT_hvcCurrent : 24|10@1+ (0.1,0) [0|0] "" Vector__XXX
 SG_ VCRIGHT_hvcFault : 22|1@1+ (1,0) [0|0] "" Vector__XXX
 SG_ VCRIGHT_cntctrPwrCurrent : 12|10@1+ (0.1,0) [0|0] "" Vector__XXX
 SG_ VCRIGHT_cntctrPwrFault : 11|1@1+ (1,0) [0|0] "" Vector__XXX
 SG_ VCRIGHT_amplifierCurrent : 1|10@1+ (0.1,0) [0|0] "" Vector__XXX
 SG_ VCRIGHT_amplifierFault : 0|1@1+ (1,0) [0|0] "" Vector__XXX

BO_ 935 DIR_alertMatrix1: 8 Vector__XXX
 SG_ DIR_a064_torqueIntervention : 63|1@1+ (1,0) [0|0] "" Vector__XXX
 SG_ DIR_a062_systemLimpMode : 61|1@1+ (1,0) [0|0] "" Vector__XXX
 SG_ DIR_a061_heatsinkSensor : 60|1@1+ (1,0) [0|0] "" Vector__XXX
 SG_ DIR_a060_heatsinkUT : 59|1@1+ (1,0) [0|0] "" Vector__XXX
 SG_ DIR_a059_heatsinkOT : 58|1@1+ (1,0) [0|0] "" Vector__XXX
 SG_ DIR_a058_ambientSensor : 57|1@1+ (1,0) [0|0] "" Vector__XXX
 SG_ DIR_a057_ambientUT : 56|1@1+ (1,0) [0|0] "" Vector__XXX
 SG_ DIR_a056_ambientOT : 55|1@1+ (1,0) [0|0] "" Vector__XXX
 SG_ DIR_a055_trqCrossCheck : 54|1@1+ (1,0) [0|0] "" Vector__XXX
 SG_ DIR_a054_driveInverterOT : 53|1@1+ (1,0) [0|0] "" Vector__XXX
 SG_ DIR_a053_unexpectedLatchState : 52|1@1+ (1,0) [0|0] "" Vector__XXX
 SG_ DIR_a052_dirMIA : 51|1@1+ (1,0) [0|0] "" Vector__XXX
 SG_ DIR_a050_noStatorSensor : 49|1@1+ (1,0) [0|0] "" Vector__XXX
 SG_ DIR_a049_statorSensorDiff : 48|1@1+ (1,0) [0|0] "" Vector__XXX
 SG_ DIR_a048_statorSensor2 : 47|1@1+ (1,0) [0|0] "" Vector__XXX
 SG_ DIR_a047_statorSensor1 : 46|1@1+ (1,0) [0|0] "" Vector__XXX
 SG_ DIR_a046_statorOT : 45|1@1+ (1,0) [0|0] "" Vector__XXX
 SG_ DIR_a045_outletSensor : 44|1@1+ (1,0) [0|0] "" Vector__XXX
 SG_ DIR_a044_outletUT : 43|1@1+ (1,0) [0|0] "" Vector__XXX
 SG_ DIR_a043_outletOT : 42|1@1+ (1,0) [0|0] "" Vector__XXX
 SG_ DIR_a042_inletSensor : 41|1@1+ (1,0) [0|0] "" Vector__XXX
 SG_ DIR_a041_sdcMIA : 40|1@1+ (1,0) [0|0] "" Vector__XXX
 SG_ DIR_a040_difMIA : 39|1@1+ (1,0) [0|0] "" Vector__XXX
 SG_ DIR_a038_busVsensor : 37|1@1+ (1,0) [0|0] "" Vector__XXX
 SG_ DIR_a037_busUV : 36|1@1+ (1,0) [0|0] "" Vector__XXX
 SG_ DIR_a036_busOV : 35|1@1+ (1,0) [0|0] "" Vector__XXX
 SG_ DIR_a035_phaseCurrentBalance : 34|1@1+ (1,0) [0|0] "" Vector__XXX
 SG_ DIR_a034_phaseBcurrentSensor : 33|1@1+ (1,0) [0|0] "" Vector__XXX
 SG_ DIR_a033_phaseAcurrentSensor : 32|1@1+ (1,0) [0|0] "" Vector__XXX
 SG_ DIR_a032_phaseBcurrentOffset : 31|1@1+ (1,0) [0|0] "" Vector__XXX
 SG_ DIR_a031_phaseAcurrentOffset : 30|1@1+ (1,0) [0|0] "" Vector__XXX
 SG_ DIR_a030_phaseCrms : 29|1@1+ (1,0) [0|0] "" Vector__XXX
 SG_ DIR_a029_phaseBrms : 28|1@1+ (1,0) [0|0] "" Vector__XXX
 SG_ DIR_a028_phaseArms : 27|1@1+ (1,0) [0|0] "" Vector__XXX
 SG_ DIR_a027_phaseCpeak : 26|1@1+ (1,0) [0|0] "" Vector__XXX
 SG_ DIR_a026_phaseBpeak : 25|1@1+ (1,0) [0|0] "" Vector__XXX
 SG_ DIR_a025_phaseApeak : 24|1@1+ (1,0) [0|0] "" Vector__XXX
 SG_ DIR_a024_selfTest : 23|1@1+ (1,0) [0|0] "" Vector__XXX
 SG_ DIR_a022_hw5vSupplyUV : 21|1@1+ (1,0) [0|0] "" Vector__XXX
 SG_ DIR_a021_hwBusOV : 20|1@1+ (1,0) [0|0] "" Vector__XXX
 SG_ DIR_a020_hwMotorEncoder : 19|1@1+ (1,0) [0|0] "" Vector__XXX
 SG_ DIR_a018_hwLVSupplyUV : 17|1@1+ (1,0) [0|0] "" Vector__XXX
 SG_ DIR_a017_hwPedalMonitor : 16|1@1+ (1,0) [0|0] "" Vector__XXX
 SG_ DIR_a016_safeStateApplied : 15|1@1+ (1,0) [0|0] "" Vector__XXX
 SG_ DIR_a015_mechSafeStateAnomaly : 14|1@1+ (1,0) [0|0] "" Vector__XXX
 SG_ DIR_a014_activeDamping : 13|1@1+ (1,0) [0|0] "" Vector__XXX
 SG_ DIR_a013_eccError : 12|1@1+ (1,0) [0|0] "" Vector__XXX
 SG_ DIR_a011_swPowerStageNotReady : 10|1@1+ (1,0) [0|0] "" Vector__XXX
 SG_ DIR_a010_unintendedReset : 9|1@1+ (1,0) [0|0] "" Vector__XXX
 SG_ DIR_a009_hwEncoderB : 8|1@1+ (1,0) [0|0] "" Vector__XXX
 SG_ DIR_a008_hwEncoderA : 7|1@1+ (1,0) [0|0] "" Vector__XXX
 SG_ DIR_a007_statorAnomalyDetected : 6|1@1+ (1,0) [0|0] "" Vector__XXX
 SG_ DIR_a006_hwPhaseCpeak : 5|1@1+ (1,0) [0|0] "" Vector__XXX
 SG_ DIR_a005_hwPhaseBpeak : 4|1@1+ (1,0) [0|0] "" Vector__XXX
 SG_ DIR_a004_hwPhaseApeak : 3|1@1+ (1,0) [0|0] "" Vector__XXX
 SG_ DIR_a003_hwPhaseCgateDrive : 2|1@1+ (1,0) [0|0] "" Vector__XXX
 SG_ DIR_a002_hwPhaseBgateDrive : 1|1@1+ (1,0) [0|0] "" Vector__XXX
 SG_ DIR_a001_hwPhaseAgateDrive : 0|1@1+ (1,0) [0|0] "" Vector__XXX

BO_ 936 VCLEFT_logging1Hz: 8 Vector__XXX
 SG_ VCLEFT_tpmsCurrent m2 : 61|3@1+ (0.01,0) [0|0] "" Vector__XXX
 SG_ VCLEFT_sideMirrorHeaterCurrent m1 : 60|4@1+ (0.5,0) [0|0] "" Vector__XXX
 SG_ VCLEFT_ocsCurrent m2 : 58|3@1+ (0.01,0) [0|0] "" Vector__XXX
 SG_ VCLEFT_sideMirrorCurrent m1 : 56|4@1+ (0.2,0) [0|0] "" Vector__XXX
 SG_ VCLEFT_vbatFused3Current m2 : 53|5@1+ (0.1,0) [0|0] "" Vector__XXX
 SG_ VCLEFT_dirDischargeCurrent m1 : 52|4@1+ (0.1,0) [0|0] "" Vector__XXX
 SG_ VCLEFT_sccmCurrent m1 : 48|4@1+ (0.05,0) [0|0] "" Vector__XXX
 SG_ VCLEFT_vbatFused0Current m2 : 48|5@1+ (0.1,0) [0|0] "" Vector__XXX
 SG_ VCLEFT_accessoryFeed2Current m2 : 43|5@1+ (0.2,0) [0|0] "" Vector__XXX
 SG_ VCLEFT_frontSeatHeatBackrestPwr m0 : 40|7@1+ (1,0) [0|0] "" Vector__XXX
 SG_ VCLEFT_swcCurrent m1 : 40|8@1+ (0.05,0) [0|0] "" Vector__XXX
 SG_ VCLEFT_accessoryFeed1Current m2 : 37|6@1+ (0.1,0) [0|0] "" Vector__XXX
 SG_ VCLEFT_bleBPillarRearHdlrCurrent m1 : 36|4@1+ (0.05,0) [0|0] "" Vector__XXX
 SG_ VCLEFT_trunkFoldFlatSwLEDCurrent m2 : 34|3@1+ (5,0) [0|0] "" Vector__XXX
 SG_ VCLEFT_usbPortsRearCurrentAvg m4 : 34|10@1+ (0.001,0) [0|0] "" Vector__XXX
 SG_ VCLEFT_frontSeatHeatCushionPwr m0 : 32|7@1+ (1,0) [0|0] "" Vector__XXX
 SG_ VCLEFT_lumbarEcuCurrent m1 : 32|4@1+ (0.1,0) [0|0] "" Vector__XXX
 SG_ VCLEFT_rearPuddleLEDCurrent m2 : 31|3@1+ (2,0) [0|0] "" Vector__XXX
 SG_ VCLEFT_frontPuddleLEDCurrent m2 : 28|3@1+ (2,0) [0|0] "" Vector__XXX
 SG_ VCLEFT_mapPocketLEDsCurrent m2 : 25|3@1+ (10,0) [0|0] "" Vector__XXX
 SG_ VCLEFT_rcmCurrent m1 : 24|7@1+ (0.025,0) [0|0] "" Vector__XXX
 SG_ VCLEFT_rgbLedIPFROutput m3 : 24|1@1+ (1,0) [0|0] "" Vector__XXX
 SG_ VCLEFT_swcResistance m0 : 24|7@1+ (0.025,0) [0|0] "" Vector__XXX
 SG_ VCLEFT_usbPortsCurrentAvg m4 : 24|10@1+ (0.001,0) [0|0] "" Vector__XXX
 SG_ VCLEFT_rgbLedIPFLOutput m3 : 23|1@1+ (1,0) [0|0] "" Vector__XXX
 SG_ VCLEFT_intDoorHandleLEDCurrent m2 : 22|3@1+ (2,0) [0|0] "" Vector__XXX
 SG_ VCLEFT_windowSwitchLEDCurrent m2 : 19|3@1+ (10,0) [0|0] "" Vector__XXX
 SG_ VCLEFT_phoneChargingFR m0 : 17|1@1+ (1,0) [0|0] "" Vector__XXX
 SG_ VCLEFT_phoneChargingFL m0 : 16|1@1+ (1,0) [0|0] "" Vector__XXX
 SG_ VCLEFT_tlcCurrent m1 : 16|6@1+ (0.5,0) [0|0] "" Vector__XXX
 SG_ VCLEFT_trunkInteriorLEDCurrent m2 : 15|4@1+ (5,0) [0|0] "" Vector__XXX
 SG_ VCLEFT_12vSocketRearCurrentAvg m4 : 13|10@1+ (0.01,0) [0|0] "" Vector__XXX
 SG_ VCLEFT_rgbLedIPFRCurrent m3 : 13|10@1+ (0.0004887585532746823,0) [0|0] "" Vector__XXX
 SG_ VCLEFT_stopReverseTurnLightCurrent m2 : 11|4@1+ (0.1,0) [0|0] "" Vector__XXX
 SG_ VCLEFT_chargePortCurrent m1 : 8|6@1+ (0.05,0) [0|0] "" Vector__XXX
 SG_ VCLEFT_tohcPCBATemperature m0 : 8|8@1+ (1,-40) [0|0] "" Vector__XXX
 SG_ VCLEFT_turnTailStopLightCurrent m2 : 7|4@1+ (0.1,0) [0|0] "" Vector__XXX
 SG_ VCLEFT_12vSocketFrontCurrentAvg m4 : 3|10@1+ (0.01,0) [0|0] "" Vector__XXX
 SG_ VCLEFT_rgbLedIPFLCurrent m3 : 3|10@1+ (0.0004887585532746823,0) [0|0] "" Vector__XXX
 SG_ VCLEFT_tailLightCurrent m2 : 3|4@1+ (0.1,0) [0|0] "" Vector__XXX
 SG_ VCLEFT_logging1HzIndex M : 0|3@1+ (1,0) [0|0] "" Vector__XXX

BO_ 941 ICR_info: 8 Vector__XXX
 SG_ ICR_infoUsageId m11 : 48|16@1+ (1,0) [0|0] "" Vector__XXX
 SG_ ICR_infoAssemblyId m11 : 40|8@1+ (1,0) [0|0] "" Vector__XXX
 SG_ ICR_infoPcbaId m11 : 32|8@1+ (1,0) [0|0] "" Vector__XXX
 SG_ ICR_infoAppCrc m13 : 8|32@1+ (1,0) [0|0] "" Vector__XXX
 SG_ ICR_infoBoardPartNumber1520 m27 : 8|48@1+ (1,0) [0|0] "" Vector__XXX
 SG_ ICR_infoBoardPartNumber17 m25 : 8|56@1+ (1,0) [0|0] "" Vector__XXX
 SG_ ICR_infoBoardPartNumber814 m26 : 8|56@1+ (1,0) [0|0] "" Vector__XXX
 SG_ ICR_infoBuildType m10 : 8|3@1+ (1,0) [0|0] "" Vector__XXX
 SG_ ICR_infoIndex M : 0|8@1+ (1,0) [0|0] "" Vector__XXX

BO_ 942 APP_summonCommand: 8 Vector__XXX
 SG_ APP_summonCommandChecksum : 56|8@1+ (1,0) [0|0] "" Vector__XXX
 SG_ APP_summonCommandCounter : 52|4@1+ (1,0) [0|0] "" Vector__XXX
 SG_ APP_summonState : 49|3@1+ (1,0) [0|0] "" Vector__XXX
 SG_ APP_summonControllerHeartbeat : 46|3@1+ (1,0) [0|0] "" Vector__XXX
 SG_ APP_summonTimeToCollision : 40|6@1+ (0.1,0) [0|0] "" Vector__XXX
 SG_ APP_summonMaxVelocity : 32|8@1+ (0.05,0) [0|0] "" Vector__XXX
 SG_ APP_summonHomelinkCloseCommand : 31|1@1+ (1,0) [0|0] "" Vector__XXX
 SG_ APP_summonInstruction : 28|3@1+ (1,0) [0|0] "" Vector__XXX
 SG_ APP_summonMonitorStopRequest : 26|2@1+ (1,0) [0|0] "" Vector__XXX
 SG_ APP_summonDistance : 16|10@1+ (0.02,0) [0|0] "" Vector__XXX
 SG_ APP_summonHomelinkOpenCommand : 15|1@1+ (1,0) [0|0] "" Vector__XXX
 SG_ APP_summonSteeringAngleRequest : 0|15@1+ (0.1,-1638.35) [0|0] "" Vector__XXX

BO_ 947 UI_vehicleControl2: 8 Vector__XXX
 SG_ UI_sleepFeature2 : 63|1@1+ (1,0) [0|0] "" Vector__XXX
 SG_ UI_silentAlarm : 61|1@1+ (1,0) [0|0] "" Vector__XXX
 SG_ UI_saveTireConfigReq : 60|1@1+ (1,0) [0|0] "" Vector__XXX
 SG_ UI_tireSeason : 59|1@1+ (1,0) [0|0] "" Vector__XXX
 SG_ UI_wiperHeaterReq : 57|1@1+ (1,0) [0|0] "" Vector__XXX
 SG_ UI_frontLeftSeatAutoClimateReq : 56|1@1+ (1,0) [0|0] "" Vector__XXX
 SG_ UI_dcr12VThreshold : 52|4@1+ (1,0) [0|0] "" Vector__XXX
 SG_ UI_sleepFeature1 : 51|1@1+ (1,0) [0|0] "" Vector__XXX
 SG_ UI_frontRightSeatAutoClimateReq : 39|1@1+ (1,0) [0|0] "" Vector__XXX
 SG_ UI_disableHorn : 34|1@1+ (1,0) [0|0] "" Vector__XXX
 SG_ UI_steeringWheelHeatReq : 33|1@1+ (1,0) [0|0] "" Vector__XXX
 SG_ UI_WC3UpdateInhibit : 32|1@1+ (1,0) [0|0] "" Vector__XXX
 SG_ UI_conditionalLoggingEnabledVCSEC : 31|1@1+ (1,0) [0|0] "" Vector__XXX
 SG_ UI_virtualPitchSensorOverrideOKForAim : 30|1@1+ (1,0) [0|0] "" Vector__XXX
 SG_ UI_autoRollWindowsOnLockEnable : 29|1@1+ (1,0) [0|0] "" Vector__XXX
 SG_ UI_shorted12VCellTestMode : 27|2@1+ (1,0) [0|0] "" Vector__XXX
 SG_ UI_autopilotPowerStateRequest : 25|2@1+ (1,0) [0|0] "" Vector__XXX
 SG_ UI_coastDownMode : 24|1@1+ (1,0) [0|0] "" Vector__XXX
 SG_ UI_batteryPreconditioningRequest : 23|1@1+ (1,0) [0|0] "" Vector__XXX
 SG_ UI_keepAutopilotAwake : 22|1@1+ (1,0) [0|0] "" Vector__XXX
 SG_ UI_pairKeyQRCodeDisplaying : 21|1@1+ (1,0) [0|0] "" Vector__XXX
 SG_ UI_BLEPushNotificationRequest : 20|1@1+ (1,0) [0|0] "" Vector__XXX
 SG_ UI_freeRollModeRequest : 19|1@1+ (1,0) [0|0] "" Vector__XXX
 SG_ UI_displayOnForUser : 18|1@1+ (1,0) [0|0] "" Vector__XXX
 SG_ UI_summonState : 16|2@1+ (1,0) [0|0] "" Vector__XXX
 SG_ UI_VCLEFTFeature1 : 15|1@1+ (1,0) [0|0] "" Vector__XXX
 SG_ UI_VCSECFeature1 : 14|1@1+ (1,0) [0|0] "" Vector__XXX
 SG_ UI_alarmTriggerRequest : 13|1@1+ (1,0) [0|0] "" Vector__XXX
 SG_ UI_readyToAddKey : 12|1@1+ (1,0) [0|0] "" Vector__XXX
 SG_ UI_lightSwitch : 9|3@1+ (1,0) [0|0] "" Vector__XXX
 SG_ UI_disableMirrorAutoDim : 8|1@1+ (1,0) [0|0] "" Vector__XXX
 SG_ UI_PINToDrivePassed : 7|1@1+ (1,0) [0|0] "" Vector__XXX
 SG_ UI_PINToDriveEnabled : 6|1@1+ (1,0) [0|0] "" Vector__XXX
 SG_ UI_locksPanelActive : 5|1@1+ (1,0) [0|0] "" Vector__XXX
 SG_ UI_soundHornOnLock : 4|1@1+ (1,0) [0|0] "" Vector__XXX
 SG_ UI_WCUpdateInhibit : 3|1@1+ (1,0) [0|0] "" Vector__XXX
 SG_ UI_UMCUpdateInhibit : 2|1@1+ (1,0) [0|0] "" Vector__XXX
 SG_ UI_trunkRequest : 1|1@1+ (1,0) [0|0] "" Vector__XXX
 SG_ UI_gloveboxRequest : 0|1@1+ (1,0) [0|0] "" Vector__XXX

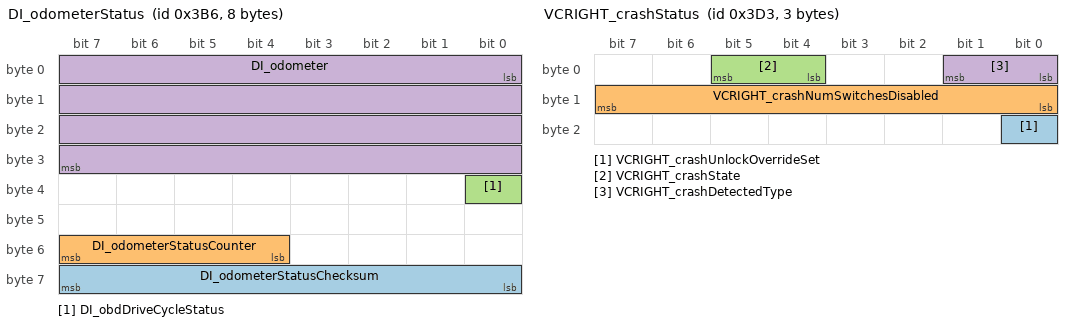
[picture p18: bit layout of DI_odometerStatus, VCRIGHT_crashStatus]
BO_ 950 DI_odometerStatus: 8 Vector__XXX
 SG_ DI_odometerStatusChecksum : 56|8@1+ (1,0) [0|0] "" Vector__XXX
 SG_ DI_odometerStatusCounter : 52|4@1+ (1,0) [0|0] "" Vector__XXX
 SG_ DI_obdDriveCycleStatus : 32|1@1+ (1,0) [0|0] "" Vector__XXX
 SG_ DI_odometer : 0|32@1+ (0.001,0) [0|0] "" Vector__XXX

BO_ 952 UI_tpmsRCPsetting: 8 CH
 SG_ UI_setRCPRear : 24|8@1+ (0.025,0) [0|0] "bar"  X
 SG_ UI_setRCPFront : 16|8@1+ (0.025,0) [0|0] "bar"  X

BO_ 955 UI_power: 3 Vector__XXX
 SG_ UI_dSocAlertThreshold : 17|5@1+ (0.1,-3) [0|0] "" Vector__XXX
 SG_ UI_dSocAlertEnable : 16|1@1+ (1,0) [0|0] "" Vector__XXX
 SG_ UI_powerIdeal : 8|8@1+ (1,0) [0|0] "" Vector__XXX
 SG_ UI_powerExpected : 0|8@1+ (1,0) [0|0] "" Vector__XXX

BO_ 956 UI_tpmsRCPsetting_3BC: 4 Vector__XXX
 SG_ UI_setRCPRear : 24|8@1+ (0.025,0) [0|0] "" Vector__XXX
 SG_ UI_setRCPFront : 16|8@1+ (0.025,0) [0|0] "" Vector__XXX

BO_ 957 VCFRONT_parkedEnergyLoss: 8 Vector__XXX
 SG_ VCFRONT_evapDryingEnergyLossSinceCharge m4 : 50|14@1+ (0.01,0) [0|0] "" Vector__XXX
 SG_ VCFRONT_evapDryingEnergyLossSinceDrive m2 : 50|14@1+ (0.01,0) [0|0] "" Vector__XXX
 SG_ VCFRONT_mobileAppEnergyLossSinceCharge m3 : 50|14@1+ (0.01,0) [0|0] "" Vector__XXX
 SG_ VCFRONT_mobileAppEnergyLossSinceDrive m1 : 50|14@1+ (0.01,0) [0|0] "" Vector__XXX
 SG_ VCFRONT_backgroundEnergyLossSinceCharge m4 : 36|14@1+ (0.01,0) [0|0] "" Vector__XXX
 SG_ VCFRONT_backgroundEnergyLossSinceDrive m2 : 36|14@1+ (0.01,0) [0|0] "" Vector__XXX
 SG_ VCFRONT_cabinOverheatEnergyLossSinceCharge m3 : 36|14@1+ (0.01,0) [0|0] "" Vector__XXX
 SG_ VCFRONT_cabinOverheatEnergyLossSinceDrive m1 : 36|14@1+ (0.01,0) [0|0] "" Vector__XXX
 SG_ VCFRONT_preconditioningEnergyLossSinceCharge m3 : 22|14@1+ (0.01,0) [0|0] "" Vector__XXX
 SG_ VCFRONT_preconditioningEnergyLossSinceDrive m1 : 22|14@1+ (0.01,0) [0|0] "" Vector__XXX
 SG_ VCFRONT_sentryModeEnergyLossSinceCharge m4 : 22|14@1+ (0.01,0) [0|0] "" Vector__XXX
 SG_ VCFRONT_sentryModeEnergyLossSinceDrive m2 : 22|14@1+ (0.01,0) [0|0] "" Vector__XXX
 SG_ VCFRONT_currentEnergyLossReason m0 : 8|3@1+ (1,0) [0|0] "" Vector__XXX
 SG_ VCFRONT_summonStandbyEnergyLossSinceCharge m4 : 8|14@1+ (0.01,0) [0|0] "" Vector__XXX
 SG_ VCFRONT_summonStandbyEnergyLossSinceDrive m2 : 8|14@1+ (0.01,0) [0|0] "" Vector__XXX
 SG_ VCFRONT_userEnergyLossSinceCharge m3 : 8|14@1+ (0.01,0) [0|0] "" Vector__XXX
 SG_ VCFRONT_userEnergyLossSinceDrive m1 : 8|14@1+ (0.01,0) [0|0] "" Vector__XXX
 SG_ VCFRONT_parkedEnergyLossState m0 : 3|3@1+ (1,0) [0|0] "" Vector__XXX
 SG_ VCFRONT_energyLossIndex M : 0|3@1+ (1,0) [0|0] "" Vector__XXX

BO_ 962 VCLEFT_switchStatus: 8 VEH
 SG_ VCLEFT_rearCenterBuckleSwitch m0 : 62|2@1+ (1,0) [0|3] ""  X
 SG_ VCLEFT_rearHVACButtonPressed m0 : 61|1@1+ (1,0) [0|1] ""  X
 SG_ VCLEFT_brakePressed m0 : 60|1@1+ (1,0) [0|1] ""  X
 SG_ VCLEFT_rearRightOccupancySwitch m0 : 58|2@1+ (1,0) [0|3] ""  X
 SG_ VCLEFT_rearLeftOccupancySwitch m0 : 56|2@1+ (1,0) [0|3] ""  X
 SG_ VCLEFT_rearCenterOccupancySwitch m0 : 54|2@1+ (1,0) [0|3] ""  X
 SG_ VCLEFT_rearLeftBuckleSwitch m0 : 52|2@1+ (1,0) [0|3] ""  X
 SG_ VCLEFT_frontOccupancySwitch m0 : 50|2@1+ (1,0) [0|3] ""  X
 SG_ VCLEFT_frontBuckleSwitch m0 : 48|2@1+ (1,0) [0|3] ""  X
 SG_ VCLEFT_btnWindowSwPackAutoDownRR m0 : 47|1@1+ (1,0) [0|1] ""  X
 SG_ VCLEFT_btnWindowSwPackDownRR m0 : 46|1@1+ (1,0) [0|1] ""  X
 SG_ VCLEFT_btnWindowSwPackAutoUpRR m0 : 45|1@1+ (1,0) [0|1] ""  X
 SG_ VCLEFT_btnWindowSwPackUpRR m0 : 44|1@1+ (1,0) [0|1] ""  X
 SG_ VCLEFT_btnWindowSwPackAutoDownRF m0 : 43|1@1+ (1,0) [0|1] ""  X
 SG_ VCLEFT_btnWindowSwPackDownRF m0 : 42|1@1+ (1,0) [0|1] ""  X
 SG_ VCLEFT_swcRightDoublePress m1 : 42|1@1+ (1,0) [0|1] ""  X
 SG_ VCLEFT_btnWindowSwPackAutoUpRF m0 : 41|1@1+ (1,0) [0|1] ""  X
 SG_ VCLEFT_swcLeftDoublePress m1 : 41|1@1+ (1,0) [0|1] ""  X
 SG_ VCLEFT_2RowSeatBothFoldFlatSwitc m1 : 40|1@1+ (1,0) [0|1] ""  X
 SG_ VCLEFT_btnWindowSwPackUpRF m0 : 40|1@1+ (1,0) [0|1] ""  X
 SG_ VCLEFT_2RowSeatRightFoldFlatSwit m1 : 39|1@1+ (1,0) [0|1] ""  X
 SG_ VCLEFT_btnWindowSwPackAutoDownLR m0 : 39|1@1+ (1,0) [0|1] ""  X
 SG_ VCLEFT_2RowSeatLeftFoldFlatSwitc m1 : 38|1@1+ (1,0) [0|1] ""  X
 SG_ VCLEFT_btnWindowSwPackDownLR m0 : 38|1@1+ (1,0) [0|1] ""  X
 SG_ VCLEFT_2RowSeatCenterSwitch m1 : 37|1@1+ (1,0) [0|1] ""  X
 SG_ VCLEFT_btnWindowSwPackAutoUpLR m0 : 37|1@1+ (1,0) [0|1] ""  X
 SG_ VCLEFT_2RowSeatReclineSwitch m1 : 36|1@1+ (1,0) [0|1] ""  X
 SG_ VCLEFT_btnWindowSwPackUpLR m0 : 36|1@1+ (1,0) [0|1] ""  X
 SG_ VCLEFT_btnWindowAutoDownLR m1 : 35|1@1+ (1,0) [0|1] ""  X
 SG_ VCLEFT_btnWindowSwPackAutoDownLF m0 : 35|1@1+ (1,0) [0|1] ""  X
 SG_ VCLEFT_btnWindowDownLR m1 : 34|1@1+ (1,0) [0|1] ""  X
 SG_ VCLEFT_btnWindowSwPackDownLF m0 : 34|1@1+ (1,0) [0|1] ""  X
 SG_ VCLEFT_btnWindowAutoUpLR m1 : 33|1@1+ (1,0) [0|1] ""  X
 SG_ VCLEFT_btnWindowSwPackAutoUpLF m0 : 33|1@1+ (1,0) [0|1] ""  X
 SG_ VCLEFT_btnWindowSwPackUpLF m0 : 32|1@1+ (1,0) [0|1] ""  X
 SG_ VCLEFT_btnWindowUpLR m1 : 32|1@1+ (1,0) [0|1] ""  X
 SG_ VCLEFT_frontSeatLumbarOut m0 : 30|2@1+ (1,0) [0|3] ""  X
 SG_ VCLEFT_frontSeatLumbarIn m0 : 28|2@1+ (1,0) [0|3] ""  X
 SG_ VCLEFT_frontSeatLumbarUp m0 : 26|2@1+ (1,0) [0|3] ""  X
 SG_ VCLEFT_frontSeatLumbarDown m0 : 24|2@1+ (1,0) [0|3] ""  X
 SG_ VCLEFT_swcRightScrollTicks m1 : 24|6@1- (1,0) [-32|31] ""  X
 SG_ VCLEFT_frontSeatBackrestForward m0 : 22|2@1+ (1,0) [0|3] ""  X
 SG_ VCLEFT_frontSeatBackrestBack m0 : 20|2@1+ (1,0) [0|3] ""  X
 SG_ VCLEFT_frontSeatLiftUp m0 : 18|2@1+ (1,0) [0|3] ""  X
 SG_ VCLEFT_frontSeatLiftDown m0 : 16|2@1+ (1,0) [0|3] ""  X
 SG_ VCLEFT_swcLeftScrollTicks m1 : 16|6@1- (1,0) [-32|31] ""  X
 SG_ VCLEFT_frontSeatTiltUp m0 : 14|2@1+ (1,0) [0|3] ""  X
 SG_ VCLEFT_swcLeftTiltLeft m1 : 14|2@1+ (1,0) [0|3] ""  X
 SG_ VCLEFT_frontSeatTiltDown m0 : 12|2@1+ (1,0) [0|3] ""  X
 SG_ VCLEFT_swcRightPressed m1 : 12|2@1+ (1,0) [0|3] ""  X
 SG_ VCLEFT_frontSeatTrackForward m0 : 10|2@1+ (1,0) [0|3] ""  X
 SG_ VCLEFT_swcRightTiltRight m1 : 10|2@1+ (1,0) [0|3] ""  X
 SG_ VCLEFT_frontSeatTrackBack m0 : 8|2@1+ (1,0) [0|3] ""  X
 SG_ VCLEFT_swcRightTiltLeft m1 : 8|2@1+ (1,0) [0|3] ""  X
 SG_ VCLEFT_rightMirrorTilt m0 : 5|3@1+ (1,0) [0|4] ""  X
 SG_ VCLEFT_swcLeftPressed m1 : 5|2@1+ (1,0) [0|3] ""  X
 SG_ VCLEFT_brakeSwitchPressed m0 : 4|1@1+ (1,0) [0|1] ""  X
 SG_ VCLEFT_hazardButtonPressed m0 : 3|1@1+ (1,0) [0|1] ""  X
 SG_ VCLEFT_swcLeftTiltRight m1 : 3|2@1+ (1,0) [0|3] ""  X
 SG_ VCLEFT_hornSwitchPressed m0 : 2|1@1+ (1,0) [0|1] ""  X
 SG_ VCLEFT_switchStatusIndex M : 0|2@1+ (1,0) [0|2] ""  X

BO_ 963 VCRIGHT_switchStatus: 8 Vector__XXX
 SG_ VCRIGHT_3RowRightBuckleSwitch m0 : 62|2@1+ (1,0) [0|0] "" Vector__XXX
 SG_ VCRIGHT_3RowLeftBuckleSwitch m0 : 60|2@1+ (1,0) [0|0] "" Vector__XXX
 SG_ VCRIGHT_hvacHeatingAllowedRight m1 : 59|1@1+ (1,0) [0|0] "" Vector__XXX
 SG_ VCRIGHT_3RowRightOccupancySwitch m0 : 58|2@1+ (1,0) [0|0] "" Vector__XXX
 SG_ VCRIGHT_3RowLeftOccupancySwitch m0 : 56|2@1+ (1,0) [0|0] "" Vector__XXX
 SG_ VCRIGHT_frontSeatResistiveOccupancy m1 : 54|2@1+ (1,0) [0|0] "" Vector__XXX
 SG_ VCRIGHT_rearRightOccupancySwitch m0 : 54|2@1+ (1,0) [0|0] "" Vector__XXX
 SG_ VCRIGHT_liftgateShutfaceSwitchPressed m0 : 53|1@1+ (1,0) [0|0] "" Vector__XXX
 SG_ VCRIGHT_btnWindowSwPackAutoDwnRR m0 : 52|1@1+ (1,0) [0|0] "" Vector__XXX
 SG_ VCRIGHT_btnWindowSwPackDownRR m0 : 51|1@1+ (1,0) [0|0] "" Vector__XXX
 SG_ VCRIGHT_btnWindowSwPackAutoUpRR m0 : 50|1@1+ (1,0) [0|0] "" Vector__XXX
 SG_ VCRIGHT_btnWindowSwPackUpRR m0 : 49|1@1+ (1,0) [0|0] "" Vector__XXX
 SG_ VCRIGHT_trunkExtReleasePressed m0 : 48|1@1+ (1,0) [0|0] "" Vector__XXX
 SG_ VCRIGHT_gloveboxLightCurrent m1 : 47|5@1+ (2,0) [0|0] "" Vector__XXX
 SG_ VCRIGHT_rearRightBuckleSwitch m0 : 46|2@1+ (1,0) [0|0] "" Vector__XXX
 SG_ VCRIGHT_rearCenterBuckleSwitch m0 : 44|2@1+ (1,0) [0|0] "" Vector__XXX
 SG_ VCRIGHT_frontOccupancySwitch m0 : 42|2@1+ (1,0) [0|0] "" Vector__XXX
 SG_ VCRIGHT_frontBuckleSwitch m0 : 40|2@1+ (1,0) [0|0] "" Vector__XXX
 SG_ VCRIGHT_rearHandlePWM m1 : 40|7@1+ (1,0) [0|0] "" Vector__XXX
 SG_ VCRIGHT_btnWindowSwPackAutoDwnLR m0 : 39|1@1+ (1,0) [0|0] "" Vector__XXX
 SG_ VCRIGHT_hvacHeatingAllowedLeft m1 : 39|1@1+ (1,0) [0|0] "" Vector__XXX
 SG_ VCRIGHT_btnWindowSwPackDownLR m0 : 38|1@1+ (1,0) [0|0] "" Vector__XXX
 SG_ VCRIGHT_btnWindowSwPackAutoUpLR m0 : 37|1@1+ (1,0) [0|0] "" Vector__XXX
 SG_ VCRIGHT_btnWindowSwPackUpLR m0 : 36|1@1+ (1,0) [0|0] "" Vector__XXX
 SG_ VCRIGHT_btnWindowSwPackAutoDwnLF m0 : 35|1@1+ (1,0) [0|0] "" Vector__XXX
 SG_ VCRIGHT_btnWindowSwPackDownLF m0 : 34|1@1+ (1,0) [0|0] "" Vector__XXX
 SG_ VCRIGHT_btnWindowSwPackAutoUpLF m0 : 33|1@1+ (1,0) [0|0] "" Vector__XXX
 SG_ VCRIGHT_btnWindowSwPackUpLF m0 : 32|1@1+ (1,0) [0|0] "" Vector__XXX
 SG_ VCRIGHT_frontHandlePWM m1 : 32|7@1+ (1,0) [0|0] "" Vector__XXX
 SG_ VCRIGHT_btnWindowAutoDownRR m0 : 31|1@1+ (1,0) [0|0] "" Vector__XXX
 SG_ VCRIGHT_btnWindowDownRR m0 : 30|1@1+ (1,0) [0|0] "" Vector__XXX
 SG_ VCRIGHT_btnWindowAutoUpRR m0 : 29|1@1+ (1,0) [0|0] "" Vector__XXX
 SG_ VCRIGHT_btnWindowUpRR m0 : 28|1@1+ (1,0) [0|0] "" Vector__XXX
 SG_ VCRIGHT_2RowSeatBackrestFoldSwitch m1 : 27|1@1+ (1,0) [0|0] "" Vector__XXX
 SG_ VCRIGHT_btnWindowAutoDownRF m0 : 27|1@1+ (1,0) [0|0] "" Vector__XXX
 SG_ VCRIGHT_2RowSeatReclineSwitch m1 : 26|1@1+ (1,0) [0|0] "" Vector__XXX
 SG_ VCRIGHT_btnWindowDownRF m0 : 26|1@1+ (1,0) [0|0] "" Vector__XXX
 SG_ VCRIGHT_btnWindowAutoUpRF m0 : 25|1@1+ (1,0) [0|0] "" Vector__XXX
 SG_ VCRIGHT_btnWindowUpRF m0 : 24|1@1+ (1,0) [0|0] "" Vector__XXX
 SG_ VCRIGHT_frontSeatLumbarOut m1 : 24|2@1+ (1,0) [0|0] "" Vector__XXX
 SG_ VCRIGHT_frontSeatLumbarIn m1 : 22|2@1+ (1,0) [0|0] "" Vector__XXX
 SG_ VCRIGHT_frontSeatLumbarUp m1 : 20|2@1+ (1,0) [0|0] "" Vector__XXX
 SG_ VCRIGHT_frontSeatLumbarDown m1 : 18|2@1+ (1,0) [0|0] "" Vector__XXX
 SG_ VCRIGHT_frontSeatBackrestForward m1 : 16|2@1+ (1,0) [0|0] "" Vector__XXX
 SG_ VCRIGHT_frontSeatBackrestBack m1 : 14|2@1+ (1,0) [0|0] "" Vector__XXX
 SG_ VCRIGHT_frontSeatLiftUp m1 : 12|2@1+ (1,0) [0|0] "" Vector__XXX
 SG_ VCRIGHT_frontSeatLiftDown m1 : 10|2@1+ (1,0) [0|0] "" Vector__XXX
 SG_ VCRIGHT_frontSeatTiltUp m1 : 8|2@1+ (1,0) [0|0] "" Vector__XXX
 SG_ VCRIGHT_frontSeatTiltDown m1 : 6|2@1+ (1,0) [0|0] "" Vector__XXX
 SG_ VCRIGHT_frontSeatTrackForward m1 : 4|2@1+ (1,0) [0|0] "" Vector__XXX
 SG_ VCRIGHT_frontSeatTrackBack m1 : 2|2@1+ (1,0) [0|0] "" Vector__XXX
 SG_ VCRIGHT_trunkExtReleasePressedPersist m1 : 1|1@1+ (1,0) [0|0] "" Vector__XXX
 SG_ VCRIGHT_switchStatusIndex M : 0|1@1+ (1,0) [0|0] "" Vector__XXX

BO_ 964 PCS_info: 8 Vector__XXX
 SG_ PCS_partNumChar07 m25 : 56|8@1+ (1,0) [0|0] "" Vector__XXX
 SG_ PCS_partNumChar14 m26 : 56|8@1+ (1,0) [0|0] "" Vector__XXX
 SG_ PCS_serialNumChar07 m29 : 56|8@1+ (1,0) [0|0] "" Vector__XXX
 SG_ PCS_serialNumChar14 m30 : 56|8@1+ (1,0) [0|0] "" Vector__XXX
 SG_ PCS_componentId m10 : 48|16@1+ (1,0) [0|0] "" Vector__XXX
 SG_ PCS_partNumChar06 m25 : 48|8@1+ (1,0) [0|0] "" Vector__XXX
 SG_ PCS_partNumChar13 m26 : 48|8@1+ (1,0) [0|0] "" Vector__XXX
 SG_ PCS_partNumChar20 m27 : 48|8@1+ (1,0) [0|0] "" Vector__XXX
 SG_ PCS_serialNumChar06 m29 : 48|8@1+ (1,0) [0|0] "" Vector__XXX
 SG_ PCS_serialNumChar13 m30 : 48|8@1+ (1,0) [0|0] "" Vector__XXX
 SG_ PCS_subUsageId m11 : 48|16@1+ (1,0) [0|0] "" Vector__XXX
 SG_ PCS_partNumChar05 m25 : 40|8@1+ (1,0) [0|0] "" Vector__XXX
 SG_ PCS_partNumChar12 m26 : 40|8@1+ (1,0) [0|0] "" Vector__XXX
 SG_ PCS_partNumChar19 m27 : 40|8@1+ (1,0) [0|0] "" Vector__XXX
 SG_ PCS_serialNumChar05 m29 : 40|8@1+ (1,0) [0|0] "" Vector__XXX
 SG_ PCS_serialNumChar12 m30 : 40|8@1+ (1,0) [0|0] "" Vector__XXX
 SG_ PCS_appCrc m13 : 32|32@1+ (1,0) [0|0] "" Vector__XXX
 SG_ PCS_bootCrc m20 : 32|32@1+ (1,0) [0|0] "" Vector__XXX
 SG_ PCS_cpu2AppCrc m16 : 32|32@1+ (1,0) [0|0] "" Vector__XXX
 SG_ PCS_hardwareId m10 : 32|16@1+ (1,0) [0|0] "" Vector__XXX
 SG_ PCS_partNumChar04 m25 : 32|8@1+ (1,0) [0|0] "" Vector__XXX
 SG_ PCS_partNumChar11 m26 : 32|8@1+ (1,0) [0|0] "" Vector__XXX
 SG_ PCS_partNumChar18 m27 : 32|8@1+ (1,0) [0|0] "" Vector__XXX
 SG_ PCS_serialNumChar04 m29 : 32|8@1+ (1,0) [0|0] "" Vector__XXX
 SG_ PCS_serialNumChar11 m30 : 32|8@1+ (1,0) [0|0] "" Vector__XXX
 SG_ PCS_usageId m11 : 32|16@1+ (1,0) [0|0] "" Vector__XXX
 SG_ PCS_assemblyId m11 : 24|8@1+ (1,0) [0|0] "" Vector__XXX
 SG_ PCS_partNumChar03 m25 : 24|8@1+ (1,0) [0|0] "" Vector__XXX
 SG_ PCS_partNumChar10 m26 : 24|8@1+ (1,0) [0|0] "" Vector__XXX
 SG_ PCS_partNumChar17 m27 : 24|8@1+ (1,0) [0|0] "" Vector__XXX
 SG_ PCS_serialNumChar03 m29 : 24|8@1+ (1,0) [0|0] "" Vector__XXX
 SG_ PCS_serialNumChar10 m30 : 24|8@1+ (1,0) [0|0] "" Vector__XXX
 SG_ PCS_buildConfigId m10 : 16|16@1+ (1,0) [0|0] "" Vector__XXX
 SG_ PCS_partNumChar02 m25 : 16|8@1+ (1,0) [0|0] "" Vector__XXX
 SG_ PCS_partNumChar09 m26 : 16|8@1+ (1,0) [0|0] "" Vector__XXX
 SG_ PCS_partNumChar16 m27 : 16|8@1+ (1,0) [0|0] "" Vector__XXX
 SG_ PCS_pcbaId m11 : 16|8@1+ (1,0) [0|0] "" Vector__XXX
 SG_ PCS_serialNumChar02 m29 : 16|8@1+ (1,0) [0|0] "" Vector__XXX
 SG_ PCS_serialNumChar09 m30 : 16|8@1+ (1,0) [0|0] "" Vector__XXX
 SG_ PCS_appGitHash m17 : 8|56@1+ (1,0) [0|0] "" Vector__XXX
 SG_ PCS_bootGitHash m18 : 8|56@1+ (1,0) [0|0] "" Vector__XXX
 SG_ PCS_bootUdsProtoVersion m20 : 8|8@1+ (1,0) [0|0] "" Vector__XXX
 SG_ PCS_buildType m10 : 8|8@1+ (1,0) [0|0] "" Vector__XXX
 SG_ PCS_partNumChar01 m25 : 8|8@1+ (1,0) [0|0] "" Vector__XXX
 SG_ PCS_partNumChar08 m26 : 8|8@1+ (1,0) [0|0] "" Vector__XXX
 SG_ PCS_partNumChar15 m27 : 8|8@1+ (1,0) [0|0] "" Vector__XXX
 SG_ PCS_platformType m13 : 8|8@1+ (1,0) [0|0] "" Vector__XXX
 SG_ PCS_serialNumChar01 m29 : 8|8@1+ (1,0) [0|0] "" Vector__XXX
 SG_ PCS_serialNumChar08 m30 : 8|8@1+ (1,0) [0|0] "" Vector__XXX
 SG_ PCS_infoIndex M : 0|8@1+ (1,0) [0|0] "" Vector__XXX

BO_ 969 VCSEC_BLEEndpointInfo: 8 Vector__XXX
 SG_ VCSEC_BLECENTERUsageID m1 : 40|16@1+ (1,0) [0|0] "" Vector__XXX
 SG_ VCSEC_BLELEFTUsageID m4 : 40|16@1+ (1,0) [0|0] "" Vector__XXX
 SG_ VCSEC_BLEREARUsageID m10 : 40|16@1+ (1,0) [0|0] "" Vector__XXX
 SG_ VCSEC_BLERIGHTUsageID m7 : 40|16@1+ (1,0) [0|0] "" Vector__XXX
 SG_ VCSEC_BLECENTERAssemblyID m1 : 32|8@1+ (1,0) [0|0] "" Vector__XXX
 SG_ VCSEC_BLELEFTAssemblyID m4 : 32|8@1+ (1,0) [0|0] "" Vector__XXX
 SG_ VCSEC_BLEREARAssemblyID m10 : 32|8@1+ (1,0) [0|0] "" Vector__XXX
 SG_ VCSEC_BLERIGHTAssemblyID m7 : 32|8@1+ (1,0) [0|0] "" Vector__XXX
 SG_ VCSEC_BLECENTERPcbaID m1 : 24|8@1+ (1,0) [0|0] "" Vector__XXX
 SG_ VCSEC_BLELEFTPcbaID m4 : 24|8@1+ (1,0) [0|0] "" Vector__XXX
 SG_ VCSEC_BLEREARPcbaID m10 : 24|8@1+ (1,0) [0|0] "" Vector__XXX
 SG_ VCSEC_BLERIGHTPcbaID m7 : 24|8@1+ (1,0) [0|0] "" Vector__XXX
 SG_ VCSEC_BLECENTERAppGitHashByte m0 : 8|56@1+ (1,0) [0|0] "" Vector__XXX
 SG_ VCSEC_BLECENTERComponentID m1 : 8|16@1+ (1,0) [0|0] "" Vector__XXX
 SG_ VCSEC_BLECENTERCrc m2 : 8|32@1+ (1,0) [0|0] "" Vector__XXX
 SG_ VCSEC_BLELEFTAppGitHashByte m3 : 8|56@1+ (1,0) [0|0] "" Vector__XXX
 SG_ VCSEC_BLELEFTComponentID m4 : 8|16@1+ (1,0) [0|0] "" Vector__XXX
 SG_ VCSEC_BLELEFTCrc m5 : 8|32@1+ (1,0) [0|0] "" Vector__XXX
 SG_ VCSEC_BLEREARAppGitHashByte m9 : 8|56@1+ (1,0) [0|0] "" Vector__XXX
 SG_ VCSEC_BLEREARComponentID m10 : 8|16@1+ (1,0) [0|0] "" Vector__XXX
 SG_ VCSEC_BLEREARCrc m11 : 8|32@1+ (1,0) [0|0] "" Vector__XXX
 SG_ VCSEC_BLERIGHTAppGitHashByte m6 : 8|56@1+ (1,0) [0|0] "" Vector__XXX
 SG_ VCSEC_BLERIGHTComponentID m7 : 8|16@1+ (1,0) [0|0] "" Vector__XXX
 SG_ VCSEC_BLERIGHTCrc m8 : 8|32@1+ (1,0) [0|0] "" Vector__XXX
 SG_ VCSEC_BLEEndpointInfoIndex M : 0|8@1+ (1,0) [0|0] "" Vector__XXX

BO_ 972 APS_status: 8 Vector__XXX
 SG_ APS_apbActivePlannerType : 61|3@1+ (1,0) [0|0] "" Vector__XXX
 SG_ APS_appActivePlannerType : 58|3@1+ (1,0) [0|0] "" Vector__XXX
 SG_ APS_otherArbState : 55|3@1+ (1,0) [0|0] "" Vector__XXX
 SG_ APS_socPowerOperatingMode : 53|2@1+ (1,0) [0|0] "" Vector__XXX
 SG_ APS_arbState : 50|3@1+ (1,0) [0|0] "" Vector__XXX
 SG_ APS_gpsAntennaState : 48|2@1+ (1,0) [0|0] "" Vector__XXX
 SG_ APS_autosummonAlert : 47|1@1+ (1,0) [0|0] "" Vector__XXX
 SG_ APS_autosummonCounter : 44|3@1+ (1,0) [0|0] "" Vector__XXX
 SG_ APS_heaterStateDebug : 41|3@1+ (1,0) [0|0] "" Vector__XXX
 SG_ APS_apbPowerStateReason : 37|4@1+ (1,0) [0|0] "" Vector__XXX
 SG_ APS_apbPowerStateRequest : 35|2@1+ (1,0) [0|0] "" Vector__XXX
 SG_ APS_appPowerStateReason : 31|4@1+ (1,0) [0|0] "" Vector__XXX
 SG_ APS_appPowerStateRequest : 29|2@1+ (1,0) [0|0] "" Vector__XXX
 SG_ APS_locLimitReason : 26|3@1+ (1,0) [0|0] "" Vector__XXX
 SG_ APS_statusCounter : 22|4@1+ (1,0) [0|0] "" Vector__XXX
 SG_ APS_apbGpioState : 20|2@1+ (1,0) [0|0] "" Vector__XXX
 SG_ APS_apbStatusMonitorState : 16|3@1+ (1,0) [0|0] "" Vector__XXX
 SG_ APS_switchState : 15|1@1+ (1,0) [0|0] "" Vector__XXX
 SG_ APS_eacInternalState : 12|3@1+ (1,0) [0|0] "" Vector__XXX
 SG_ APS_appGpioState : 10|2@1+ (1,0) [0|0] "" Vector__XXX
 SG_ APS_canMaster : 8|2@1+ (1,0) [0|0] "" Vector__XXX
 SG_ APS_vehBehaviorState : 4|4@1+ (1,0) [0|0] "" Vector__XXX
 SG_ APS_appStatusMonitorState : 0|3@1+ (1,0) [0|0] "" Vector__XXX

BO_ 978 BMS_kwhCounter: 8 Vector__XXX
 SG_ BMS_kwhChargeTotal : 32|32@1+ (0.001,0) [0|0] "" Vector__XXX
 SG_ BMS_kwhDischargeTotal : 0|32@1+ (0.001,0) [0|0] "" Vector__XXX

BO_ 979 VCRIGHT_crashStatus: 3 Vector__XXX
 SG_ VCRIGHT_crashUnlockOverrideSet : 16|1@1+ (1,0) [0|0] "" Vector__XXX
 SG_ VCRIGHT_crashNumSwitchesDisabled : 8|8@1+ (1,0) [0|0] "" Vector__XXX
 SG_ VCRIGHT_crashState : 4|2@1+ (1,0) [0|0] "" Vector__XXX
 SG_ VCRIGHT_crashDetectedType : 0|2@1+ (1,0) [0|0] "" Vector__XXX

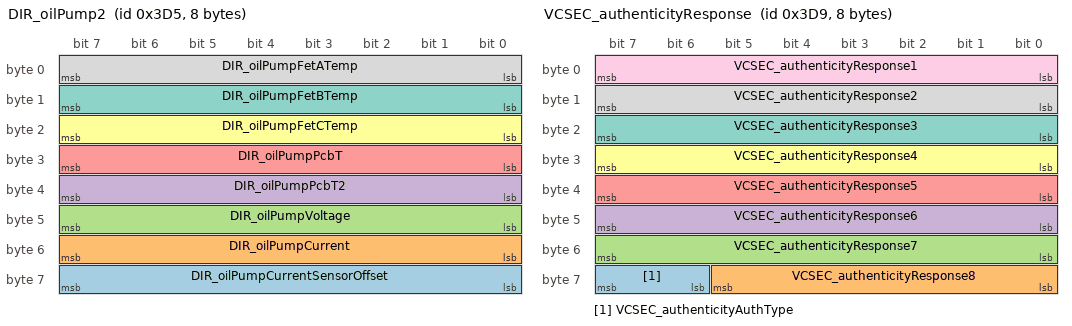
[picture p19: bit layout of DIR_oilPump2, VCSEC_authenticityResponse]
BO_ 981 DIR_oilPump2: 8 Vector__XXX
 SG_ DIR_oilPumpCurrentSensorOffset : 56|8@1+ (0.005,0) [0|0] "" Vector__XXX
 SG_ DIR_oilPumpCurrent : 48|8@1+ (0.1,0) [0|0] "" Vector__XXX
 SG_ DIR_oilPumpVoltage : 40|8@1+ (0.3,0) [0|0] "" Vector__XXX
 SG_ DIR_oilPumpPcbT2 : 32|8@1+ (1,-40) [0|0] "" Vector__XXX
 SG_ DIR_oilPumpPcbT : 24|8@1+ (1,-40) [0|0] "" Vector__XXX
 SG_ DIR_oilPumpFetCTemp : 16|8@1+ (1,-40) [0|0] "" Vector__XXX
 SG_ DIR_oilPumpFetBTemp : 8|8@1+ (1,-40) [0|0] "" Vector__XXX
 SG_ DIR_oilPumpFetATemp : 0|8@1+ (1,-40) [0|0] "" Vector__XXX

BO_ 984 UI_elevationStatus: 4 Vector__XXX
 SG_ UI_navElevation : 16|14@1- (1,0) [0|0] "" Vector__XXX
 SG_ UI_elevation : 0|14@1- (1,0) [0|0] "" Vector__XXX

BO_ 985 VCSEC_authenticityResponse: 8 Vector__XXX
 SG_ VCSEC_authenticityAuthType : 62|2@1+ (1,0) [0|0] "" Vector__XXX
 SG_ VCSEC_authenticityResponse8 : 56|6@1+ (1,0) [0|0] "" Vector__XXX
 SG_ VCSEC_authenticityResponse7 : 48|8@1+ (1,0) [0|0] "" Vector__XXX
 SG_ VCSEC_authenticityResponse6 : 40|8@1+ (1,0) [0|0] "" Vector__XXX
 SG_ VCSEC_authenticityResponse5 : 32|8@1+ (1,0) [0|0] "" Vector__XXX
 SG_ VCSEC_authenticityResponse4 : 24|8@1+ (1,0) [0|0] "" Vector__XXX
 SG_ VCSEC_authenticityResponse3 : 16|8@1+ (1,0) [0|0] "" Vector__XXX
 SG_ VCSEC_authenticityResponse2 : 8|8@1+ (1,0) [0|0] "" Vector__XXX
 SG_ VCSEC_authenticityResponse1 : 0|8@1+ (1,0) [0|0] "" Vector__XXX

BO_ 986 VCSEC_BLEUnexpectedEvent: 8 Vector__XXX
 SG_ VCSEC_unexpectedEventData : 32|32@1+ (1,0) [0|0] "" Vector__XXX
 SG_ VCSEC_unexpectedEventOpcode : 16|16@1+ (1,0) [0|0] "" Vector__XXX
 SG_ VCSEC_unexpectedEventLen : 8|8@1+ (1,0) [0|0] "" Vector__XXX
 SG_ VCSEC_unexpectedEventCode : 0|8@1+ (1,0) [0|0] "" Vector__XXX

CM_ BO_ 711 "ESP32-DualCAN Model3_VEH. Seen on this car: 8-byte frames; fit good (bits covered 100%, mux 100%, ranges 100%).";
CM_ BO_ 721 "ESP32-DualCAN Model3_VEH. Seen on this car: 2-byte frames; fit poor (bits covered 0%, mux 100%, ranges 100%).";
CM_ BO_ 722 "ESP32-DualCAN Model3_VEH. Seen on this car: 8-byte frames; fit good (bits covered 100%, mux 100%, ranges 100%).";
CM_ BO_ 723 "ESP32-DualCAN Model3_VEH. Seen on this car: 8-byte frames; fit good (bits covered 100%, mux 100%, ranges 100%).";
CM_ BO_ 727 "ESP32-DualCAN Model3_VEH. Seen on this car: 4-byte frames; fit ok (bits covered 100%, mux 100%, ranges 100%).";
CM_ BO_ 728 "ESP32-DualCAN Model3_VEH. Seen on this car: 2-byte frames; fit poor (bits covered 0%, mux 100%, ranges 100%).";
CM_ BO_ 737 "ESP32-DualCAN Model3_VEH. Seen on this car: 8-byte frames; fit good (bits covered 100%, mux 100%, ranges 100%). read by the app or firmware.";
CM_ BO_ 738 "ESP32-DualCAN Model3_VEH. Seen on this car: 8-byte frames; fit good (bits covered 100%, mux 100%, ranges 100%).";
CM_ BO_ 739 "ESP32-DualCAN Model3_VEH. Seen on this car: 7-byte frames; fit ok (bits covered 100%, mux 100%, ranges 100%).";
CM_ BO_ 744 "ESP32-DualCAN Model3_VEH. Seen on this car: 8-byte frames; fit good (bits covered 100%, mux 100%, ranges 100%, checksum 100%).";
CM_ BO_ 748 "ESP32-DualCAN Model3_VEH. Seen on this car: 3-byte frames; fit ok (bits covered 100%, mux 100%, ranges 100%, checksum 100%).";
CM_ BO_ 754 "ESP32-DualCAN Model3_VEH. Seen on this car: 2-byte frames; fit ok (bits covered 100%, mux 100%, ranges 100%).";
CM_ BO_ 755 "ESP32-DualCAN Model3_VEH. Seen on this car: 8-byte frames; fit good (bits covered 100%, mux 100%, ranges 100%). read by the app or firmware.";
CM_ BO_ 761 "ESP32-DualCAN Model3_VEH. Seen on this car: 8-byte frames; fit good (bits covered 100%, mux 100%, ranges 100%).";
CM_ BO_ 768 "ESP32-DualCAN Model3_VEH. Seen on this car: 8-byte frames; fit good (bits covered 100%, mux 100%, ranges 100%).";
CM_ BO_ 769 "ESP32-DualCAN Model3_VEH. Seen on this car: 8-byte frames; fit good (bits covered 100%, mux 100%, ranges 100%).";
CM_ BO_ 770 "ESP32-DualCAN Model3_VEH. Seen on this car: 8-byte frames; fit good (bits covered 100%, mux 71%, ranges 100%).";
CM_ BO_ 771 "ESP32-DualCAN Model3_VEH. Seen on this car: 8-byte frames; fit good (bits covered 100%, mux 100%, ranges 100%).";
CM_ BO_ 776 "ESP32-DualCAN Model3_VEH. Seen on this car: 8-byte frames; fit ok (bits covered 88%, mux 100%, ranges 100%, checksum 0%).";
CM_ BO_ 777 "DashKit DBC. Seen on this car: 8-byte frames; fit good (bits covered 100%, mux 79%, ranges 100%).";
CM_ BO_ 784 "ESP32-DualCAN Model3_VEH. Seen on this car: 8-byte frames; fit good (bits covered 100%, mux 100%, ranges 100%).";
CM_ BO_ 785 "ESP32-DualCAN Model3_VEH. Seen on this car: 2-byte frames; fit poor (bits covered 0%, mux 100%, ranges 100%).";
CM_ BO_ 786 "ESP32-DualCAN Model3_VEH. Seen on this car: 8-byte frames; fit good (bits covered 100%, mux 100%, ranges 100%).";
CM_ BO_ 787 "ESP32-DualCAN Model3_VEH. Seen on this car: 8-byte frames; fit good (bits covered 100%, mux 100%, ranges 100%, checksum 100%).";
CM_ BO_ 789 "ESP32-DualCAN Model3_VEH. Seen on this car: 8-byte frames; fit good (bits covered 100%, mux 100%, ranges 100%).";
CM_ BO_ 792 "ESP32-DualCAN Model3_VEH. Seen on this car: 8-byte frames; fit good (bits covered 100%, mux 100%, ranges 100%, checksum 100%).";
CM_ BO_ 793 "ESP32-DualCAN Model3_VEH. Seen on this car: 8-byte frames; fit good (bits covered 100%, mux 100%, ranges 100%).";
CM_ BO_ 794 "ESP32-DualCAN Model3_VEH. Seen on this car: 8-byte frames; fit good (bits covered 100%, mux 100%, ranges 100%, checksum 100%).";
CM_ BO_ 801 "ESP32-DualCAN Model3_VEH. Seen on this car: 8-byte frames; fit good (bits covered 100%, mux 100%, ranges 100%, checksum 100%).";
CM_ BO_ 803 "ESP32-DualCAN Model3_VEH. Seen on this car: 5-byte frames; fit ok (bits covered 100%, mux 100%, ranges 100%).";
CM_ BO_ 804 "ESP32-DualCAN Model3_VEH. Seen on this car: 8-byte frames; fit good (bits covered 100%, mux 100%, ranges 100%).";
CM_ BO_ 808 "ESP32-DualCAN Model3_VEH. Seen on this car: 7-byte frames; fit ok (bits covered 100%, mux 100%, ranges 100%).";
CM_ BO_ 810 "ESP32-DualCAN Model3_VEH. Seen on this car: 5-byte frames; fit weak (bits covered 100%, mux 100%, ranges 100%, checksum 0%).";
CM_ BO_ 816 "ESP32-DualCAN Model3_VEH. Seen on this car: 8-byte frames; fit ok (bits covered 100%, mux 100%, ranges 100%).";
CM_ BO_ 818 "ESP32-DualCAN Model3_VEH. Seen on this car: 6-byte frames; fit ok (bits covered 100%, mux 100%, ranges 100%). read by the app or firmware.";
CM_ BO_ 819 "ESP32-DualCAN Model3_VEH. Seen on this car: 5-byte frames; fit poor (bits covered 0%, mux 100%, ranges 100%). read by the app or firmware.";
CM_ BO_ 820 "ESP32-DualCAN Model3_VEH. Seen on this car: 8-byte frames; fit ok (bits covered 82%, mux 100%, ranges 100%, checksum 100%).";
CM_ BO_ 821 "ESP32-DualCAN Model3_VEH. Seen on this car: 8-byte frames; fit good (bits covered 100%, mux 100%, ranges 100%).";
CM_ BO_ 825 "ESP32-DualCAN Model3_VEH. Seen on this car: 8-byte frames; fit good (bits covered 100%, mux 100%, ranges 100%).";
CM_ BO_ 826 "ESP32-DualCAN Model3_VEH. Seen on this car: 8-byte frames; fit good (bits covered 100%, mux 100%, ranges 100%).";
CM_ BO_ 829 "ESP32-DualCAN Model3_VEH. Seen on this car: 8-byte frames; fit weak (bits covered 0%, mux 100%, ranges 100%).";
CM_ BO_ 835 "ESP32-DualCAN Model3_VEH. Seen on this car: 8-byte frames; fit good (bits covered 100%, mux 100%, ranges 100%).";
CM_ BO_ 836 "ESP32-DualCAN Model3_VEH. Seen on this car: 8-byte frames; fit good (bits covered 100%, mux 100%, ranges 100%, checksum 100%).";
CM_ BO_ 839 "DashKit DBC. Seen on this car: 8-byte frames; fit ok (bits covered 58%, mux 100%, ranges 100%).";
CM_ BO_ 840 "ESP32-DualCAN Model3_VEH. Seen on this car: 8-byte frames; fit good (bits covered 100%, mux 100%, ranges 100%).";
CM_ BO_ 842 "ESP32-DualCAN Model3_VEH. Seen on this car: 8-byte frames; fit good (bits covered 100%, mux 100%, ranges 100%).";
CM_ BO_ 850 "DashKit DBC. Seen on this car: 8-byte frames; fit ok (bits covered 86%, mux 49%, ranges 100%). read by the app or firmware; DashKit names kept.";
CM_ BO_ 851 "ESP32-DualCAN Model3_VEH. Seen on this car: 8-byte frames; fit good (bits covered 100%, mux 100%, ranges 100%).";
CM_ BO_ 853 "ESP32-DualCAN Model3_VEH. Seen on this car: 7-byte frames; fit ok (bits covered 100%, mux 100%, ranges 100%).";
CM_ BO_ 863 "ESP32-DualCAN Model3_VEH. Seen on this car: 1-byte frames; fit poor (bits covered 0%, mux 100%, ranges 100%).";
CM_ BO_ 865 "ESP32-DualCAN Model3_VEH. Seen on this car: 5-byte frames; fit ok (bits covered 100%, mux 100%, ranges 100%).";
CM_ BO_ 866 "ESP32-DualCAN Model3_VEH. Seen on this car: 3-byte frames; fit poor (bits covered 0%, mux 100%, ranges 100%).";
CM_ BO_ 868 "ESP32-DualCAN Model3_VEH. Seen on this car: 4-byte frames; fit ok (bits covered 100%, mux 100%, ranges 100%).";
CM_ BO_ 869 "ESP32-DualCAN Model3_VEH. Seen on this car: 8-byte frames; fit weak (bits covered 0%, mux 100%, ranges 100%).";
CM_ BO_ 870 "ESP32-DualCAN Model3_VEH. Seen on this car: 8-byte frames; fit ok (bits covered 100%, mux 100%, ranges 100%).";
CM_ BO_ 871 "ESP32-DualCAN Model3_VEH. Seen on this car: 8-byte frames; fit ok (bits covered 50%, mux 100%, ranges 100%).";
CM_ BO_ 880 "ESP32-DualCAN Model3_VEH. Seen on this car: 8-byte frames; fit weak (bits covered 0%, mux 100%, ranges 100%).";
CM_ BO_ 883 "ESP32-DualCAN Model3_VEH. Seen on this car: 8-byte frames; fit good (bits covered 100%, mux 100%, ranges 100%).";
CM_ BO_ 890 "ESP32-DualCAN Model3_VEH. Seen on this car: 8-byte frames; fit good (bits covered 100%, mux 100%, ranges 100%).";
CM_ BO_ 893 "ESP32-DualCAN Model3_VEH. Seen on this car: 8-byte frames; fit good (bits covered 100%, mux 100%, ranges 100%).";
CM_ BO_ 898 "ESP32-DualCAN Model3_VEH. Seen on this car: 5-byte frames; fit ok (bits covered 100%, mux 100%, ranges 100%).";
CM_ BO_ 899 "DashKit DBC. Seen on this car: 8-byte frames; fit good (bits covered 97%, mux 100%, ranges 100%). read by the app or firmware; DashKit names kept.";
CM_ BO_ 900 "ESP32-DualCAN Model3_VEH. Seen on this car: 8-byte frames; fit good (bits covered 100%, mux 100%, ranges 100%).";
CM_ BO_ 902 "ESP32-DualCAN Model3_VEH. Seen on this car: 8-byte frames; fit ok (bits covered 67%, mux 100%, ranges 100%).";
CM_ BO_ 904 "ESP32-DualCAN Model3_VEH. Seen on this car: 7-byte frames; fit ok (bits covered 100%, mux 100%, ranges 100%).";
CM_ BO_ 906 "ESP32-DualCAN Model3_VEH. Seen on this car: 8-byte frames; fit good (bits covered 100%, mux 100%, ranges 100%).";
CM_ BO_ 907 "ESP32-DualCAN Model3_VEH. Seen on this car: 8-byte frames; fit good (bits covered 100%, mux 100%, ranges 100%, checksum 100%).";
CM_ BO_ 909 "ESP32-DualCAN Model3_VEH. Seen on this car: 8-byte frames; fit good (bits covered 100%, mux 100%, ranges 100%).";
CM_ BO_ 912 "ESP32-DualCAN Model3_VEH. Seen on this car: 2-byte frames; fit poor (bits covered 0%, mux 100%, ranges 100%).";
CM_ BO_ 914 "ESP32-DualCAN Model3_VEH. Seen on this car: 8-byte frames; fit good (bits covered 100%, mux 100%, ranges 100%).";
CM_ BO_ 915 "ESP32-DualCAN Model3_VEH. Seen on this car: 8-byte frames; fit good (bits covered 100%, mux 100%, ranges 100%).";
CM_ BO_ 917 "ESP32-DualCAN Model3_VEH. Seen on this car: 8-byte frames; fit good (bits covered 100%, mux 100%, ranges 100%).";
CM_ BO_ 919 "ESP32-DualCAN Model3_VEH. Seen on this car: 8-byte frames; fit good (bits covered 100%, mux 100%, ranges 100%).";
CM_ BO_ 921 "ESP32-DualCAN Model3_VEH. Seen on this car: 3-byte frames; fit poor (bits covered 0%, mux 100%, ranges 100%).";
CM_ BO_ 922 "ESP32-DualCAN Model3_VEH. Seen on this car: 8-byte frames; fit good (bits covered 100%, mux 100%, ranges 100%).";
CM_ BO_ 923 "ESP32-DualCAN Model3_VEH. Seen on this car: 8-byte frames; fit good (bits covered 100%, mux 100%, ranges 100%, checksum 100%).";
CM_ BO_ 925 "ESP32-DualCAN Model3_VEH. Seen on this car: 5-byte frames; fit ok (bits covered 100%, mux 100%, ranges 100%, checksum 100%).";
CM_ BO_ 929 "ESP32-DualCAN Model3_VEH. Seen on this car: 8-byte frames; fit good (bits covered 100%, mux 100%, ranges 100%, checksum 100%).";
CM_ BO_ 930 "ESP32-DualCAN Model3_VEH. Seen on this car: 8-byte frames; fit good (bits covered 100%, mux 100%, ranges 100%).";
CM_ BO_ 931 "ESP32-DualCAN Model3_VEH. Seen on this car: 8-byte frames; fit good (bits covered 100%, mux 100%, ranges 100%).";
CM_ BO_ 935 "ESP32-DualCAN Model3_VEH. Seen on this car: 8-byte frames; fit good (bits covered 100%, mux 100%, ranges 100%).";
CM_ BO_ 936 "ESP32-DualCAN Model3_VEH. Seen on this car: 8-byte frames; fit good (bits covered 100%, mux 100%, ranges 100%).";
CM_ BO_ 941 "ESP32-DualCAN Model3_VEH. Seen on this car: 8-byte frames; fit good (bits covered 100%, mux 100%, ranges 100%).";
CM_ BO_ 942 "ESP32-DualCAN Model3_VEH. Seen on this car: 8-byte frames; fit ok (bits covered 100%, mux 100%, ranges 100%, checksum 0%).";
CM_ BO_ 947 "ESP32-DualCAN Model3_VEH. Seen on this car: 8-byte frames; fit good (bits covered 100%, mux 100%, ranges 100%). read by the app or firmware.";
CM_ BO_ 950 "ESP32-DualCAN Model3_VEH. Seen on this car: 8-byte frames; fit good (bits covered 100%, mux 100%, ranges 100%, checksum 100%). read by the app or firmware.";
CM_ BO_ 952 "DashKit DBC. Seen on this car: 8-byte frames; fit weak (bits covered 0%, mux 100%, ranges 100%).";
CM_ BO_ 955 "ESP32-DualCAN Model3_VEH. Seen on this car: 3-byte frames; fit poor (bits covered 0%, mux 100%, ranges 100%).";
CM_ BO_ 956 "ESP32-DualCAN Model3_VEH. Seen on this car: 4-byte frames; fit poor (bits covered 0%, mux 100%, ranges 100%).";
CM_ BO_ 957 "ESP32-DualCAN Model3_VEH. Seen on this car: 8-byte frames; fit good (bits covered 100%, mux 100%, ranges 100%).";
CM_ BO_ 962 "DashKit DBC. Seen on this car: 8-byte frames; fit good (bits covered 100%, mux 100%, ranges 100%). read by the app or firmware; DashKit names kept.";
CM_ BO_ 963 "ESP32-DualCAN Model3_VEH. Seen on this car: 8-byte frames; fit good (bits covered 100%, mux 100%, ranges 100%).";
CM_ BO_ 964 "ESP32-DualCAN Model3_VEH. Seen on this car: 8-byte frames; fit good (bits covered 100%, mux 100%, ranges 100%).";
CM_ BO_ 969 "ESP32-DualCAN Model3_VEH. Seen on this car: 8-byte frames; fit good (bits covered 100%, mux 100%, ranges 100%).";
CM_ BO_ 972 "ESP32-DualCAN Model3_VEH. Seen on this car: 8-byte frames; fit good (bits covered 100%, mux 100%, ranges 100%).";
CM_ BO_ 978 "ESP32-DualCAN Model3_VEH. Seen on this car: 8-byte frames; fit good (bits covered 100%, mux 100%, ranges 100%).";
CM_ BO_ 979 "ESP32-DualCAN Model3_VEH. Seen on this car: 3-byte frames; fit poor (bits covered 0%, mux 100%, ranges 100%).";
CM_ BO_ 981 "ESP32-DualCAN Model3_VEH. Seen on this car: 8-byte frames; fit good (bits covered 100%, mux 100%, ranges 100%).";
CM_ BO_ 984 "ESP32-DualCAN Model3_VEH. Seen on this car: 4-byte frames; fit ok (bits covered 100%, mux 100%, ranges 100%).";
CM_ BO_ 985 "ESP32-DualCAN Model3_VEH. Seen on this car: 8-byte frames; fit good (bits covered 100%, mux 100%, ranges 100%).";
CM_ BO_ 986 "ESP32-DualCAN Model3_VEH. Seen on this car: 8-byte frames; fit good (bits covered 100%, mux 100%, ranges 100%).";
BA_DEF_ BO_  "GenMsgCycleTime" INT 0 65535;
BA_DEF_DEF_  "GenMsgCycleTime" 0;
BA_ "GenMsgCycleTime" BO_ 777 30;
BA_ "GenMsgCycleTime" BO_ 850 1000;
BA_ "GenMsgCycleTime" BO_ 899 100;
BA_ "GenMsgCycleTime" BO_ 952 1000;
BA_ "GenMsgCycleTime" BO_ 962 50;
VAL_ 723 UI_screenPCBTemperature 2047 "GTW_I2C_TEMP_SNA" ;
VAL_ 723 UI_solarElevationAngle 127 "SNA" ;
VAL_ 723 UI_isSunUp 0 "DOWN" 1 "UP" 3 "SNA" ;
VAL_ 723 UI_solarAzimuthAngleCarRef 255 "SNA" ;
VAL_ 723 UI_solarAzimuthAngle 4294934528 "SNA" ;
VAL_ 727 VCLEFT_pitchEstimate 4294967232 "SNA" ;
VAL_ 728 ICR_nmWakeUpReason 0 "NONE" 1 "CAN_VEH" 2 "CAN_HVS" 3 "WANTTOCHARGE" 4 "CRITICALALERT" 5 "WANTTOWARM" ;
VAL_ 728 ICR_nmKeepAwakeReason 0 "NONE_SNA" 1 "CTRS_CLOSED" 2 "CRITICAL_ALERT" 3 "FC_CTR_CLEANING" 4 "HVP_ACTIVE" 5 "BMS_ACTIVE" 6 "CP_ACTIVE" ;
VAL_ 737 VCFRONT_frunkLatchType 0 "UNKNOWN" 1 "DOUBLE_ACTUATOR" 2 "DOUBLE_PULL" ;
VAL_ 737 VCFRONT_closeValvesRoutineStatus 0 "NOT_READY" 1 "MOVING_TO_FILL_POSITION" 2 "READY_TO_FILL" 3 "FAULTED" ;
VAL_ 737 VCFRONT_passengerBuckleStatus 0 "UNBUCKLED" 1 "BUCKLED" ;
VAL_ 737 VCFRONT_refrigFillRoutineStatus 0 "NOT_READY" 1 "MOVING_TO_FILL_POSITION" 2 "READY_TO_FILL" 3 "FAULTED" ;
VAL_ 737 VCFRONT_coolantFillRoutineStatus 0 "NOT_READY" 1 "MOVING_TO_FILL_POSITION" 2 "READY_TO_FILL" 3 "FAULTED" ;
VAL_ 737 VCFRONT_radarHeaterState 0 "SNA" 1 "ON" 2 "OFF" 3 "OFF_UNAVAILABLE" 4 "FAULT" ;
VAL_ 737 VCFRONT_hvacPerfTestCommand 0 "NOT_STARTED" 1 "INIT" 2 "BLOW" 3 "BLOW_BILEVEL" 4 "STOP" ;
VAL_ 737 VCFRONT_closureEasterEggState 0 "IDLE" 1 "ISOTP_RX" 2 "WAITING_FOR_ACTIVE_LOCK" 3 "SHOW_SETUP" 4 "WAITING_FOR_SYNC_PULSE" 5 "PLAY" 6 "SHOW_CLEANUP" ;
VAL_ 737 VCFRONT_pressureRefrigDischarge 511 "SNA" ;
VAL_ 737 VCFRONT_hibernationState 0 "INIT" 1 "NOT_ACTIVE" 2 "ACTIVE" 3 "RECOVERY" 4 "EXIT" 5 "PREP" ;
VAL_ 737 VCFRONT_pressureRefrigSuction 127 "SNA" ;
VAL_ 737 VCFRONT_AS8510Voltage 4095 "SNA" ;
VAL_ 737 VCFRONT_sleepCurrent 4095 "SNA" ;
VAL_ 737 VCFRONT_crashState 0 "IDLE" 1 "MINOR_1" 2 "MINOR_2" 3 "SEVERE" ;
VAL_ 737 VCFRONT_crashDetectedType 0 "NONE" 1 "MINOR_1" 2 "MINOR_2" 3 "SEVERE" ;
VAL_ 737 VCFRONT_vbatMonitorVoltage 4095 "SNA" ;
VAL_ 737 VCFRONT_wiperState 0 "SNA" 1 "SERVICE" 2 "FAULT" 3 "DELAYED_REST" 4 "PARK" 5 "WASH" 6 "MOMENTARY_WIPE" 7 "INTERMITTENT_HIGH" 8 "INTERMITTENT_LOW" 9 "CONT_FAST" 10 "CONT_SLOW" 11 "INT_AUTO_LOW" 12 "INT_AUTO_HIGH" ;
VAL_ 737 VCFRONT_wiperPosition 0 "SNA" 1 "SERVICE" 2 "DEPRESSED_PARK" 3 "DELAYED_REST" 4 "WIPING" ;
VAL_ 737 VCFRONT_vehicleStatusDBG 0 "INIT" 1 "LOW_POWER_AWAKE" 2 "CONDITIONING" 3 "ACCESSORY" 4 "ACCESSORY_PLUS" 5 "DRIVE" 6 "OTA" 7 "WAIT_FOR_HIGH_POWER" 8 "TURN_ON_LV" 9 "SYSTEM_CHECKS" 10 "LV_ON" 11 "JUMP_START" 12 "LV_SHUTDOWN" 13 "GO_QUIET" 14 "SLEEP_SHUTDOWN" 15 "LOW_POWER_STANDBY" 16 "RESET" ;
VAL_ 737 VCFRONT_wiperSpeed 0 "SNA" 1 "OFF" 2 "1" 3 "2" 4 "3" 5 "4" 6 "5" 7 "LOW" 8 "HIGH" ;
VAL_ 737 VCFRONT_iBoosterStateDBG 0 "OFF" 1 "ON" 2 "GOING_DOWN" 3 "WRITING_DATA_SHUTDOWN" 4 "FORCE_OFF" ;
VAL_ 737 VCFRONT_frunkLatchStatus 0 "SNA" 1 "OPENED" 2 "CLOSED" 3 "CLOSING" 4 "OPENING" 5 "AJAR" 6 "TIMEOUT" 7 "DEFAULT" 8 "FAULT" ;
VAL_ 737 VCFRONT_statusIndex 0 "BODY_CONTROLS" 1 "VEHICLE_STATE" 2 "HOMELINK" 3 "REFRIGERANT_SYSTEM" 4 "SYSTEM_HEALTH" 5 "INVALID" ;
VAL_ 738 VCLEFT_frontSeatHeatTmpTarget 0 "OFF" ;
VAL_ 738 VCLEFT_frontSeatHeatTmp 0 "SNA" ;
VAL_ 738 VCLEFT_seatStatus2Index 0 "SEAT_HEAT_FRONT" 1 "SEAT_HEAT_REARL_BACKREST" 2 "OCCUPANCY" 3 "SEAT_HEAT_REARL" 4 "SEAT_HEAT_REARC" 5 "SEAT_HEAT_REARR_CUSHION" 6 "SEAT_2ROW_ACTUATOR" 7 "SEAT_SWITCH_VOLTAGES_1" 8 "SEAT_SWITCH_VOLTAGES_2" 9 "SEAT_2ROW_EASY_ENTRY" 10 "SEAT_STATUS_2_INDEX_COUNT" ;
VAL_ 739 VCRIGHT_frontSeatHeatTmpTarget 0 "OFF" ;
VAL_ 739 VCRIGHT_frontSeatHeatTmp 0 "SNA" ;
VAL_ 739 VCRIGHT_seatStatus2Index 0 "SEAT_HEAT_FRONT" 1 "SEAT_HEAT_REARL_CUSHION" 2 "SEAT_HEAT_REARC" 3 "SEAT_HEAT_REARR" 4 "OCCUPANCY" 5 "SEAT_HEAT_REARR_BACKREST" 6 "SEAT_2ROW_ACTUATOR" 7 "SEAT_SWITCH_VOLTAGES_1" 8 "SEAT_SWITCH_VOLTAGES_2" 9 "SEAT_2ROW_EASY_ENTRY" 10 "OCS_IEE" 11 "SEAT_STATUS_2_INDEX_COUNT" ;
VAL_ 744 EPBR_brakeDiscWipeRequest 0 "NONE" 1 "LIGHT" 2 "STRONG" 3 "SNA" ;
VAL_ 744 EPBR_cdpRequest 0 "NOT_REQUESTED" 1 "REQUESTED" ;
VAL_ 744 EPBR_telltale 0 "LAMP_OFF" 1 "LAMP_RED_ON" 2 "LAMP_AMBER_ON" 3 "LAMP_RED_FLASH" 7 "SNA" ;
VAL_ 744 EPBR_freeRollModeStatus 0 "UNAVAILABLE" 1 "AVAILABLE" 2 "ENABLED" ;
VAL_ 744 EPBR_systemStatus 0 "UNKNOWN" 1 "RELEASED" 2 "PARKED" 3 "DYNAMIC" 4 "PARKING" 5 "RELEASING" 6 "FAULT" 7 "FAULT_SECURE" 8 "MISMATCH" ;
VAL_ 754 BMS_nmWakeUpReason 0 "NONE" 1 "CAN_VEH" 2 "CAN_HVS" 3 "WANTTOCHARGE" 4 "CRITICALALERT" 5 "WANTTOWARM" ;
VAL_ 754 BMS_nmKeepAwakeReason 0 "NONE_SNA" 1 "CTRS_CLOSED" 2 "CRITICAL_ALERT" 3 "FC_CTR_CLEANING" 4 "HVP_ACTIVE" 5 "BMS_ACTIVE" 6 "CP_ACTIVE" ;
VAL_ 755 UI_hvacReqKeepClimateOn 0 "OFF" 1 "ON" 2 "DOG" 3 "PARTY" ;
VAL_ 755 UI_hvacReqSecondRowState 0 "AUTO" 1 "OFF" 2 "LOW" 3 "MED" 4 "HIGH" ;
VAL_ 755 UI_hvacReqUserPowerState 0 "OFF" 1 "ON" 2 "PRECONDITION" 3 "OVERHEAT_PROTECT_FANONLY" 4 "OVERHEAT_PROTECT" ;
VAL_ 755 UI_hvacReqACDisable 0 "AUTO" 1 "OFF" 2 "ON" ;
VAL_ 755 UI_hvacReqRecirc 0 "AUTO" 1 "RECIRC" 2 "FRESH" ;
VAL_ 755 UI_hvacReqBlowerSegment 0 "OFF" 1 "1" 2 "2" 3 "3" 4 "4" 5 "5" 6 "6" 7 "7" 8 "8" 9 "9" 10 "10" 11 "AUTO" ;
VAL_ 755 UI_hvacReqAirDistributionMode 0 "AUTO" 1 "MANUAL_FLOOR" 2 "MANUAL_PANEL" 3 "MANUAL_PANEL_FLOOR" 4 "MANUAL_DEFROST" 5 "MANUAL_DEFROST_FLOOR" 6 "MANUAL_DEFROST_PANEL" 7 "MANUAL_DEFROST_PANEL_FLOOR" ;
VAL_ 755 UI_hvacReqTempSetpointRight 0 "LO" 26 "HI" ;
VAL_ 755 UI_hvacReqTempSetpointLeft 0 "LO" 26 "HI" ;
VAL_ 761 VCSEC_AdditionalAuthInfoIndex 0 "ACTIVE_KEY_SHA1" 1 "KEY_WITH_IN_SUMMON_RANGE_0" 2 "KEY_WITH_IN_SUMMON_RANGE_1" 3 "KEY_WITH_IN_SUMMON_RANGE_2" 4 "UNKNOWN_BLE_DEVICE_WITH_IN_SUMMON_RANGE" 5 "WALKUP_UNLOCK_BEHAVIOR" ;
VAL_ 761 VCSEC_activeKeyReason 0 "NONE" 1 "NFC_AUTH" 2 "RKE_AUTH" 3 "BLE_DEVICE_CLOSEST_TO_DOOR" 4 "RKE_ACTION" 5 "ONLY_AUTHED_DEVICE" 6 "AUTO_PRESENT_DOOR_COMMAND" ;
VAL_ 761 VCSEC_bleDisconnectionReason 0 "UNKNOWN_REASON_0" 5 "AUTHENTICATION_FAILURE" 8 "CONNECTION_SUPERVISION_TIMEOUT" 19 "REMOTE_USER_TERMINATED" 20 "REMOTE_DEVICE_LOW_RESOURCES" 21 "REMOTE_DEVICE_POWER_OFF" 22 "HOST_REQUESTED_TERMINATION" 26 "UNSUPPORTED_REMOTE_FEATURE" 34 "CONTROL_PACKET_TIMEOUT" 40 "CONTROL_PACKET_INSTANT_PASSED" 41 "KEY_PAIRING_NOT_SUPPORTED" 59 "UNACCEPTABLE_CONNECTION_INTERVAL" 61 "MIC_FAILURE" 62 "CONNECTION_FAILED_TO_ESTABLISH" 255 "UNKNOWN_REASON_FF" ;
VAL_ 768 BMS_hardwareId 252 "CONFIGURABLE_HWID_PLACEHOLDER" ;
VAL_ 768 BMS_buildType 0 "UNKNOWN_BUILD" 1 "PLATFORM_BUILD" 2 "LOCAL_BUILD" 3 "TRACEABLE_CI_BUILD" 4 "MFG_BUILD" ;
VAL_ 768 BMS_platformType 0 "UNKNOWN" 3 "MODEL3" 255 "END" ;
VAL_ 768 BMS_infoIndex 0 "DEPRECATED_0" 1 "DEPRECATED_1" 2 "DEPRECATED_2" 3 "DEPRECATED_3" 4 "DEPRECATED_4" 5 "DEPRECATED_5" 6 "DEPRECATED_6" 7 "DEPRECATED_7" 8 "DEPRECATED_8" 9 "DEPRECATED_9" 10 "BUILD_HWID_COMPONENTID" 11 "PCBAID_ASSYID_USAGEID" 13 "APP_CRC" 14 "BOOTLOADER_SVN" 15 "BOOTLOADER_CRC" 16 "SUBCOMPONENT" 17 "APP_GITHASH" 18 "BOOTLOADER_GITHASH" 19 "VERSION_DEPRECATED" 20 "UDS_PROTOCOL_BOOTCRC" 22 "VARIANTCRC" 25 "PACKAGE_PN_1_7" 26 "PACKAGE_PN_8_14" 27 "PACKAGE_PN_15_20" 29 "PACKAGE_SN_1_7" 30 "PACKAGE_SN_8_14" 31 "SUBCOMPONENT_GITHASH" 255 "END" ;
VAL_ 769 VCFRONT_infoAssemblyId 1 "ASSEMBLY1" 255 "ASSEMBLY_SNA" ;
VAL_ 769 VCFRONT_infoBuildType 0 "UNKNOWN_BUILD" 1 "PLATFORM_BUILD" 2 "LOCAL_BUILD" 3 "TRACEABLE_CI_BUILD" 4 "MFG_BUILD" ;
VAL_ 769 VCFRONT_infoIndex 0 "DEPRECATED_0" 1 "DEPRECATED_1" 2 "DEPRECATED_2" 3 "DEPRECATED_3" 4 "DEPRECATED_4" 5 "DEPRECATED_5" 6 "DEPRECATED_6" 7 "DEPRECATED_7" 8 "DEPRECATED_8" 9 "DEPRECATED_9" 10 "BUILD_HWID_COMPONENTID" 11 "PCBAID_ASSYID_USAGEID" 13 "APP_CRC" 14 "BOOTLOADER_SVN" 15 "BOOTLOADER_CRC" 16 "SUBCOMPONENT1" 17 "APP_GITHASH" 18 "BOOTLOADER_GITHASH" 19 "VERSION_DEPRECATED" 20 "UDS_PROTOCOL_BOOTCRC" 23 "SUBCOMPONENT2" 24 "SUBCOMPONENT3" 31 "SUBCOMPONENT4" 32 "SUBCOMPONENT5" 33 "SUBCOMPONENT6" 34 "SUBCOMPONENT7" 35 "SUBCOMPONENT8" 36 "SUBCOMPONENT9" 37 "SUBCOMPONENT10" 38 "SUBCOMPONENT11" 39 "SUBCOMPONENT12" 40 "SUBCOMPONENT13" 41 "SUBCOMPONENT14" 255 "END" ;
VAL_ 770 VCLEFT_infoAssemblyId 1 "ASSEMBLY1" 255 "ASSEMBLY_SNA" ;
VAL_ 770 VCLEFT_infoBuildType 0 "UNKNOWN_BUILD" 1 "PLATFORM_BUILD" 2 "LOCAL_BUILD" 3 "TRACEABLE_CI_BUILD" 4 "MFG_BUILD" ;
VAL_ 770 VCLEFT_infoIndex 0 "DEPRECATED_0" 1 "DEPRECATED_1" 2 "DEPRECATED_2" 3 "DEPRECATED_3" 4 "DEPRECATED_4" 5 "DEPRECATED_5" 6 "DEPRECATED_6" 7 "DEPRECATED_7" 8 "DEPRECATED_8" 9 "DEPRECATED_9" 10 "BUILD_HWID_COMPONENTID" 11 "PCBAID_ASSYID_USAGEID" 13 "APP_CRC" 14 "BOOTLOADER_SVN" 15 "BOOTLOADER_CRC" 16 "SUBCOMPONENT1" 17 "APP_GITHASH" 18 "BOOTLOADER_GITHASH" 19 "VERSION_DEPRECATED" 20 "UDS_PROTOCOL_BOOTCRC" 23 "SUBCOMPONENT2" 24 "SUBCOMPONENT3" 31 "SUBCOMPONENT4" 32 "SUBCOMPONENT5" 33 "SUBCOMPONENT6" 34 "SUBCOMPONENT7" 35 "SUBCOMPONENT8" 36 "SUBCOMPONENT9" 37 "SUBCOMPONENT10" 38 "SUBCOMPONENT11" 39 "SUBCOMPONENT12" 40 "SUBCOMPONENT13" 41 "SUBCOMPONENT14" 255 "END" ;
VAL_ 771 VCRIGHT_infoAssemblyId 1 "ASSEMBLY1" 255 "ASSEMBLY_SNA" ;
VAL_ 771 VCRIGHT_infoBuildType 0 "UNKNOWN_BUILD" 1 "PLATFORM_BUILD" 2 "LOCAL_BUILD" 3 "TRACEABLE_CI_BUILD" 4 "MFG_BUILD" ;
VAL_ 771 VCRIGHT_infoIndex 0 "DEPRECATED_0" 1 "DEPRECATED_1" 2 "DEPRECATED_2" 3 "DEPRECATED_3" 4 "DEPRECATED_4" 5 "DEPRECATED_5" 6 "DEPRECATED_6" 7 "DEPRECATED_7" 8 "DEPRECATED_8" 9 "DEPRECATED_9" 10 "BUILD_HWID_COMPONENTID" 11 "PCBAID_ASSYID_USAGEID" 13 "APP_CRC" 14 "BOOTLOADER_SVN" 15 "BOOTLOADER_CRC" 16 "SUBCOMPONENT1" 17 "APP_GITHASH" 18 "BOOTLOADER_GITHASH" 19 "VERSION_DEPRECATED" 20 "UDS_PROTOCOL_BOOTCRC" 23 "SUBCOMPONENT2" 24 "SUBCOMPONENT3" 31 "SUBCOMPONENT4" 32 "SUBCOMPONENT5" 33 "SUBCOMPONENT6" 34 "SUBCOMPONENT7" 35 "SUBCOMPONENT8" 36 "SUBCOMPONENT9" 37 "SUBCOMPONENT10" 38 "SUBCOMPONENT11" 39 "SUBCOMPONENT12" 40 "SUBCOMPONENT13" 41 "SUBCOMPONENT14" 255 "END" ;
VAL_ 776 OCS1P_occupantClassificationQF 0 "FAULTED" 1 "NOT_FAULTED" ;
VAL_ 776 OCS1P_occupantClassification 0 "EMPTY" 1 "INHIBIT" 2 "SMALL" 3 "LARGE" 4 "INIT" 5 "NOT_CONFIGURED" 7 "SNA" ;
VAL_ 777 DAS_leadVeh2Id 0 "SNA" ;
VAL_ 777 DAS_leftVeh2Id 0 "SNA" ;
VAL_ 777 DAS_rightVeh2Id 0 "SNA" ;
VAL_ 777 DAS_cutinVehHeading 255 "SNA" ;
VAL_ 777 DAS_rightVeh2Heading 255 "SNA" ;
VAL_ 777 DAS_leadVeh2VxRel 15 "SNA" ;
VAL_ 777 DAS_leftVeh2VxRel 15 "SNA" ;
VAL_ 777 DAS_rightVeh2VxRel 15 "SNA" ;
VAL_ 777 DAS_rightVehHeading 255 "SNA" ;
VAL_ 777 DAS_leadVeh2Dx 255 "SNA" ;
VAL_ 777 DAS_leftVeh2Dx 255 "SNA" ;
VAL_ 777 DAS_rightVeh2Dx 255 "SNA" ;
VAL_ 777 DAS_leadVeh2Type 0 "UNKNOWN" 1 "TRUCK" 2 "CAR" 3 "MOTORCYCLE" 4 "BICYCLE" 5 "PEDESTRIAN" ;
VAL_ 777 DAS_leftVeh2Type 0 "UNKNOWN" 1 "TRUCK" 2 "CAR" 3 "MOTORCYCLE" 4 "BICYCLE" 5 "PEDESTRIAN" ;
VAL_ 777 DAS_rightVeh2Type 0 "UNKNOWN" 1 "TRUCK" 2 "CAR" 3 "MOTORCYCLE" 4 "BICYCLE" 5 "PEDESTRIAN" ;
VAL_ 777 DAS_leftVeh2Heading 255 "SNA" ;
VAL_ 777 DAS_roadSignOrientation 0 "UNKNOWN" 1 "VERTICAL_3_LIGHT" 2 "HORIZONTAL_3_LIGHT" ;
VAL_ 777 DAS_leadVehId 127 "SNA" ;
VAL_ 777 DAS_leftVehId 127 "SNA" ;
VAL_ 777 DAS_rightVehId 127 "SNA" ;
VAL_ 777 DAS_cutinVehId 127 "SNA" ;
VAL_ 777 DAS_roadSignArrow 0 "CIRCLE" 1 "LEFT" 2 "RIGHT" 3 "STRAIGHT" 4 "UNKNOWN" ;
VAL_ 777 DAS_roadSignSource 0 "NONE" 1 "NAV" 2 "VISION" ;
VAL_ 777 DAS_leftVehHeading 255 "SNA" ;
VAL_ 777 DAS_leadVehVxRel 15 "SNA" ;
VAL_ 777 DAS_leftVehVxRel 15 "SNA" ;
VAL_ 777 DAS_rightVehVxRel 15 "SNA" ;
VAL_ 777 DAS_cutinVehVxRel 15 "SNA" ;
VAL_ 777 DAS_leadVeh2Heading 255 "SNA" ;
VAL_ 777 DAS_roadSignStopLineDist 1023 "SNA" ;
VAL_ 777 DAS_leadVehDx 255 "SNA" ;
VAL_ 777 DAS_leftVehDx 255 "SNA" ;
VAL_ 777 DAS_rightVehDx 255 "SNA" ;
VAL_ 777 DAS_cutinVehDx 255 "SNA" ;
VAL_ 777 DAS_leadVehHeading 255 "SNA" ;
VAL_ 777 DAS_roadSignId 0 "STOP_SIGN" 1 "TRAFFIC_LIGHT" 255 "SNA" ;
VAL_ 777 DAS_leadVehType 0 "UNKNOWN" 1 "TRUCK" 2 "CAR" 3 "MOTORCYCLE" 4 "BICYCLE" 5 "PEDESTRIAN" 6 "IPSO" ;
VAL_ 777 DAS_leftVehType 0 "UNKNOWN" 1 "TRUCK" 2 "CAR" 3 "MOTORCYCLE" 4 "BICYCLE" 5 "PEDESTRIAN" ;
VAL_ 777 DAS_rightVehType 0 "UNKNOWN" 1 "TRUCK" 2 "CAR" 3 "MOTORCYCLE" 4 "BICYCLE" 5 "PEDESTRIAN" ;
VAL_ 777 DAS_cutinVehType 0 "UNKNOWN" 1 "TRUCK" 2 "CAR" 3 "MOTORCYCLE" 4 "BICYCLE" 5 "PEDESTRIAN" ;
VAL_ 777 DAS_roadSignColor 0 "NONE" 1 "RED" 2 "YELLOW" 3 "GREEN" 4 "RED_YELLOW" ;
VAL_ 777 DAS_objectId 0 "LEAD_VEHICLES" 1 "LEFT_VEHICLES" 2 "RIGHT_VEHICLES" 3 "CUTIN_VEHICLE" 4 "ROAD_SIGN" 5 "VEHICLE_HEADINGS" ;
VAL_ 784 HVP_hardwareId 252 "CONFIGURABLE_HWID_PLACEHOLDER" ;
VAL_ 784 HVP_buildType 0 "UNKNOWN_BUILD" 1 "PLATFORM_BUILD" 2 "LOCAL_BUILD" 3 "TRACEABLE_CI_BUILD" 4 "MFG_BUILD" ;
VAL_ 784 HVP_platformType 0 "UNKNOWN" 3 "MODEL3" 255 "END" ;
VAL_ 784 HVP_infoIndex 0 "DEPRECATED_0" 1 "DEPRECATED_1" 2 "DEPRECATED_2" 3 "DEPRECATED_3" 4 "DEPRECATED_4" 5 "DEPRECATED_5" 6 "DEPRECATED_6" 7 "DEPRECATED_7" 8 "DEPRECATED_8" 9 "DEPRECATED_9" 10 "BUILD_HWID_COMPONENTID" 11 "PCBAID_ASSYID_USAGEID" 13 "APP_CRC" 14 "BOOTLOADER_SVN" 15 "BOOTLOADER_CRC" 16 "SUBCOMPONENT" 17 "APP_GITHASH" 18 "BOOTLOADER_GITHASH" 19 "VERSION_DEPRECATED" 20 "UDS_PROTOCOL_BOOTCRC" 22 "VARIANTCRC" 25 "PACKAGE_PN_1_7" 26 "PACKAGE_PN_8_14" 27 "PACKAGE_PN_15_20" 29 "PACKAGE_SN_1_7" 30 "PACKAGE_SN_8_14" 31 "SUBCOMPONENT_GITHASH" 255 "END" ;
VAL_ 787 UI_trackModeBrakeTemps 0 "OFF" 1 "ON" ;
VAL_ 787 UI_trackCmpOverclock 0 "OFF" 1 "ON" ;
VAL_ 787 UI_trackPostCooling 0 "OFF" 1 "ON" ;
VAL_ 787 UI_trackModeRequest 0 "IDLE" 1 "ON" 2 "OFF" ;
VAL_ 789 DIR_additionalFetBurnIn 65535 "SNA" ;
VAL_ 789 DIR_normalFetBurnIn 65535 "SNA" ;
VAL_ 789 DIR_inverterTQF 0 "INIT" 1 "IRRATIONAL" 2 "RATIONAL" 3 "UNKNOWN" ;
VAL_ 789 DIR_tempIndex 0 "Mux0" 1 "Mux1" 2 "Mux2" ;
VAL_ 793 VCSEC_infoAssemblyId 1 "ASSEMBLY1" 255 "ASSEMBLY_SNA" ;
VAL_ 793 VCSEC_infoBuildType 0 "UNKNOWN_BUILD" 1 "PLATFORM_BUILD" 2 "LOCAL_BUILD" 3 "TRACEABLE_CI_BUILD" 4 "MFG_BUILD" ;
VAL_ 793 VCSEC_infoIndex 0 "DEPRECATED_0" 1 "DEPRECATED_1" 2 "DEPRECATED_2" 3 "DEPRECATED_3" 4 "DEPRECATED_4" 5 "DEPRECATED_5" 6 "DEPRECATED_6" 7 "DEPRECATED_7" 8 "DEPRECATED_8" 9 "DEPRECATED_9" 10 "BUILD_HWID_COMPONENTID" 11 "PCBAID_ASSYID_USAGEID" 13 "APP_CRC" 14 "BOOTLOADER_SVN" 15 "BOOTLOADER_CRC" 16 "SUBCOMPONENT1" 17 "APP_GITHASH" 18 "BOOTLOADER_GITHASH" 19 "VERSION_DEPRECATED" 20 "UDS_PROTOCOL_BOOTCRC" 23 "SUBCOMPONENT2" 24 "SUBCOMPONENT3" 31 "SUBCOMPONENT4" 32 "SUBCOMPONENT5" 33 "SUBCOMPONENT6" 34 "SUBCOMPONENT7" 35 "SUBCOMPONENT8" 36 "SUBCOMPONENT9" 37 "SUBCOMPONENT10" 38 "SUBCOMPONENT11" 39 "SUBCOMPONENT12" 40 "SUBCOMPONENT13" 41 "SUBCOMPONENT14" 255 "END" ;
VAL_ 794 VCRIGHT_occupantClassificationQF 0 "FAULTED" 1 "NOT_FAULTED" ;
VAL_ 794 VCRIGHT_occupantClassification 0 "EMPTY" 1 "INHIBIT" 2 "SMALL" 3 "LARGE" 4 "INIT" 5 "NOT_CONFIGURED" 7 "SNA" ;
VAL_ 794 VCRIGHT_seatTrackPosition 0 "FORWARD" 1 "REARWARD" 2 "NOT_CONFIGURED" 3 "FAULTED" 7 "SNA" ;
VAL_ 794 VCRIGHT_3RowRightOccupancyStatus 0 "UNOCCUPIED" 1 "OCCUPIED" 2 "OCCUPANCY_FAULTED" 3 "OCCUPANCY_SNA" ;
VAL_ 794 VCRIGHT_3RowLeftOccupancyStatus 0 "UNOCCUPIED" 1 "OCCUPIED" 2 "OCCUPANCY_FAULTED" 3 "OCCUPANCY_SNA" ;
VAL_ 794 VCRIGHT_3RowRightBuckleStatus 0 "UNLATCHED" 1 "LATCHED" 2 "FAULTED" 3 "SNA" ;
VAL_ 794 VCRIGHT_3RowLeftBuckleStatus 0 "UNLATCHED" 1 "LATCHED" 2 "FAULTED" 3 "SNA" ;
VAL_ 794 VCRIGHT_rearRightOccupancyStatus 0 "UNOCCUPIED" 1 "OCCUPIED" 2 "OCCUPANCY_FAULTED" 3 "OCCUPANCY_SNA" ;
VAL_ 794 VCRIGHT_rearRightBuckleStatus 0 "UNLATCHED" 1 "LATCHED" 2 "FAULTED" 3 "SNA" ;
VAL_ 794 VCRIGHT_rearCenterBuckleStatus 0 "UNLATCHED" 1 "LATCHED" 2 "FAULTED" 3 "SNA" ;
VAL_ 794 VCRIGHT_frontBuckleStatus 0 "UNLATCHED" 1 "LATCHED" 2 "FAULTED" 3 "SNA" ;
VAL_ 794 VCRIGHT_frontOccupancyStatus 0 "UNOCCUPIED" 1 "OCCUPIED" 2 "OCCUPANCY_FAULTED" 3 "NOT_CONFIGURED" 7 "OCCUPANCY_SNA" ;
VAL_ 801 VCFRONT_tempAmbientFiltered 0 "SNA" ;
VAL_ 801 VCFRONT_washerFluidLevel 0 "SNA" 1 "LOW" 2 "NORMAL" ;
VAL_ 801 VCFRONT_tempAmbient 0 "SNA" ;
VAL_ 801 VCFRONT_brakeFluidLevel 0 "SNA" 1 "LOW" 2 "NORMAL" ;
VAL_ 801 VCFRONT_coolantLevel 0 "NOT_OK" 1 "FILLED" ;
VAL_ 801 VCFRONT_tempCoolantPTInlet 2047 "SNA" ;
VAL_ 801 VCFRONT_tempCoolantBatInlet 1023 "SNA" ;
VAL_ 810 BMS_chgTimeToFull 4095 "SNA" ;
VAL_ 810 BMS_isolationResistance 1023 "SNA" ;
VAL_ 816 SCCM_infoAssemblyId 1 "ASSEMBLY1" 255 "ASSEMBLY_SNA" ;
VAL_ 816 SCCM_infoBuildType 0 "UNKNOWN_BUILD" 1 "PLATFORM_BUILD" 2 "LOCAL_BUILD" 3 "TRACEABLE_CI_BUILD" 4 "MFG_BUILD" ;
VAL_ 816 SCCM_infoIndex 10 "BUILD_HWID_COMPONENTID" 11 "PCBAID_ASSYID_USAGEID" 13 "APP_CRC" 14 "BOOTLOADER_SVN" 16 "SUBCOMPONENT1" 17 "APP_SVNHASH" 18 "BOOTLOADER_SVNHASH" 20 "UDS_PROTOCOL_BOOTCRC" 255 "END" ;
VAL_ 818 BMS_bmbMinMaxMultiplexer 0 "THERM_MUX0" 1 "VOLT_MUX1" 2 "END" ;
VAL_ 819 UI_acChargeCurrentLimit 127 "SNA" ;
VAL_ 819 UI_brickBalancingDisabled 0 "FALSE" 1 "TRUE" ;
VAL_ 819 UI_brickVLoggingRequest 0 "FALSE" 1 "TRUE" ;
VAL_ 820 UI_speedLimit 511 "SNA" ;
VAL_ 820 UI_stoppingMode 0 "STANDARD" 1 "CREEP" 2 "HOLD" ;
VAL_ 820 UI_wasteModeRegenLimit 0 "MAX" 1 "30A" 2 "10A" 3 "0A" ;
VAL_ 820 UI_wasteMode 0 "NONE" 1 "PARTIAL" 2 "FULL" 3 "BURN_IN" ;
VAL_ 820 UI_motorOnMode 0 "NORMAL" 1 "FRONT_ONLY" 2 "REAR_ONLY" ;
VAL_ 820 UI_limitMode 0 "NORMAL" 1 "VALET" 2 "FACTORY" 3 "SERVICE" ;
VAL_ 820 UI_closureConfirmed 0 "NONE" 1 "FRUNK" 2 "PROX" 3 "FALCON" ;
VAL_ 820 UI_systemTorqueLimit 63 "SNA" ;
VAL_ 820 UI_pedalMap 0 "CHILL" 1 "SPORT" 2 "PERFORMANCE" ;
VAL_ 820 UI_systemPowerLimit 31 "SNA" ;
VAL_ 821 DIR_FPGA_version 254 "LOCAL_BUILD" 255 "SNA" ;
VAL_ 821 DIR_hardwareId 252 "CONFIGURABLE_HWID_PLACEHOLDER" ;
VAL_ 821 DIR_buildType 0 "UNKNOWN_BUILD" 1 "PLATFORM_BUILD" 2 "LOCAL_BUILD" 3 "TRACEABLE_CI_BUILD" 4 "MFG_BUILD" ;
VAL_ 821 DIR_oilPumpBuildType 0 "UNKNOWN_BUILD" 1 "PLATFORM_BUILD" 2 "LOCAL_BUILD" 3 "TRACEABLE_CI_BUILD" 4 "MFG_BUILD" ;
VAL_ 821 DIR_infoIndex 0 "DEPRECATED_0" 1 "DEPRECATED_1" 2 "DEPRECATED_2" 3 "DEPRECATED_3" 4 "DEPRECATED_4" 5 "DEPRECATED_5" 6 "DEPRECATED_6" 7 "DEPRECATED_7" 8 "DEPRECATED_8" 9 "DEPRECATED_9" 10 "BUILD_HWID_COMPONENTID" 11 "PCBAID_ASSYID_USAGEID" 13 "APP_CRC" 14 "BOOTLOADER_SVN" 15 "BOOTLOADER_CRC" 16 "SUBCOMPONENT" 17 "APP_GITHASH" 18 "BOOTLOADER_GITHASH" 19 "VERSION_DEPRECATED" 20 "UDS_PROTOCOL_BOOTCRC" 23 "SUBCOMPONENT2" 31 "SUBCOMPONENT_GITHASH" 32 "SUBCOMPONENT2_GITHASH" 33 "SUBCOMPONENT_HWID" 34 "SUBCOMPONENT2_HWID" 255 "END" ;
VAL_ 825 VCSEC_remoteStartActive 0 "NONE" 1 "LEGACY" 2 "SIGNED_COMMAND" ;
VAL_ 825 VCSEC_keyChannelIndexed 15 "SNA" ;
VAL_ 825 VCSEC_simpleLockStatus 0 "SNA" 1 "UNLOCKED" 2 "LOCKED" ;
VAL_ 825 VCSEC_lockIndicationRequest 0 "NONE_SNA" 1 "SINGLE" 2 "DOUBLE" 3 "TRIPLE" 4 "HOLD" ;
VAL_ 825 VCSEC_immobilizerState 0 "IDLE" 1 "PREPARE" 2 "ENCRYPT_BEGIN" 3 "ENCRYPT" 4 "SEND_AUTH_RESPONSE" 5 "SEND_NO_GO_AUTH_RESPONSE" ;
VAL_ 825 VCSEC_alarmStatus 0 "DISARMED" 1 "ARMED" 2 "PARTIAL_ARMED" 3 "TRIGGERED_FLASH_ACTIVE" 4 "ERROR" 5 "TRIGGERED_FLASH_INACTIVE" 6 "IMMINENT" 7 "DEFAULT" 15 "SNA" ;
VAL_ 825 VCSEC_MCUCommandType 0 "NONE" 1 "REMOTE_UNLOCK" 2 "REMOTE_START" 3 "COMMAND3" 4 "COMMAND4" 5 "COMMAND5" ;
VAL_ 825 VCSEC_summonRequest 0 "IDLE" 1 "PRIME" 2 "FORWARD" 3 "BACKWARD" 4 "STOP" 5 "SNA" ;
VAL_ 825 VCSEC_lockRequestType 0 "NONE" 1 "PASSIVE_SHIFT_TO_P_UNLOCK" 2 "PASSIVE_PARKBUTTON_UNLOCK" 3 "PASSIVE_INTERNAL_HANDLE_UNLOCK" 4 "PASSIVE_DRIVE_AWAY_LOCK" 5 "PASSIVE_BLE_WALKUP_UNLOCK" 6 "PASSIVE_BLE_EXTERIOR_CHARGEHANDLEBUTTON_UNLOCK" 7 "PASSIVE_BLE_EXTERIOR_HANDLE_UNLOCK" 8 "PASSIVE_BLE_INTERIOR_HANDLE_UNLOCK" 9 "PASSIVE_BLE_LOCK" 10 "CRASH_UNLOCK" 11 "ACTIVE_UI_BUTTON_UNLOCK" 12 "ACTIVE_UI_BUTTON_LOCK" 13 "ACTIVE_REMOTE_UNLOCK" 14 "ACTIVE_REMOTE_LOCK" 15 "ACTIVE_NFC_UNLOCK" 16 "ACTIVE_NFC_LOCK" 17 "ACTIVE_BLE_UNLOCK" 18 "ACTIVE_BLE_LOCK" 19 "PASSIVE_INTERNAL_LOCK_PROMOTION" 20 "PASSIVE_AUTO_PRESENT_DOOR_REQUEST" 21 "KEYFOB_OPEN_DOOR_REQUEST" ;
VAL_ 825 VCSEC_trunkLockStatus 0 "UNLOCKED" 1 "LOCKED" ;
VAL_ 825 VCSEC_rightRearLockStatus 0 "UNLOCKED" 1 "LOCKED" ;
VAL_ 825 VCSEC_rightFrontLockStatus 0 "UNLOCKED" 1 "LOCKED" ;
VAL_ 825 VCSEC_leftRearLockStatus 0 "UNLOCKED" 1 "LOCKED" ;
VAL_ 825 VCSEC_leftFrontLockStatus 0 "UNLOCKED" 1 "LOCKED" ;
VAL_ 825 VCSEC_chargePortLockStatus 0 "UNLOCKED" 1 "LOCKED" ;
VAL_ 825 VCSEC_authenticationStatus 0 "NONE" 1 "AUTHENTICATED_FOR_UNLOCK" 2 "AUTHENTICATED_FOR_DRIVE" ;
VAL_ 825 VCSEC_vehicleLockStatus 0 "SNA" 1 "ACTIVE_NFC_UNLOCKED" 2 "ACTIVE_NFC_LOCKED" 3 "PASSIVE_SELECTIVE_UNLOCKED" 4 "PASSIVE_BLE_UNLOCKED" 5 "PASSIVE_BLE_LOCKED" 6 "ACTIVE_SELECTIVE_UNLOCKED" 7 "ACTIVE_BLE_UNLOCKED" 8 "ACTIVE_BLE_LOCKED" 9 "ACTIVE_UI_UNLOCKED" 10 "ACTIVE_UI_LOCKED" 11 "ACTIVE_REMOTE_UNLOCKED" 12 "ACTIVE_REMOTE_LOCKED" 13 "CRASH_UNLOCKED" 14 "PASSIVE_INTERNAL_UNLOCKED" 15 "PASSIVE_INTERNAL_LOCKED" ;
VAL_ 835 VCRIGHT_mirrorHeatState 0 "SNA" 1 "ON" 2 "OFF" 3 "OFF_UNAVAILABLE" 4 "FAULT" ;
VAL_ 840 GTW_sentryModeState 0 "OFF" 1 "IDLE" 2 "ARMED" 3 "AWARE" 4 "PANIC" 5 "QUIET" 6 "SNA" ;
VAL_ 840 GTW_hwtype 0 "SNA" 1 "MPC57" 2 "SPC58" ;
VAL_ 840 GTW_vehicleVersionMatchStatus 0 "NOT_CALCULATED_YET" 1 "MISMATCHED" 2 "MATCHED" ;
VAL_ 850 BMS_idealEnergyRemaining 2047 "SNA" ;
VAL_ 850 BMS_energyToChargeComplete 2047 "SNA" ;
VAL_ 850 BMS_nominalEnergyRemaining 2047 "SNA" ;
VAL_ 850 BMS_expectedEnergyRemaining 2047 "SNA" ;
VAL_ 850 BMS_nominalFullPackEnergy 2047 "SNA" ;
VAL_ 850 BMS_energyBuffer 255 "SNA" ;
VAL_ 851 UI_trailerModeTelltale 0 "OFF" 1 "BLUE" 2 "YELLOW" 3 "RED" ;
VAL_ 851 UI_cellSignalBars 0 "ZERO" 1 "ONE" 2 "TWO" 3 "THREE" 4 "FOUR" 5 "FIVE" 7 "SNA" ;
VAL_ 851 UI_cellNetworkTechnology 0 "NONE" 1 "GPRS" 2 "EDGE" 3 "UMTS" 4 "HSDPA" 5 "HSUPA" 6 "HSPA" 7 "LTE" 8 "GSM" 9 "CDMA" 10 "WCDMA" 15 "SNA" ;
VAL_ 851 UI_factoryReset 0 "NONE_SNA" 1 "DEVELOPER" 2 "DIAGNOSTIC" 3 "CUSTOMER" ;
VAL_ 851 UI_autopilotTrial 0 "NONE" 1 "START" 2 "STOP" 3 "ACTIVE" ;
VAL_ 866 VCLEFT_crashState 0 "IDLE" 1 "MINOR_1" 2 "MINOR_2" 3 "SEVERE" ;
VAL_ 866 VCLEFT_crashDetectedType 0 "NONE" 1 "MINOR_1" 2 "MINOR_2" 3 "SEVERE" ;
VAL_ 870 CMPD_infoAssemblyId 1 "ASSEMBLY1" 255 "ASSEMBLY_SNA" ;
VAL_ 870 CMPD_infoBuildType 0 "UNKNOWN_BUILD" 1 "PLATFORM_BUILD" 2 "LOCAL_BUILD" 3 "TRACEABLE_CI_BUILD" 4 "MFG_BUILD" ;
VAL_ 870 CMPD_infoIndex 0 "DEPRECATED_0" 1 "DEPRECATED_1" 2 "DEPRECATED_2" 3 "DEPRECATED_3" 4 "DEPRECATED_4" 5 "DEPRECATED_5" 6 "DEPRECATED_6" 7 "DEPRECATED_7" 8 "DEPRECATED_8" 9 "DEPRECATED_9" 10 "BUILD_HWID_COMPONENTID" 11 "PCBAID_ASSYID_USAGEID" 13 "APP_CRC" 14 "BOOTLOADER_SVN" 15 "BOOTLOADER_CRC" 16 "SUBCOMPONENT" 17 "APP_GITHASH" 18 "BOOTLOADER_GITHASH" 19 "VERSION_DEPRECATED" 20 "UDS_PROTOCOL_BOOTCRC" 22 "VARIANTCRC" 25 "PACKAGE_PN_1_7" 26 "PACKAGE_PN_8_14" 27 "PACKAGE_PN_15_20" 29 "PACKAGE_SN_1_7" 30 "PACKAGE_SN_8_14" 31 "SUBCOMPONENT_GITHASH" 255 "END" ;
VAL_ 883 UI_conditionalSpeedLimit 31 "SNA" ;
VAL_ 883 UI_userSpeedOffsetUnits 0 "MPH" 1 "KPH" ;
VAL_ 883 UI_mapSpeedLimitUnits 0 "MPH" 1 "KPH" ;
VAL_ 893 CP_thermalStatusSelect 0 "0" 1 "1" ;
VAL_ 899 VCRIGHT_estimatedThsSolarLoad 1023 "SNA" ;
VAL_ 899 VCRIGHT_thsSolarLoadVisible 1023 "SNA" ;
VAL_ 899 VCRIGHT_thsSolarLoadInfrared 1023 "SNA" ;
VAL_ 899 VCRIGHT_thsHumidity 255 "SNA" ;
VAL_ 899 VCRIGHT_thsTemperature -128 "SNA" ;
VAL_ 914 BMS_beginningOfLifePackEnergy 1023 "SNA" ;
VAL_ 914 BMS_moduleType 0 "UNKNOWN" 1 "E3_NCT" 2 "E1_NCT" 3 "E3_CT" 4 "E1_CT" 5 "E1_CP" ;
VAL_ 914 BMS_reservedConfig_0 0 "0" 1 "1" 2 "2" 3 "3" 4 "4" 5 "5" 6 "6" 7 "7" 8 "8" 9 "9" 10 "10" 11 "11" 12 "12" 13 "13" 14 "14" 15 "15" 16 "16" 17 "17" 18 "18" 19 "19" 20 "20" 21 "21" 22 "22" 23 "23" 24 "24" 25 "25" 26 "26" 27 "27" 28 "28" 29 "29" 30 "30" 31 "31" ;
VAL_ 914 BMS_packConfigMultiplexer 0 "Mux0" 1 "Mux1" ;
VAL_ 915 VCRIGHT_epbmSystemStatus 0 "UNKNOWN" 1 "RELEASED" 2 "PARKED" 3 "DYNAMIC" 4 "PARKING" 5 "RELEASING" 6 "FAULT" 7 "FAULT_SECURE" 8 "MISMATCH" ;
VAL_ 915 VCRIGHT_epbFaultStatus 0 "NOMINAL" 1 "RETRY" 2 "FAULT" 3 "FAULT_IDLE" ;
VAL_ 915 VCRIGHT_epbmFaultStatus 0 "NOMINAL" 1 "RETRY" 2 "FAULT" 3 "FAULT_IDLE" ;
VAL_ 915 VCRIGHT_epbUnitStatus 0 "UNKNOWN" 1 "OPEN" 2 "DYNAMIC" 3 "PARK" 4 "START" 5 "SERVICE" 6 "WINCHMODE" 7 "WINCHMODE_RELEASING" 8 "PARKING" 9 "DYNAMIC_APPLYING" 10 "RELEASING" 11 "SERVICE_RELEASING" 12 "PARK_PENDING" 13 "WINCHMODE_PENDING" 14 "SUMMON" 15 "SUMMON_RELEASING" 16 "SUMMON_PARKING" 17 "EXTERNAL_DYNAMIC" 18 "RELEASING_FOR_EXTERNAL_PARK" 19 "EXTERNAL_PARKING" 20 "DYNAMIC_PARKING" 21 "FREE_ROLL_MODE" 22 "COUNT" ;
VAL_ 915 VCRIGHT_epbmSummonState 0 "INIT" 1 "IDLE" 2 "ARMED" 3 "ACTIVE" 4 "COMPLETE" 5 "FAULT" 6 "UNAVAILABLE" ;
VAL_ 915 VCRIGHT_epbSummonState 0 "INIT" 1 "IDLE" 2 "ARMED" 3 "ACTIVE" 4 "COMPLETE" 5 "FAULT" 6 "UNAVAILABLE" ;
VAL_ 915 VCRIGHT_summonFaultReason 0 "NONE" 1 "DI_MIA" 2 "DAS_MIA" 3 "ESP_MIA" 4 "EPBM_MIA" 5 "DI_FAULT" 6 "DI_APC_FAULT" 7 "DAS_FAULT" 8 "ESP_FAULT" 9 "VEH_CAN_FAULT" 10 "EAC_NOT_ALLOWED" 11 "EPBM_REQUEST" 12 "SPEED" 13 "EXTERNAL" 14 "PARK_MIA" 15 "PM_MIA" 16 "PM_REQUEST" 17 "OOC" 18 "MISMATCH" 19 "EPB_FAULT" 20 "DI_STATE_INVALID" 21 "PASSIVE_REQUEST" 22 "EPBREMOTE_MIA" 23 "REMOTE_SUMMON_FAULTED" 24 "LOCAL_UNIT_FAULTED" 25 "REMOTE_UNIT_FAULTED" 26 "START_IN_UNAVAILABLE" 27 "INVALID_REMOTE_STATE" 28 "REMOTE_DID_NOT_START" ;
VAL_ 915 VCRIGHT_epbmCaliperState 0 "UNSAVED" 1 "UNKNOWN" 2 "REAPPLY" 3 "PARK" 4 "OPEN" 5 "SERVICE" 6 "WINCHMODE" ;
VAL_ 915 VCRIGHT_epbmDebugIndex 0 "STATES" 1 "TRANSITIONS" ;
VAL_ 917 DIR_oilPumpPressureResidual 255 "SNA" ;
VAL_ 917 DIR_oilPumpPressureExpected 255 "SNA" ;
VAL_ 917 DIR_oilPumpPressureEstimate 255 "SNA" ;
VAL_ 917 DIR_oilPumpPhaseCurrent 255 "SNA" ;
VAL_ 917 DIR_oilPumpFluidT 255 "SNA" ;
VAL_ 917 DIR_oilPumpFlowActual 255 "SNA" ;
VAL_ 917 DIR_oilPumpFlowTarget 255 "SNA" ;
VAL_ 917 DIR_oilPumpFluidTQF 0 "LOW_CONFIDENCE" 1 "HIGH_CONFIDENCE" ;
VAL_ 917 DIR_oilPumpState 0 "STANDBY" 1 "ENABLE" 2 "COLD_STARTUP" 6 "FAULTED" 7 "SNA" ;
VAL_ 921 VCSEC_crashState 0 "IDLE" 1 "MINOR_1" 2 "MINOR_2" 3 "SEVERE" ;
VAL_ 921 VCSEC_crashDetectedType 0 "NONE" 1 "MINOR_1" 2 "MINOR_2" 3 "SEVERE" ;
VAL_ 922 VCSEC_RSSI2ConnectionType 0 "NONE" 1 "PERIPHERAL" 2 "CENTRAL" ;
VAL_ 922 VCSEC_RSSI1ConnectionType 0 "NONE" 1 "PERIPHERAL" 2 "CENTRAL" ;
VAL_ 922 VCSEC_RSSI0ConnectionType 0 "NONE" 1 "PERIPHERAL" 2 "CENTRAL" ;
VAL_ 923 DAS_autoLaneChangeState 0 "UNAVAILABLE_DISABLED" 1 "UNAVAILABLE_NO_LANES" 2 "UNAVAILABLE_SONICS_INVALID" 3 "UNAVAILABLE_TP_FOLLOW" 4 "UNAVAILABLE_EXITING_HIGHWAY" 5 "UNAVAILABLE_VEHICLE_SPEED" 6 "AVAILABLE_ONLY_L" 7 "AVAILABLE_ONLY_R" 8 "AVAILABLE_BOTH" 9 "IN_PROGRESS_L" 10 "IN_PROGRESS_R" 11 "WAITING_FOR_SIDE_OBST_TO_PASS_L" 12 "WAITING_FOR_SIDE_OBST_TO_PASS_R" 13 "WAITING_FOR_FWD_OBST_TO_PASS_L" 14 "WAITING_FOR_FWD_OBST_TO_PASS_R" 15 "ABORT_SIDE_OBSTACLE_PRESENT_L" 16 "ABORT_SIDE_OBSTACLE_PRESENT_R" 17 "ABORT_POOR_VIEW_RANGE" 18 "ABORT_LC_HEALTH_BAD" 19 "ABORT_BLINKER_TURNED_OFF" 20 "ABORT_OTHER_REASON" 21 "UNAVAILABLE_SOLID_LANE_LINE" 22 "BLOCKED_VEH_TTC_L" 23 "BLOCKED_VEH_TTC_AND_USS_L" 24 "BLOCKED_VEH_TTC_R" 25 "BLOCKED_VEH_TTC_AND_USS_R" 26 "BLOCKED_LANE_TYPE_L" 27 "BLOCKED_LANE_TYPE_R" 28 "WAITING_HANDS_ON" 29 "ABORT_TIMEOUT" 30 "ABORT_MISSION_PLAN_INVALID" 31 "SNA" ;
VAL_ 923 DAS_autopilotHandsOnState 0 "NOT_REQD" 1 "REQD_DETECTED" 2 "REQD_NOT_DETECTED" 3 "REQD_VISUAL" 4 "REQD_CHIME_1" 5 "REQD_CHIME_2" 6 "REQD_SLOWING" 7 "REQD_STRUCK_OUT" 8 "SUSPENDED" 9 "REQD_ESCALATED_CHIME_1" 10 "REQD_ESCALATED_CHIME_2" 15 "SNA" ;
VAL_ 923 DAS_fleetSpeedState 0 "UNAVAILABLE" 1 "AVAILABLE" 2 "ACTIVE" 3 "HOLD" ;
VAL_ 923 DAS_laneDepartureWarning 0 "NONE" 1 "LEFT_WARNING" 2 "RIGHT_WARNING" 3 "LEFT_WARNING_SEVERE" 4 "RIGHT_WARNING_SEVERE" 5 "SNA" ;
VAL_ 923 DAS_sideCollisionInhibit 0 "NO_INHIBIT" 1 "INHIBIT" ;
VAL_ 923 DAS_sideCollisionWarning 0 "NONE" 1 "WARN_LEFT" 2 "WARN_RIGHT" 3 "WARN_LEFT_RIGHT" ;
VAL_ 923 DAS_sideCollisionAvoid 0 "NONE" 1 "AVOID_LEFT" 2 "AVOID_RIGHT" 3 "SNA" ;
VAL_ 923 DAS_lssState 0 "FAULT" 1 "LDW" 2 "LKA" 3 "ELK" 4 "MONITOR" 5 "BLINDSPOT" 6 "ABORT" 7 "OFF" ;
VAL_ 923 DAS_autoparkReady 0 "UNAVAILABLE" 1 "READY" ;
VAL_ 923 DAS_forwardCollisionWarning 0 "NONE" 1 "FORWARD_COLLISION_WARNING" 3 "SNA" ;
VAL_ 923 DAS_heaterState 0 "OFF_SNA" 1 "ON" ;
VAL_ 923 DAS_visionOnlySpeedLimit 0 "UNKNOWN_SNA" 31 "NONE" ;
VAL_ 923 DAS_suppressSpeedWarning 0 "Do_Not_Suppress" 1 "Suppress_Speed_Warning" ;
VAL_ 923 DAS_fusedSpeedLimit 0 "UNKNOWN_SNA" 31 "NONE" ;
VAL_ 923 DAS_blindSpotRearRight 0 "NO_WARNING" 1 "WARNING_LEVEL_1" 2 "WARNING_LEVEL_2" 3 "SNA" ;
VAL_ 923 DAS_blindSpotRearLeft 0 "NO_WARNING" 1 "WARNING_LEVEL_1" 2 "WARNING_LEVEL_2" 3 "SNA" ;
VAL_ 923 DAS_autopilotState 0 "DISABLED" 1 "UNAVAILABLE" 2 "AVAILABLE" 3 "ACTIVE_NOMINAL" 4 "ACTIVE_RESTRICTED" 5 "ACTIVE_NAV" 6 "ACTIVE_FSD" 8 "ABORTING" 9 "ABORTED" 14 "FAULT" 15 "SNA" ;
VAL_ 925 IBST_internalState 0 "NO_MODE_ACTIVE" 1 "PRE_DRIVE_CHECK" 2 "LOCAL_BRAKE_REQUEST" 3 "EXTERNAL_BRAKE_REQUEST" 4 "DIAGNOSTIC" 5 "TRANSITION_TO_IDLE" 6 "POST_DRIVE_CHECK" ;
VAL_ 925 IBST_driverBrakeApply 0 "NOT_INIT_OR_OFF" 1 "BRAKES_NOT_APPLIED" 2 "DRIVER_APPLYING_BRAKES" 3 "FAULT" ;
VAL_ 925 IBST_iBoosterStatus 0 "OFF" 1 "INIT" 2 "FAILURE" 3 "DIAGNOSTIC" 4 "ACTIVE_GOOD_CHECK" 5 "READY" 6 "ACTUATION" ;
VAL_ 929 VCFRONT_pcsEFuseVoltage 1023 "SNA" ;
VAL_ 929 VCFRONT_2RowRightUnbuckled 0 "NONE" 1 "OCCUPIED_AND_UNBUCKLED" 2 "SNA" ;
VAL_ 929 VCFRONT_2RowCenterUnbuckled 0 "NONE" 1 "OCCUPIED_AND_UNBUCKLED" 2 "SNA" ;
VAL_ 929 VCFRONT_2RowLeftUnbuckled 0 "NONE" 1 "OCCUPIED_AND_UNBUCKLED" 2 "SNA" ;
VAL_ 929 VCFRONT_passengerUnbuckled 0 "NONE" 1 "OCCUPIED_AND_UNBUCKLED" 2 "SNA" ;
VAL_ 929 VCFRONT_driverUnbuckled 0 "NONE" 1 "OCCUPIED_AND_UNBUCKLED" 2 "SNA" ;
VAL_ 929 VCFRONT_driverDoorStatus 0 "OPEN" 1 "CLOSED" ;
VAL_ 929 VCFRONT_driverBuckleStatus 0 "UNBUCKLED" 1 "BUCKLED" ;
VAL_ 929 VCFRONT_12vStatusForDrive 0 "NOT_READY_FOR_DRIVE_12V" 1 "READY_FOR_DRIVE_12V" 2 "EXIT_DRIVE_REQUESTED_12V" ;
VAL_ 929 VCFRONT_diPowerOnState 0 "POWERED_OFF" 1 "POWERED_ON_FOR_SUMMON" 2 "POWERED_ON_FOR_STATIONARY_HEAT" 3 "POWERED_ON_FOR_DRIVE" 4 "POWER_GOING_DOWN" 5 "POWERED_ON_FOR_WINCH" ;
VAL_ 929 VCFRONT_thermalSystemType 0 "LEGACY_THERMAL_SYSTEM" 1 "HEAT_PUMP_THERMAL_SYSTEM" ;
VAL_ 929 VCFRONT_3RowRightUnbuckled 0 "NONE" 1 "OCCUPIED_AND_UNBUCKLED" 2 "SNA" ;
VAL_ 929 VCFRONT_3RowLeftUnbuckled 0 "NONE" 1 "OCCUPIED_AND_UNBUCKLED" 2 "SNA" ;
VAL_ 929 VCFRONT_APGlassHeaterState 0 "SNA" 1 "ON" 2 "OFF" 3 "OFF_UNAVAILABLE" 4 "FAULT" ;
VAL_ 929 VCFRONT_vehicleStatusMuxIndex 0 "MUX0" 1 "MUX1" ;
VAL_ 930 VCLEFT_swcPCBATemperature 4294967168 "SNA" ;
VAL_ 930 VCLEFT_swcHeatStatus 0 "SNA" 1 "ON" 2 "OFF" 3 "OFF_UNAVAILABLE" 4 "FAULT" ;
VAL_ 930 VCLEFT_swcInputVoltage 255 "SNA" ;
VAL_ 930 VCLEFT_swcHeatTmp 4294967168 "SNA" ;
VAL_ 930 VCLEFT_trailerAuxCurrent 4095 "SNA" ;
VAL_ 930 VCLEFT_statusIndex 0 "MUX0" 1 "MUX1" ;
VAL_ 936 VCLEFT_logging1HzIndex 0 "HVAC_ACTUATOR_VOLTAGES" 1 "HVAC_ACTUATOR_ENDSTOP" 2 "HVAC_ACTUATOR_ZEROSTOP" 3 "HVAC_ACTUATOR_OPERATION_MODE" 4 "END" ;
VAL_ 941 ICR_infoAssemblyId 1 "ASSEMBLY1" 255 "ASSEMBLY_SNA" ;
VAL_ 941 ICR_infoBuildType 0 "UNKNOWN_BUILD" 1 "PLATFORM_BUILD" 2 "LOCAL_BUILD" 3 "TRACEABLE_CI_BUILD" 4 "MFG_BUILD" ;
VAL_ 941 ICR_infoIndex 0 "DEPRECATED_0" 1 "DEPRECATED_1" 2 "DEPRECATED_2" 3 "DEPRECATED_3" 4 "DEPRECATED_4" 5 "DEPRECATED_5" 6 "DEPRECATED_6" 7 "DEPRECATED_7" 8 "DEPRECATED_8" 9 "DEPRECATED_9" 10 "BUILD_HWID_COMPONENTID" 11 "PCBAID_ASSYID_USAGEID" 13 "APP_CRC" 14 "BOOTLOADER_SVN" 15 "BOOTLOADER_CRC" 16 "SUBCOMPONENT" 17 "APP_GITHASH" 18 "BOOTLOADER_GITHASH" 19 "VERSION_DEPRECATED" 20 "UDS_PROTOCOL_BOOTCRC" 22 "VARIANTCRC" 25 "PACKAGE_PN_1_7" 26 "PACKAGE_PN_8_14" 27 "PACKAGE_PN_15_20" 29 "PACKAGE_SN_1_7" 30 "PACKAGE_SN_8_14" 31 "SUBCOMPONENT_GITHASH" 255 "END" ;
VAL_ 942 APP_summonState 0 "INIT" 1 "IDLE" 2 "ARMED" 3 "ACTIVE" 4 "COMPLETE" 5 "FAULT" 6 "UNAVAILABLE" ;
VAL_ 947 UI_dcr12VThreshold 0 "OFF" 1 "40_MILLIOHMS" 2 "35_MILLIOHMS" 3 "30_MILLIOHMS" 4 "27_MILLIOHMS" 5 "24_MILLIOHMS" 6 "22_MILLIOHMS" 7 "20_MILLIOHMS" ;
VAL_ 947 UI_shorted12VCellTestMode 0 "DISABLED" 1 "SHADOW" 2 "ACTIVE" ;
VAL_ 947 UI_autopilotPowerStateRequest 0 "NOMINAL" 1 "SENTRY" 2 "SUSPEND" ;
VAL_ 947 UI_summonState 0 "SNA" 1 "IDLE" 2 "PRE_PRIMED" 3 "ACTIVE" ;
VAL_ 947 UI_lightSwitch 0 "AUTO" 1 "ON" 2 "PARKING" 3 "OFF" 4 "SNA" ;
VAL_ 947 UI_trunkRequest 0 "NONE" 1 "MOVE" 2 "STOP" 3 "SNA" ;
VAL_ 950 DI_odometer 4294967295 "SNA" ;
VAL_ 957 VCFRONT_energyLossIndex 0 "STATUS" 1 "SINCE_LAST_DRIVE" 2 "SINCE_LAST_DRIVE2" 3 "SINCE_LAST_CHARGE" 4 "SINCE_LAST_CHARGE2" ;
VAL_ 962 VCLEFT_rearRightOccupancySwitch 0 "SNA" 1 "OFF" 2 "ON" 3 "FAULT" ;
VAL_ 962 VCLEFT_rearLeftOccupancySwitch 0 "SNA" 1 "OFF" 2 "ON" 3 "FAULT" ;
VAL_ 962 VCLEFT_rearCenterOccupancySwitch 0 "SNA" 1 "OFF" 2 "ON" 3 "FAULT" ;
VAL_ 962 VCLEFT_rearLeftBuckleSwitch 0 "SNA" 1 "OFF" 2 "ON" 3 "FAULT" ;
VAL_ 962 VCLEFT_frontOccupancySwitch 0 "SNA" 1 "OFF" 2 "ON" 3 "FAULT" ;
VAL_ 962 VCLEFT_frontBuckleSwitch 0 "SNA" 1 "OFF" 2 "ON" 3 "FAULT" ;
VAL_ 962 VCLEFT_frontSeatLumbarOut 0 "SNA" 1 "OFF" 2 "ON" 3 "FAULT" ;
VAL_ 962 VCLEFT_frontSeatLumbarIn 0 "SNA" 1 "OFF" 2 "ON" 3 "FAULT" ;
VAL_ 962 VCLEFT_frontSeatLumbarUp 0 "SNA" 1 "OFF" 2 "ON" 3 "FAULT" ;
VAL_ 962 VCLEFT_frontSeatLumbarDown 0 "SNA" 1 "OFF" 2 "ON" 3 "FAULT" ;
VAL_ 962 VCLEFT_frontSeatBackrestForward 0 "SNA" 1 "OFF" 2 "ON" 3 "FAULT" ;
VAL_ 962 VCLEFT_frontSeatBackrestBack 0 "SNA" 1 "OFF" 2 "ON" 3 "FAULT" ;
VAL_ 962 VCLEFT_frontSeatLiftUp 0 "SNA" 1 "OFF" 2 "ON" 3 "FAULT" ;
VAL_ 962 VCLEFT_frontSeatLiftDown 0 "SNA" 1 "OFF" 2 "ON" 3 "FAULT" ;
VAL_ 962 VCLEFT_frontSeatTiltUp 0 "SNA" 1 "OFF" 2 "ON" 3 "FAULT" ;
VAL_ 962 VCLEFT_swcLeftTiltLeft 0 "SNA" 1 "OFF" 2 "ON" 3 "FAULT" ;
VAL_ 962 VCLEFT_frontSeatTiltDown 0 "SNA" 1 "OFF" 2 "ON" 3 "FAULT" ;
VAL_ 962 VCLEFT_swcRightPressed 0 "SNA" 1 "OFF" 2 "ON" 3 "FAULT" ;
VAL_ 962 VCLEFT_frontSeatTrackForward 0 "SNA" 1 "OFF" 2 "ON" 3 "FAULT" ;
VAL_ 962 VCLEFT_swcRightTiltRight 0 "SNA" 1 "OFF" 2 "ON" 3 "FAULT" ;
VAL_ 962 VCLEFT_frontSeatTrackBack 0 "SNA" 1 "OFF" 2 "ON" 3 "FAULT" ;
VAL_ 962 VCLEFT_swcRightTiltLeft 0 "SNA" 1 "OFF" 2 "ON" 3 "FAULT" ;
VAL_ 962 VCLEFT_rightMirrorTilt 0 "STOP" 1 "DOWN" 2 "UP" 3 "RIGHT" 4 "LEFT" ;
VAL_ 962 VCLEFT_swcLeftPressed 0 "SNA" 1 "OFF" 2 "ON" 3 "FAULT" ;
VAL_ 962 VCLEFT_swcLeftTiltRight 0 "SNA" 1 "OFF" 2 "ON" 3 "FAULT" ;
VAL_ 962 VCLEFT_switchStatusIndex 0 "0" 1 "1" 2 "INVALID" ;
VAL_ 963 VCRIGHT_rearRightOccupancySwitch 0 "SNA" 1 "OFF" 2 "ON" 3 "FAULT" ;
VAL_ 963 VCRIGHT_rearCenterBuckleSwitch 0 "SNA" 1 "OFF" 2 "ON" 3 "FAULT" ;
VAL_ 963 VCRIGHT_frontOccupancySwitch 0 "SNA" 1 "OFF" 2 "ON" 3 "FAULT" ;
VAL_ 963 VCRIGHT_frontBuckleSwitch 0 "SNA" 1 "OFF" 2 "ON" 3 "FAULT" ;
VAL_ 963 VCRIGHT_frontSeatLumbarOut 0 "SNA" 1 "OFF" 2 "ON" 3 "FAULT" ;
VAL_ 963 VCRIGHT_frontSeatLumbarIn 0 "SNA" 1 "OFF" 2 "ON" 3 "FAULT" ;
VAL_ 963 VCRIGHT_frontSeatLumbarUp 0 "SNA" 1 "OFF" 2 "ON" 3 "FAULT" ;
VAL_ 963 VCRIGHT_frontSeatLumbarDown 0 "SNA" 1 "OFF" 2 "ON" 3 "FAULT" ;
VAL_ 963 VCRIGHT_frontSeatBackrestForward 0 "SNA" 1 "OFF" 2 "ON" 3 "FAULT" ;
VAL_ 963 VCRIGHT_frontSeatBackrestBack 0 "SNA" 1 "OFF" 2 "ON" 3 "FAULT" ;
VAL_ 963 VCRIGHT_frontSeatLiftUp 0 "SNA" 1 "OFF" 2 "ON" 3 "FAULT" ;
VAL_ 963 VCRIGHT_frontSeatLiftDown 0 "SNA" 1 "OFF" 2 "ON" 3 "FAULT" ;
VAL_ 963 VCRIGHT_frontSeatTiltUp 0 "SNA" 1 "OFF" 2 "ON" 3 "FAULT" ;
VAL_ 963 VCRIGHT_frontSeatTiltDown 0 "SNA" 1 "OFF" 2 "ON" 3 "FAULT" ;
VAL_ 963 VCRIGHT_frontSeatTrackForward 0 "SNA" 1 "OFF" 2 "ON" 3 "FAULT" ;
VAL_ 963 VCRIGHT_frontSeatTrackBack 0 "SNA" 1 "OFF" 2 "ON" 3 "FAULT" ;
VAL_ 963 VCRIGHT_switchStatusIndex 0 "0" 1 "1" 2 "INVALID" ;
VAL_ 964 PCS_hardwareId 252 "CONFIGURABLE_HWID_PLACEHOLDER" ;
VAL_ 964 PCS_buildType 0 "UNKNOWN_BUILD" 1 "PLATFORM_BUILD" 2 "LOCAL_BUILD" 3 "TRACEABLE_CI_BUILD" 4 "MFG_BUILD" ;
VAL_ 964 PCS_platformType 0 "UNKNOWN" 3 "MODEL3" 255 "END" ;
VAL_ 964 PCS_infoIndex 0 "DEPRECATED_0" 1 "DEPRECATED_1" 2 "DEPRECATED_2" 3 "DEPRECATED_3" 4 "DEPRECATED_4" 5 "DEPRECATED_5" 6 "DEPRECATED_6" 7 "DEPRECATED_7" 8 "DEPRECATED_8" 9 "DEPRECATED_9" 10 "BUILD_HWID_COMPONENTID" 11 "PCBAID_ASSYID_USAGEID" 13 "APP_CRC" 14 "BOOTLOADER_SVN" 15 "BOOTLOADER_CRC" 16 "SUBCOMPONENT" 17 "APP_GITHASH" 18 "BOOTLOADER_GITHASH" 19 "VERSION_DEPRECATED" 20 "UDS_PROTOCOL_BOOTCRC" 22 "VARIANTCRC" 25 "PACKAGE_PN_1_7" 26 "PACKAGE_PN_8_14" 27 "PACKAGE_PN_15_20" 29 "PACKAGE_SN_1_7" 30 "PACKAGE_SN_8_14" 31 "SUBCOMPONENT_GITHASH" 255 "END" ;
VAL_ 969 VCSEC_BLEEndpointInfoIndex 0 "BLELeftInfo" 1 "BLERightInfo" 2 "BLERearInfo" 3 "BLECenterInfo" 4 "BLELeftAppGithash" 5 "BLERightAppGithash" 6 "BLERearAppGithash" 7 "BLECenterAppGithash" 8 "BLEFrontInfo" 9 "BLESecondaryInfo" 10 "BLENFCCradleInfo" 11 "BLELeftRearInfo" 12 "BLERightRearInfo" 13 "BLEFrontAppGithash" 14 "BLESecondaryAppGithash" 15 "BLENFCCradleAppGithash" 16 "BLELeftRearAppGithash" 17 "BLERightRearAppGithash" 18 "UWBLeftInfo" 19 "UWBRightInfo" 20 "UWBRearLeftInfo" 21 "UWBRearRightInfo" 22 "UWBFrontInfo" 23 "UWBLeftAppGithash" 24 "UWBRightAppGithash" 25 "UWBRearLeftAppGithash" 26 "UWBRearRightAppGithash" 27 "UWBFrontAppGithash" ;
VAL_ 972 APS_arbState 0 "INIT" 1 "IDLE" 2 "PRIMARY" 3 "SECONDARY" 4 "FAULT" 5 "MIA" 6 "UNKNOWN" 7 "COUNT" ;
VAL_ 972 APS_heaterStateDebug 0 "OFF" 1 "ON_HEATING" 2 "ON_NOT_HEATING" 3 "FAULT_OPEN" 4 "FAULT_SHORT" 7 "SNA" ;
VAL_ 972 APS_apbPowerStateReason 0 "UI_POWER_STATE_REQUEST" 1 "AP_WDOG_UNHEALTHY" 2 "AP_NM_REASON_SET" 3 "AP_NOT_IN_PARK" 4 "GTW_GOTO_FULL_POWER" 5 "AP_POWER_REQUEST_HYSTERESIS" 6 "AP_POWER_REQUEST_OVERHEATING" 7 "AP_POWER_REQUEST_OVERRIDE" 8 "VC_POWER_REQUEST" 9 "LOADSHED_POWER_REQUEST_PENDING" ;
VAL_ 972 APS_apbPowerStateRequest 0 "NOMINAL" 1 "SENTRY" 2 "SUSPEND" 3 "SLEEP" ;
VAL_ 972 APS_appPowerStateReason 0 "UI_POWER_STATE_REQUEST" 1 "AP_WDOG_UNHEALTHY" 2 "AP_NM_REASON_SET" 3 "AP_NOT_IN_PARK" 4 "GTW_GOTO_FULL_POWER" 5 "AP_POWER_REQUEST_HYSTERESIS" 6 "AP_POWER_REQUEST_OVERHEATING" 7 "AP_POWER_REQUEST_OVERRIDE" 8 "VC_POWER_REQUEST" 9 "LOADSHED_POWER_REQUEST_PENDING" ;
VAL_ 972 APS_appPowerStateRequest 0 "NOMINAL" 1 "SENTRY" 2 "SUSPEND" 3 "SLEEP" ;
VAL_ 972 APS_locLimitReason 0 "NOMINAL_DEFAULT" 1 "NOT_IN_DRIVE" 2 "ACC_AND_AEB_UNAVAILABLE" 3 "PRIMARY_AP_NOT_HEALTHY" 4 "RADAR_NOT_HEALTHY" 5 "NO_RADAR_TARGET" 6 "LOC_MONITOR_UNAVAILABLE" 7 "LOC_LIMITS_EXTENDED" ;
VAL_ 972 APS_apbGpioState 0 "PWR_DOWN_REBOOT" 1 "DISABLED" 2 "CRITICAL" 3 "HEALTHY" ;
VAL_ 972 APS_apbStatusMonitorState 0 "STATE_UNKNOWN" 1 "STATE_PWR_OFF" 2 "STATE_INIT" 3 "STATE_NOMINAL" 4 "STATE_CRITICAL" 5 "STATE_SHUTTING_DOWN" 6 "STATE_RECOVERY" 7 "NUM_STATES" ;
VAL_ 972 APS_eacInternalState 0 "STATE_INIT" 1 "STATE_MOMENTARY" 2 "STATE_CONTINUOUS" 3 "STATE_AUTOPARK" 4 "STATE_INHIBIT" 5 "STATE_OVERRIDE" 6 "STATE_LSS" 7 "NUM_STATES" ;
VAL_ 972 APS_appGpioState 0 "PWR_DOWN_REBOOT" 1 "DISABLED" 2 "CRITICAL" 3 "HEALTHY" ;
VAL_ 972 APS_canMaster 0 "APS" 1 "APP" 2 "APB" 3 "SNA" ;
VAL_ 972 APS_vehBehaviorState 0 "STATE_UNKNOWN" 1 "STATE_APS_AVAILABLE" 2 "STATE_APS_CONTROL" 3 "STATE_APS_BRIDGE_APP" 4 "STATE_APS_BRIDGE_APB" 5 "STATE_APS_FAIL_SAFE" 6 "STATE_APS_OVERRIDE" 7 "STATE_SYSTEM_FAULT" 8 "NUM_STATES" ;
VAL_ 972 APS_appStatusMonitorState 0 "STATE_UNKNOWN" 1 "STATE_PWR_OFF" 2 "STATE_INIT" 3 "STATE_NOMINAL" 4 "STATE_CRITICAL" 5 "STATE_SHUTTING_DOWN" 6 "STATE_RECOVERY" 7 "NUM_STATES" ;
VAL_ 979 VCRIGHT_crashState 0 "IDLE" 1 "MINOR_1" 2 "MINOR_2" 3 "SEVERE" ;
VAL_ 979 VCRIGHT_crashDetectedType 0 "NONE" 1 "MINOR_1" 2 "MINOR_2" 3 "SEVERE" ;
VAL_ 984 UI_elevation 8191 "SNA" ;
